VERSION ""

NS_ :

BS_:

BU_:  Battery  Charger  Host

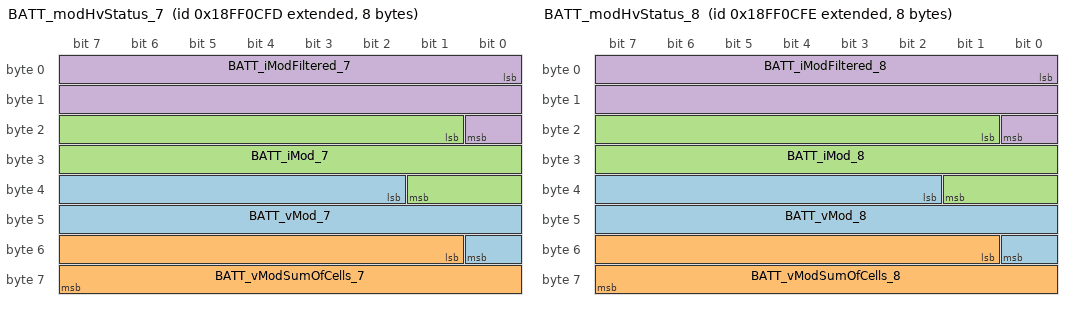
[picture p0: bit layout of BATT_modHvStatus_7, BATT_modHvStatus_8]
BO_ 2566851837 BATT_modHvStatus_7: 8 Battery
 SG_ BATT_vMod_7 : 34|15@1+ (0.01,0) [0|70] "V" Battery,Host
 SG_ BATT_vModSumOfCells_7 : 49|15@1+ (0.01,0) [0|70] "V" Battery,Host
 SG_ BATT_iMod_7 : 17|17@1- (0.01,-400) [-1055.36|255.35] "A" Battery,Host
 SG_ BATT_iModFiltered_7 : 0|17@1- (0.01,-400) [-1055.36|255.35] "A" Battery,Host

BO_ 2566851838 BATT_modHvStatus_8: 8 Battery
 SG_ BATT_vMod_8 : 34|15@1+ (0.01,0) [0|70] "V" Battery,Host
 SG_ BATT_vModSumOfCells_8 : 49|15@1+ (0.01,0) [0|70] "V" Battery,Host
 SG_ BATT_iMod_8 : 17|17@1- (0.01,-400) [-1055.36|255.35] "A" Battery,Host
 SG_ BATT_iModFiltered_8 : 0|17@1- (0.01,-400) [-1055.36|255.35] "A" Battery,Host

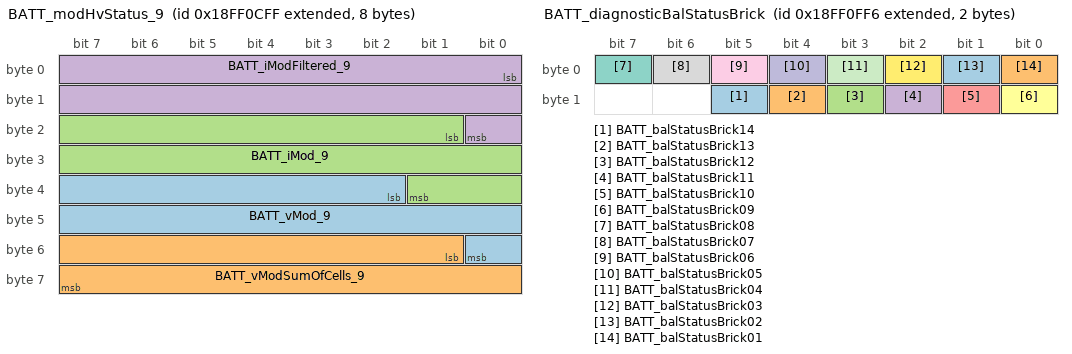
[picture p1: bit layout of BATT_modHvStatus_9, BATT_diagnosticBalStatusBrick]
BO_ 2566851839 BATT_modHvStatus_9: 8 Battery
 SG_ BATT_vMod_9 : 34|15@1+ (0.01,0) [0|70] "V" Battery,Host
 SG_ BATT_vModSumOfCells_9 : 49|15@1+ (0.01,0) [0|70] "V" Battery,Host
 SG_ BATT_iMod_9 : 17|17@1- (0.01,-400) [-1055.36|255.35] "A" Battery,Host
 SG_ BATT_iModFiltered_9 : 0|17@1- (0.01,-400) [-1055.36|255.35] "A" Battery,Host

BO_ 2566852342 BATT_version_0: 8 Battery
 SG_ BATT_bmsVariantCal_0 m2: 56|8@1+ (1,0) [0|255] "V" Host
 SG_ BATT_bmsVariantBl_0 m1: 56|8@1+ (1,0) [0|255] "V" Host
 SG_ BATT_bmsVariantApp_0 m0: 56|8@1+ (1,0) [0|255] "V" Host
 SG_ BATT_swVerSubMinorApp_0 m0: 24|8@1+ (1,0) [0|255] "" Host
 SG_ BATT_swVerMinorApp_0 m0: 16|8@1+ (1,0) [0|255] "" Host
 SG_ BATT_swVerMajorApp_0 m0: 8|8@1+ (1,0) [0|255] "" Host
 SG_ BATT_HwVerApp_0 m0: 32|8@1+ (1,0) [0|255] "" Host
 SG_ BATT_swVerAbsCusApp_0 m0: 40|8@1+ (1,0) [0|255] "" Host
 SG_ BATT_swVerAbsIntApp_0 m0: 48|8@1+ (1,0) [0|255] "" Host
 SG_ BATT_swVerSubMinorBl_0 m1: 24|8@1+ (1,0) [0|255] "" Host
 SG_ BATT_swVerMinorBl_0 m1: 16|8@1+ (1,0) [0|255] "" Host
 SG_ BATT_swVerMajorBl_0 m1: 8|8@1+ (1,0) [0|255] "" Host
 SG_ BATT_HwVerBl_0 m1: 32|8@1+ (1,0) [0|255] "" Host
 SG_ BATT_swVerAbsCusBl_0 m1: 40|8@1+ (1,0) [0|255] "" Host
 SG_ BATT_swVerAbsIntBl_0 m1: 48|8@1+ (1,0) [0|255] "" Host
 SG_ BATT_swVerSubMinorCal_0 m2: 24|8@1+ (1,0) [0|255] "" Host
 SG_ BATT_swVerMinorCal_0 m2: 16|8@1+ (1,0) [0|255] "" Host
 SG_ BATT_swVerMajorCal_0 m2: 8|8@1+ (1,0) [0|255] "" Host
 SG_ BATT_HwVerCal_0 m2: 32|8@1+ (1,0) [0|255] "" Host
 SG_ BATT_swVerAbsCusCal_0 m2: 40|8@1+ (1,0) [0|255] "" Host
 SG_ BATT_swVerAbsIntCal_0 m2: 48|8@1+ (1,0) [0|255] "" Host
 SG_ multiplexorvr_0 M: 0|2@1+ (1,0) [0|2] "" Host

BO_ 2566852343 BATT_version_1: 8 Battery
 SG_ BATT_bmsVariantCal_1 m2: 56|8@1+ (1,0) [0|255] "V" Host
 SG_ BATT_bmsVariantBl_1 m1: 56|8@1+ (1,0) [0|255] "V" Host
 SG_ BATT_bmsVariantApp_1 m0: 56|8@1+ (1,0) [0|255] "V" Host
 SG_ BATT_swVerSubMinorApp_1 m0: 24|8@1+ (1,0) [0|255] "" Host
 SG_ BATT_swVerMinorApp_1 m0: 16|8@1+ (1,0) [0|255] "" Host
 SG_ BATT_swVerMajorApp_1 m0: 8|8@1+ (1,0) [0|255] "" Host
 SG_ BATT_HwVerApp_1 m0: 32|8@1+ (1,0) [0|255] "" Host
 SG_ BATT_swVerAbsCusApp_1 m0: 40|8@1+ (1,0) [0|255] "" Host
 SG_ BATT_swVerAbsIntApp_1 m0: 48|8@1+ (1,0) [0|255] "" Host
 SG_ BATT_swVerSubMinorBl_1 m1: 24|8@1+ (1,0) [0|255] "" Host
 SG_ BATT_swVerMinorBl_1 m1: 16|8@1+ (1,0) [0|255] "" Host
 SG_ BATT_swVerMajorBl_1 m1: 8|8@1+ (1,0) [0|255] "" Host
 SG_ BATT_HwVerBl_1 m1: 32|8@1+ (1,0) [0|255] "" Host
 SG_ BATT_swVerAbsCusBl_1 m1: 40|8@1+ (1,0) [0|255] "" Host
 SG_ BATT_swVerAbsIntBl_1 m1: 48|8@1+ (1,0) [0|255] "" Host
 SG_ BATT_swVerSubMinorCal_1 m2: 24|8@1+ (1,0) [0|255] "" Host
 SG_ BATT_swVerMinorCal_1 m2: 16|8@1+ (1,0) [0|255] "" Host
 SG_ BATT_swVerMajorCal_1 m2: 8|8@1+ (1,0) [0|255] "" Host
 SG_ BATT_HwVerCal_1 m2: 32|8@1+ (1,0) [0|255] "" Host
 SG_ BATT_swVerAbsCusCal_1 m2: 40|8@1+ (1,0) [0|255] "" Host
 SG_ BATT_swVerAbsIntCal_1 m2: 48|8@1+ (1,0) [0|255] "" Host
 SG_ multiplexorvr_1 M: 0|2@1+ (1,0) [0|2] "" Host

BO_ 2566852344 BATT_version_2: 8 Battery
 SG_ BATT_bmsVariantCal_2 m2: 56|8@1+ (1,0) [0|255] "V" Host
 SG_ BATT_bmsVariantBl_2 m1: 56|8@1+ (1,0) [0|255] "V" Host
 SG_ BATT_bmsVariantApp_2 m0: 56|8@1+ (1,0) [0|255] "V" Host
 SG_ BATT_swVerSubMinorApp_2 m0: 24|8@1+ (1,0) [0|255] "" Host
 SG_ BATT_swVerMinorApp_2 m0: 16|8@1+ (1,0) [0|255] "" Host
 SG_ BATT_swVerMajorApp_2 m0: 8|8@1+ (1,0) [0|255] "" Host
 SG_ BATT_HwVerApp_2 m0: 32|8@1+ (1,0) [0|255] "" Host
 SG_ BATT_swVerAbsCusApp_2 m0: 40|8@1+ (1,0) [0|255] "" Host
 SG_ BATT_swVerAbsIntApp_2 m0: 48|8@1+ (1,0) [0|255] "" Host
 SG_ BATT_swVerSubMinorBl_2 m1: 24|8@1+ (1,0) [0|255] "" Host
 SG_ BATT_swVerMinorBl_2 m1: 16|8@1+ (1,0) [0|255] "" Host
 SG_ BATT_swVerMajorBl_2 m1: 8|8@1+ (1,0) [0|255] "" Host
 SG_ BATT_HwVerBl_2 m1: 32|8@1+ (1,0) [0|255] "" Host
 SG_ BATT_swVerAbsCusBl_2 m1: 40|8@1+ (1,0) [0|255] "" Host
 SG_ BATT_swVerAbsIntBl_2 m1: 48|8@1+ (1,0) [0|255] "" Host
 SG_ BATT_swVerSubMinorCal_2 m2: 24|8@1+ (1,0) [0|255] "" Host
 SG_ BATT_swVerMinorCal_2 m2: 16|8@1+ (1,0) [0|255] "" Host
 SG_ BATT_swVerMajorCal_2 m2: 8|8@1+ (1,0) [0|255] "" Host
 SG_ BATT_HwVerCal_2 m2: 32|8@1+ (1,0) [0|255] "" Host
 SG_ BATT_swVerAbsCusCal_2 m2: 40|8@1+ (1,0) [0|255] "" Host
 SG_ BATT_swVerAbsIntCal_2 m2: 48|8@1+ (1,0) [0|255] "" Host
 SG_ multiplexorvr_2 M: 0|2@1+ (1,0) [0|2] "" Host

BO_ 2566852345 BATT_version_3: 8 Battery
 SG_ BATT_bmsVariantCal_3 m2: 56|8@1+ (1,0) [0|255] "V" Host
 SG_ BATT_bmsVariantBl_3 m1: 56|8@1+ (1,0) [0|255] "V" Host
 SG_ BATT_bmsVariantApp_3 m0: 56|8@1+ (1,0) [0|255] "V" Host
 SG_ BATT_swVerSubMinorApp_3 m0: 24|8@1+ (1,0) [0|255] "" Host
 SG_ BATT_swVerMinorApp_3 m0: 16|8@1+ (1,0) [0|255] "" Host
 SG_ BATT_swVerMajorApp_3 m0: 8|8@1+ (1,0) [0|255] "" Host
 SG_ BATT_HwVerApp_3 m0: 32|8@1+ (1,0) [0|255] "" Host
 SG_ BATT_swVerAbsCusApp_3 m0: 40|8@1+ (1,0) [0|255] "" Host
 SG_ BATT_swVerAbsIntApp_3 m0: 48|8@1+ (1,0) [0|255] "" Host
 SG_ BATT_swVerSubMinorBl_3 m1: 24|8@1+ (1,0) [0|255] "" Host
 SG_ BATT_swVerMinorBl_3 m1: 16|8@1+ (1,0) [0|255] "" Host
 SG_ BATT_swVerMajorBl_3 m1: 8|8@1+ (1,0) [0|255] "" Host
 SG_ BATT_HwVerBl_3 m1: 32|8@1+ (1,0) [0|255] "" Host
 SG_ BATT_swVerAbsCusBl_3 m1: 40|8@1+ (1,0) [0|255] "" Host
 SG_ BATT_swVerAbsIntBl_3 m1: 48|8@1+ (1,0) [0|255] "" Host
 SG_ BATT_swVerSubMinorCal_3 m2: 24|8@1+ (1,0) [0|255] "" Host
 SG_ BATT_swVerMinorCal_3 m2: 16|8@1+ (1,0) [0|255] "" Host
 SG_ BATT_swVerMajorCal_3 m2: 8|8@1+ (1,0) [0|255] "" Host
 SG_ BATT_HwVerCal_3 m2: 32|8@1+ (1,0) [0|255] "" Host
 SG_ BATT_swVerAbsCusCal_3 m2: 40|8@1+ (1,0) [0|255] "" Host
 SG_ BATT_swVerAbsIntCal_3 m2: 48|8@1+ (1,0) [0|255] "" Host
 SG_ multiplexorvr_3 M: 0|2@1+ (1,0) [0|2] "" Host

BO_ 2566852346 BATT_version_4: 8 Battery
 SG_ BATT_bmsVariantCal_4 m2: 56|8@1+ (1,0) [0|255] "V" Host
 SG_ BATT_bmsVariantBl_4 m1: 56|8@1+ (1,0) [0|255] "V" Host
 SG_ BATT_bmsVariantApp_4 m0: 56|8@1+ (1,0) [0|255] "V" Host
 SG_ BATT_swVerSubMinorApp_4 m0: 24|8@1+ (1,0) [0|255] "" Host
 SG_ BATT_swVerMinorApp_4 m0: 16|8@1+ (1,0) [0|255] "" Host
 SG_ BATT_swVerMajorApp_4 m0: 8|8@1+ (1,0) [0|255] "" Host
 SG_ BATT_HwVerApp_4 m0: 32|8@1+ (1,0) [0|255] "" Host
 SG_ BATT_swVerAbsCusApp_4 m0: 40|8@1+ (1,0) [0|255] "" Host
 SG_ BATT_swVerAbsIntApp_4 m0: 48|8@1+ (1,0) [0|255] "" Host
 SG_ BATT_swVerSubMinorBl_4 m1: 24|8@1+ (1,0) [0|255] "" Host
 SG_ BATT_swVerMinorBl_4 m1: 16|8@1+ (1,0) [0|255] "" Host
 SG_ BATT_swVerMajorBl_4 m1: 8|8@1+ (1,0) [0|255] "" Host
 SG_ BATT_HwVerBl_4 m1: 32|8@1+ (1,0) [0|255] "" Host
 SG_ BATT_swVerAbsCusBl_4 m1: 40|8@1+ (1,0) [0|255] "" Host
 SG_ BATT_swVerAbsIntBl_4 m1: 48|8@1+ (1,0) [0|255] "" Host
 SG_ BATT_swVerSubMinorCal_4 m2: 24|8@1+ (1,0) [0|255] "" Host
 SG_ BATT_swVerMinorCal_4 m2: 16|8@1+ (1,0) [0|255] "" Host
 SG_ BATT_swVerMajorCal_4 m2: 8|8@1+ (1,0) [0|255] "" Host
 SG_ BATT_HwVerCal_4 m2: 32|8@1+ (1,0) [0|255] "" Host
 SG_ BATT_swVerAbsCusCal_4 m2: 40|8@1+ (1,0) [0|255] "" Host
 SG_ BATT_swVerAbsIntCal_4 m2: 48|8@1+ (1,0) [0|255] "" Host
 SG_ multiplexorvr_4 M: 0|2@1+ (1,0) [0|2] "" Host

BO_ 2566852347 BATT_version_5: 8 Battery
 SG_ BATT_bmsVariantCal_5 m2: 56|8@1+ (1,0) [0|255] "V" Host
 SG_ BATT_bmsVariantBl_5 m1: 56|8@1+ (1,0) [0|255] "V" Host
 SG_ BATT_bmsVariantApp_5 m0: 56|8@1+ (1,0) [0|255] "V" Host
 SG_ BATT_swVerSubMinorApp_5 m0: 24|8@1+ (1,0) [0|255] "" Host
 SG_ BATT_swVerMinorApp_5 m0: 16|8@1+ (1,0) [0|255] "" Host
 SG_ BATT_swVerMajorApp_5 m0: 8|8@1+ (1,0) [0|255] "" Host
 SG_ BATT_HwVerApp_5 m0: 32|8@1+ (1,0) [0|255] "" Host
 SG_ BATT_swVerAbsCusApp_5 m0: 40|8@1+ (1,0) [0|255] "" Host
 SG_ BATT_swVerAbsIntApp_5 m0: 48|8@1+ (1,0) [0|255] "" Host
 SG_ BATT_swVerSubMinorBl_5 m1: 24|8@1+ (1,0) [0|255] "" Host
 SG_ BATT_swVerMinorBl_5 m1: 16|8@1+ (1,0) [0|255] "" Host
 SG_ BATT_swVerMajorBl_5 m1: 8|8@1+ (1,0) [0|255] "" Host
 SG_ BATT_HwVerBl_5 m1: 32|8@1+ (1,0) [0|255] "" Host
 SG_ BATT_swVerAbsCusBl_5 m1: 40|8@1+ (1,0) [0|255] "" Host
 SG_ BATT_swVerAbsIntBl_5 m1: 48|8@1+ (1,0) [0|255] "" Host
 SG_ BATT_swVerSubMinorCal_5 m2: 24|8@1+ (1,0) [0|255] "" Host
 SG_ BATT_swVerMinorCal_5 m2: 16|8@1+ (1,0) [0|255] "" Host
 SG_ BATT_swVerMajorCal_5 m2: 8|8@1+ (1,0) [0|255] "" Host
 SG_ BATT_HwVerCal_5 m2: 32|8@1+ (1,0) [0|255] "" Host
 SG_ BATT_swVerAbsCusCal_5 m2: 40|8@1+ (1,0) [0|255] "" Host
 SG_ BATT_swVerAbsIntCal_5 m2: 48|8@1+ (1,0) [0|255] "" Host
 SG_ multiplexorvr_5 M: 0|2@1+ (1,0) [0|2] "" Host

BO_ 2566852348 BATT_version_6: 8 Battery
 SG_ BATT_bmsVariantCal_6 m2: 56|8@1+ (1,0) [0|255] "V" Host
 SG_ BATT_bmsVariantBl_6 m1: 56|8@1+ (1,0) [0|255] "V" Host
 SG_ BATT_bmsVariantApp_6 m0: 56|8@1+ (1,0) [0|255] "V" Host
 SG_ BATT_swVerSubMinorApp_6 m0: 24|8@1+ (1,0) [0|255] "" Host
 SG_ BATT_swVerMinorApp_6 m0: 16|8@1+ (1,0) [0|255] "" Host
 SG_ BATT_swVerMajorApp_6 m0: 8|8@1+ (1,0) [0|255] "" Host
 SG_ BATT_HwVerApp_6 m0: 32|8@1+ (1,0) [0|255] "" Host
 SG_ BATT_swVerAbsCusApp_6 m0: 40|8@1+ (1,0) [0|255] "" Host
 SG_ BATT_swVerAbsIntApp_6 m0: 48|8@1+ (1,0) [0|255] "" Host
 SG_ BATT_swVerSubMinorBl_6 m1: 24|8@1+ (1,0) [0|255] "" Host
 SG_ BATT_swVerMinorBl_6 m1: 16|8@1+ (1,0) [0|255] "" Host
 SG_ BATT_swVerMajorBl_6 m1: 8|8@1+ (1,0) [0|255] "" Host
 SG_ BATT_HwVerBl_6 m1: 32|8@1+ (1,0) [0|255] "" Host
 SG_ BATT_swVerAbsCusBl_6 m1: 40|8@1+ (1,0) [0|255] "" Host
 SG_ BATT_swVerAbsIntBl_6 m1: 48|8@1+ (1,0) [0|255] "" Host
 SG_ BATT_swVerSubMinorCal_6 m2: 24|8@1+ (1,0) [0|255] "" Host
 SG_ BATT_swVerMinorCal_6 m2: 16|8@1+ (1,0) [0|255] "" Host
 SG_ BATT_swVerMajorCal_6 m2: 8|8@1+ (1,0) [0|255] "" Host
 SG_ BATT_HwVerCal_6 m2: 32|8@1+ (1,0) [0|255] "" Host
 SG_ BATT_swVerAbsCusCal_6 m2: 40|8@1+ (1,0) [0|255] "" Host
 SG_ BATT_swVerAbsIntCal_6 m2: 48|8@1+ (1,0) [0|255] "" Host
 SG_ multiplexorvr_6 M: 0|2@1+ (1,0) [0|2] "" Host

BO_ 2566852349 BATT_version_7: 8 Battery
 SG_ BATT_bmsVariantCal_7 m2: 56|8@1+ (1,0) [0|255] "V" Host
 SG_ BATT_bmsVariantBl_7 m1: 56|8@1+ (1,0) [0|255] "V" Host
 SG_ BATT_bmsVariantApp_7 m0: 56|8@1+ (1,0) [0|255] "V" Host
 SG_ BATT_swVerSubMinorApp_7 m0: 24|8@1+ (1,0) [0|255] "" Host
 SG_ BATT_swVerMinorApp_7 m0: 16|8@1+ (1,0) [0|255] "" Host
 SG_ BATT_swVerMajorApp_7 m0: 8|8@1+ (1,0) [0|255] "" Host
 SG_ BATT_HwVerApp_7 m0: 32|8@1+ (1,0) [0|255] "" Host
 SG_ BATT_swVerAbsCusApp_7 m0: 40|8@1+ (1,0) [0|255] "" Host
 SG_ BATT_swVerAbsIntApp_7 m0: 48|8@1+ (1,0) [0|255] "" Host
 SG_ BATT_swVerSubMinorBl_7 m1: 24|8@1+ (1,0) [0|255] "" Host
 SG_ BATT_swVerMinorBl_7 m1: 16|8@1+ (1,0) [0|255] "" Host
 SG_ BATT_swVerMajorBl_7 m1: 8|8@1+ (1,0) [0|255] "" Host
 SG_ BATT_HwVerBl_7 m1: 32|8@1+ (1,0) [0|255] "" Host
 SG_ BATT_swVerAbsCusBl_7 m1: 40|8@1+ (1,0) [0|255] "" Host
 SG_ BATT_swVerAbsIntBl_7 m1: 48|8@1+ (1,0) [0|255] "" Host
 SG_ BATT_swVerSubMinorCal_7 m2: 24|8@1+ (1,0) [0|255] "" Host
 SG_ BATT_swVerMinorCal_7 m2: 16|8@1+ (1,0) [0|255] "" Host
 SG_ BATT_swVerMajorCal_7 m2: 8|8@1+ (1,0) [0|255] "" Host
 SG_ BATT_HwVerCal_7 m2: 32|8@1+ (1,0) [0|255] "" Host
 SG_ BATT_swVerAbsCusCal_7 m2: 40|8@1+ (1,0) [0|255] "" Host
 SG_ BATT_swVerAbsIntCal_7 m2: 48|8@1+ (1,0) [0|255] "" Host
 SG_ multiplexorvr_7 M: 0|2@1+ (1,0) [0|2] "" Host

BO_ 2566852350 BATT_version_8: 8 Battery
 SG_ BATT_bmsVariantCal_8 m2: 56|8@1+ (1,0) [0|255] "V" Host
 SG_ BATT_bmsVariantBl_8 m1: 56|8@1+ (1,0) [0|255] "V" Host
 SG_ BATT_bmsVariantApp_8 m0: 56|8@1+ (1,0) [0|255] "V" Host
 SG_ BATT_swVerSubMinorApp_8 m0: 24|8@1+ (1,0) [0|255] "" Host
 SG_ BATT_swVerMinorApp_8 m0: 16|8@1+ (1,0) [0|255] "" Host
 SG_ BATT_swVerMajorApp_8 m0: 8|8@1+ (1,0) [0|255] "" Host
 SG_ BATT_HwVerApp_8 m0: 32|8@1+ (1,0) [0|255] "" Host
 SG_ BATT_swVerAbsCusApp_8 m0: 40|8@1+ (1,0) [0|255] "" Host
 SG_ BATT_swVerAbsIntApp_8 m0: 48|8@1+ (1,0) [0|255] "" Host
 SG_ BATT_swVerSubMinorBl_8 m1: 24|8@1+ (1,0) [0|255] "" Host
 SG_ BATT_swVerMinorBl_8 m1: 16|8@1+ (1,0) [0|255] "" Host
 SG_ BATT_swVerMajorBl_8 m1: 8|8@1+ (1,0) [0|255] "" Host
 SG_ BATT_HwVerBl_8 m1: 32|8@1+ (1,0) [0|255] "" Host
 SG_ BATT_swVerAbsCusBl_8 m1: 40|8@1+ (1,0) [0|255] "" Host
 SG_ BATT_swVerAbsIntBl_8 m1: 48|8@1+ (1,0) [0|255] "" Host
 SG_ BATT_swVerSubMinorCal_8 m2: 24|8@1+ (1,0) [0|255] "" Host
 SG_ BATT_swVerMinorCal_8 m2: 16|8@1+ (1,0) [0|255] "" Host
 SG_ BATT_swVerMajorCal_8 m2: 8|8@1+ (1,0) [0|255] "" Host
 SG_ BATT_HwVerCal_8 m2: 32|8@1+ (1,0) [0|255] "" Host
 SG_ BATT_swVerAbsCusCal_8 m2: 40|8@1+ (1,0) [0|255] "" Host
 SG_ BATT_swVerAbsIntCal_8 m2: 48|8@1+ (1,0) [0|255] "" Host
 SG_ multiplexorvr_8 M: 0|2@1+ (1,0) [0|2] "" Host

BO_ 2566852351 BATT_version_9: 8 Battery
 SG_ BATT_bmsVariantCal_9 m2: 56|8@1+ (1,0) [0|255] "V" Host
 SG_ BATT_bmsVariantBl_9 m1: 56|8@1+ (1,0) [0|255] "V" Host
 SG_ BATT_bmsVariantApp_9 m0: 56|8@1+ (1,0) [0|255] "V" Host
 SG_ BATT_swVerSubMinorApp_9 m0: 24|8@1+ (1,0) [0|255] "" Host
 SG_ BATT_swVerMinorApp_9 m0: 16|8@1+ (1,0) [0|255] "" Host
 SG_ BATT_swVerMajorApp_9 m0: 8|8@1+ (1,0) [0|255] "" Host
 SG_ BATT_HwVerApp_9 m0: 32|8@1+ (1,0) [0|255] "" Host
 SG_ BATT_swVerAbsCusApp_9 m0: 40|8@1+ (1,0) [0|255] "" Host
 SG_ BATT_swVerAbsIntApp_9 m0: 48|8@1+ (1,0) [0|255] "" Host
 SG_ BATT_swVerSubMinorBl_9 m1: 24|8@1+ (1,0) [0|255] "" Host
 SG_ BATT_swVerMinorBl_9 m1: 16|8@1+ (1,0) [0|255] "" Host
 SG_ BATT_swVerMajorBl_9 m1: 8|8@1+ (1,0) [0|255] "" Host
 SG_ BATT_HwVerBl_9 m1: 32|8@1+ (1,0) [0|255] "" Host
 SG_ BATT_swVerAbsCusBl_9 m1: 40|8@1+ (1,0) [0|255] "" Host
 SG_ BATT_swVerAbsIntBl_9 m1: 48|8@1+ (1,0) [0|255] "" Host
 SG_ BATT_swVerSubMinorCal_9 m2: 24|8@1+ (1,0) [0|255] "" Host
 SG_ BATT_swVerMinorCal_9 m2: 16|8@1+ (1,0) [0|255] "" Host
 SG_ BATT_swVerMajorCal_9 m2: 8|8@1+ (1,0) [0|255] "" Host
 SG_ BATT_HwVerCal_9 m2: 32|8@1+ (1,0) [0|255] "" Host
 SG_ BATT_swVerAbsCusCal_9 m2: 40|8@1+ (1,0) [0|255] "" Host
 SG_ BATT_swVerAbsIntCal_9 m2: 48|8@1+ (1,0) [0|255] "" Host
 SG_ multiplexorvr_9 M: 0|2@1+ (1,0) [0|2] "" Host

BO_ 2566852598 BATT_diagnosticBalStatusBrick: 2 Battery
 SG_ BATT_balStatusBrick14 : 13|1@1+ (1,0) [0|1] "" Host
 SG_ BATT_balStatusBrick13 : 12|1@1+ (1,0) [0|1] "" Host
 SG_ BATT_balStatusBrick12 : 11|1@1+ (1,0) [0|1] "" Host
 SG_ BATT_balStatusBrick11 : 10|1@1+ (1,0) [0|1] "" Host
 SG_ BATT_balStatusBrick10 : 9|1@1+ (1,0) [0|1] "" Host
 SG_ BATT_balStatusBrick09 : 8|1@1+ (1,0) [0|1] "" Host
 SG_ BATT_balStatusBrick08 : 7|1@1+ (1,0) [0|1] "" Host
 SG_ BATT_balStatusBrick07 : 6|1@1+ (1,0) [0|1] "" Host
 SG_ BATT_balStatusBrick06 : 5|1@1+ (1,0) [0|1] "" Host
 SG_ BATT_balStatusBrick05 : 4|1@1+ (1,0) [0|1] "" Host
 SG_ BATT_balStatusBrick04 : 3|1@1+ (1,0) [0|1] "" Host
 SG_ BATT_balStatusBrick03 : 2|1@1+ (1,0) [0|1] "" Host
 SG_ BATT_balStatusBrick02 : 1|1@1+ (1,0) [0|1] "" Host
 SG_ BATT_balStatusBrick01 : 0|1@1+ (1,0) [0|1] "" Host

BO_ 2566852854 BATT_eventMatrix_A_0: 8 Battery
 SG_ BATT_packModIdFault_0 : 8|1@1+ (1,0) [0|1] "" Host
 SG_ BATT_packModExitedFromBus_0 : 16|1@1+ (1,0) [0|1] "" Host
 SG_ BATT_packFetChgWelded_0 : 35|1@1+ (1,0) [0|1] "" Host
 SG_ BATT_packFetDsgWelded_0 : 36|1@1+ (1,0) [0|1] "" Host
 SG_ BATT_fetDsgShortedAux_0 : 63|1@1+ (1,0) [0|1] "" Host
 SG_ BATT_fetChgShortedAux_0 : 25|1@1+ (1,0) [0|1] "" Host
 SG_ BATT_prechargeFetFail_0 : 39|1@1+ (1,0) [0|1] "" Host
 SG_ BATT_abnormalResetReason_0 : 31|1@1+ (1,0) [0|1] "" Host
 SG_ BATT_prechargeTooSlow_0 : 49|1@1+ (1,0) [0|1] "" Host
 SG_ BATT_prechargeTooFast_0 : 50|1@1+ (1,0) [0|1] "" Host
 SG_ BATT_prechargeTimeout_0 : 51|1@1+ (1,0) [0|1] "" Host
 SG_ BATT_fetChgShorted_0 : 23|1@1+ (1,0) [0|1] "" Host
 SG_ BATT_fetChgFailToClose_0 : 22|1@1+ (1,0) [0|1] "" Host
 SG_ BATT_packModSelectFault_0 : 21|1@1+ (1,0) [0|1] "" Host
 SG_ BATT_packModConnectFault_0 : 20|1@1+ (1,0) [0|1] "" Host
 SG_ BATT_packModMIA_0 : 19|1@1+ (1,0) [0|1] "" Host
 SG_ BATT_packModImbalance_0 : 18|1@1+ (1,0) [0|1] "" Host
 SG_ BATT_afeFault_0 : 17|1@1+ (1,0) [0|1] "" Host
 SG_ BATT_chargerMIA_0 : 60|1@1+ (1,0) [0|1] "" Host
 SG_ BATT_chargerError_0 : 59|1@1+ (1,0) [0|1] "" Host
 SG_ BATT_vBrickUnderWar_0 : 58|1@1+ (1,0) [0|1] "" Host
 SG_ BATT_vBrickUnderSev_0 : 57|1@1+ (1,0) [0|1] "" Host
 SG_ BATT_vBrickUnderMod_0 : 56|1@1+ (1,0) [0|1] "" Host
 SG_ BATT_vBrickOverWar_0 : 55|1@1+ (1,0) [0|1] "" Host
 SG_ BATT_vBrickOverSev_0 : 54|1@1+ (1,0) [0|1] "" Host
 SG_ BATT_vBrickOverMod_0 : 53|1@1+ (1,0) [0|1] "" Host
 SG_ BATT_vBrickImbalance_0 : 52|1@1+ (1,0) [0|1] "" Host
 SG_ BATT_loggerAlmostFull_0 : 61|1@1+ (1,0) [0|1] "" Host
 SG_ BATT_tempModuleUnderWar_0 : 48|1@1+ (1,0) [0|1] "" Host
 SG_ BATT_tempModuleUnderSev_0 : 47|1@1+ (1,0) [0|1] "" Host
 SG_ BATT_tempModuleUnderMod_0 : 46|1@1+ (1,0) [0|1] "" Host
 SG_ BATT_tempModuleOverWar_0 : 45|1@1+ (1,0) [0|1] "" Host
 SG_ BATT_tempModuleOverSev_0 : 44|1@1+ (1,0) [0|1] "" Host
 SG_ BATT_tempModuleOverMod_0 : 43|1@1+ (1,0) [0|1] "" Host
 SG_ BATT_tempBrickImbalance_0 : 42|1@1+ (1,0) [0|1] "" Host
 SG_ BATT_taskLockupError_0 : 41|1@1+ (1,0) [0|1] "" Host
 SG_ BATT_tempBoardOverWar_0 : 40|1@1+ (1,0) [0|1] "" Host
 SG_ BATT_tempBoardOverSev_0 : 38|1@1+ (1,0) [0|1] "" Host
 SG_ BATT_tempBoardOverMod_0 : 37|1@1+ (1,0) [0|1] "" Host
 SG_ BATT_sensePackVoltError_0 : 34|1@1+ (1,0) [0|1] "" Host
 SG_ BATT_senseLoadVoltError_0 : 33|1@1+ (1,0) [0|1] "" Host
 SG_ BATT_loggerFull_0 : 62|1@1+ (1,0) [0|1] "" Host
 SG_ BATT_senseCurrentError_0 : 32|1@1+ (1,0) [0|1] "" Host
 SG_ BATT_senseBrickTempError_0 : 30|1@1+ (1,0) [0|1] "" Host
 SG_ BATT_resPackHigh_0 : 29|1@1+ (1,0) [0|1] "" Host
 SG_ BATT_ramOverUtilError_0 : 28|1@1+ (1,0) [0|1] "" Host
 SG_ BATT_powerPackInsufficient_0 : 27|1@1+ (1,0) [0|1] "" Host
 SG_ BATT_packCellSoftShort_0 : 26|1@1+ (1,0) [0|1] "" Host
 SG_ BATT_iOverHardware_0 : 24|1@1+ (1,0) [0|1] "" Host
 SG_ BATT_fetOverTemp_0 : 15|1@1+ (1,0) [0|1] "" Host
 SG_ BATT_iOverDischarge_0 : 14|1@1+ (1,0) [0|1] "" Host
 SG_ BATT_iOverCharge_0 : 13|1@1+ (1,0) [0|1] "" Host
 SG_ BATT_inverterDriveMIA_0 : 12|1@1+ (1,0) [0|1] "" Host
 SG_ BATT_iUnderCharge_0 : 11|1@1+ (1,0) [0|1] "" Host
 SG_ BATT_hostMIA_0 : 10|1@1+ (1,0) [0|1] "" Host
 SG_ BATT_fetDsgShorted_0 : 7|1@1+ (1,0) [0|1] "" Host
 SG_ BATT_fetDsgFailToClose_0 : 6|1@1+ (1,0) [0|1] "" Host
 SG_ BATT_capLow_0 : 5|1@1+ (1,0) [0|1] "" Host
 SG_ BATT_brickOverDischarge_0 : 4|1@1+ (1,0) [0|1] "" Host
 SG_ BATT_brickOverCharge_0 : 3|1@1+ (1,0) [0|1] "" Host
 SG_ BATT_bmsProcessorError_0 : 2|1@1+ (1,0) [0|1] "" Host
 SG_ BATT_bmsMemoryError_0 : 1|1@1+ (1,0) [0|1] "" Host
 SG_ BATT_afeError_0 : 0|1@1+ (1,0) [0|1] "" Host

BO_ 2566852855 BATT_eventMatrix_A_1: 8 Battery
 SG_ BATT_packModIdFault_1 : 8|1@1+ (1,0) [0|1] "" Host
 SG_ BATT_packModExitedFromBus_1 : 16|1@1+ (1,0) [0|1] "" Host
 SG_ BATT_packFetChgWelded_1 : 35|1@1+ (1,0) [0|1] "" Host
 SG_ BATT_packFetDsgWelded_1 : 36|1@1+ (1,0) [0|1] "" Host
 SG_ BATT_fetDsgShortedAux_1 : 63|1@1+ (1,0) [0|1] "" Host
 SG_ BATT_fetChgShortedAux_1 : 25|1@1+ (1,0) [0|1] "" Host
 SG_ BATT_prechargeFetFail_1 : 39|1@1+ (1,0) [0|1] "" Host
 SG_ BATT_abnormalResetReason_1 : 31|1@1+ (1,0) [0|1] "" Host
 SG_ BATT_prechargeTooSlow_1 : 49|1@1+ (1,0) [0|1] "" Host
 SG_ BATT_prechargeTooFast_1 : 50|1@1+ (1,0) [0|1] "" Host
 SG_ BATT_prechargeTimeout_1 : 51|1@1+ (1,0) [0|1] "" Host
 SG_ BATT_fetChgShorted_1 : 23|1@1+ (1,0) [0|1] "" Host
 SG_ BATT_fetChgFailToClose_1 : 22|1@1+ (1,0) [0|1] "" Host
 SG_ BATT_packModSelectFault_1 : 21|1@1+ (1,0) [0|1] "" Host
 SG_ BATT_packModConnectFault_1 : 20|1@1+ (1,0) [0|1] "" Host
 SG_ BATT_packModMIA_1 : 19|1@1+ (1,0) [0|1] "" Host
 SG_ BATT_packModImbalance_1 : 18|1@1+ (1,0) [0|1] "" Host
 SG_ BATT_afeFault_1 : 17|1@1+ (1,0) [0|1] "" Host
 SG_ BATT_chargerMIA_1 : 60|1@1+ (1,0) [0|1] "" Host
 SG_ BATT_chargerError_1 : 59|1@1+ (1,0) [0|1] "" Host
 SG_ BATT_vBrickUnderWar_1 : 58|1@1+ (1,0) [0|1] "" Host
 SG_ BATT_vBrickUnderSev_1 : 57|1@1+ (1,0) [0|1] "" Host
 SG_ BATT_vBrickUnderMod_1 : 56|1@1+ (1,0) [0|1] "" Host
 SG_ BATT_vBrickOverWar_1 : 55|1@1+ (1,0) [0|1] "" Host
 SG_ BATT_vBrickOverSev_1 : 54|1@1+ (1,0) [0|1] "" Host
 SG_ BATT_vBrickOverMod_1 : 53|1@1+ (1,0) [0|1] "" Host
 SG_ BATT_vBrickImbalance_1 : 52|1@1+ (1,0) [0|1] "" Host
 SG_ BATT_loggerAlmostFull_1 : 61|1@1+ (1,0) [0|1] "" Host
 SG_ BATT_tempModuleUnderWar_1 : 48|1@1+ (1,0) [0|1] "" Host
 SG_ BATT_tempModuleUnderSev_1 : 47|1@1+ (1,0) [0|1] "" Host
 SG_ BATT_tempModuleUnderMod_1 : 46|1@1+ (1,0) [0|1] "" Host
 SG_ BATT_tempModuleOverWar_1 : 45|1@1+ (1,0) [0|1] "" Host
 SG_ BATT_tempModuleOverSev_1 : 44|1@1+ (1,0) [0|1] "" Host
 SG_ BATT_tempModuleOverMod_1 : 43|1@1+ (1,0) [0|1] "" Host
 SG_ BATT_tempBrickImbalance_1 : 42|1@1+ (1,0) [0|1] "" Host
 SG_ BATT_taskLockupError_1 : 41|1@1+ (1,0) [0|1] "" Host
 SG_ BATT_tempBoardOverWar_1 : 40|1@1+ (1,0) [0|1] "" Host
 SG_ BATT_tempBoardOverSev_1 : 38|1@1+ (1,0) [0|1] "" Host
 SG_ BATT_tempBoardOverMod_1 : 37|1@1+ (1,0) [0|1] "" Host
 SG_ BATT_sensePackVoltError_1 : 34|1@1+ (1,0) [0|1] "" Host
 SG_ BATT_senseLoadVoltError_1 : 33|1@1+ (1,0) [0|1] "" Host
 SG_ BATT_loggerFull_1 : 62|1@1+ (1,0) [0|1] "" Host
 SG_ BATT_senseCurrentError_1 : 32|1@1+ (1,0) [0|1] "" Host
 SG_ BATT_senseBrickTempError_1 : 30|1@1+ (1,0) [0|1] "" Host
 SG_ BATT_resPackHigh_1 : 29|1@1+ (1,0) [0|1] "" Host
 SG_ BATT_ramOverUtilError_1 : 28|1@1+ (1,0) [0|1] "" Host
 SG_ BATT_powerPackInsufficient_1 : 27|1@1+ (1,0) [0|1] "" Host
 SG_ BATT_packCellSoftShort_1 : 26|1@1+ (1,0) [0|1] "" Host
 SG_ BATT_iOverHardware_1 : 24|1@1+ (1,0) [0|1] "" Host
 SG_ BATT_fetOverTemp_1 : 15|1@1+ (1,0) [0|1] "" Host
 SG_ BATT_iOverDischarge_1 : 14|1@1+ (1,0) [0|1] "" Host
 SG_ BATT_iOverCharge_1 : 13|1@1+ (1,0) [0|1] "" Host
 SG_ BATT_inverterDriveMIA_1 : 12|1@1+ (1,0) [0|1] "" Host
 SG_ BATT_iUnderCharge_1 : 11|1@1+ (1,0) [0|1] "" Host
 SG_ BATT_hostMIA_1 : 10|1@1+ (1,0) [0|1] "" Host
 SG_ BATT_fetDsgShorted_1 : 7|1@1+ (1,0) [0|1] "" Host
 SG_ BATT_fetDsgFailToClose_1 : 6|1@1+ (1,0) [0|1] "" Host
 SG_ BATT_capLow_1 : 5|1@1+ (1,0) [0|1] "" Host
 SG_ BATT_brickOverDischarge_1 : 4|1@1+ (1,0) [0|1] "" Host
 SG_ BATT_brickOverCharge_1 : 3|1@1+ (1,0) [0|1] "" Host
 SG_ BATT_bmsProcessorError_1 : 2|1@1+ (1,0) [0|1] "" Host
 SG_ BATT_bmsMemoryError_1 : 1|1@1+ (1,0) [0|1] "" Host
 SG_ BATT_afeError_1 : 0|1@1+ (1,0) [0|1] "" Host

BO_ 2566852856 BATT_eventMatrix_A_2: 8 Battery
 SG_ BATT_packModIdFault_2 : 8|1@1+ (1,0) [0|1] "" Host
 SG_ BATT_packModExitedFromBus_2 : 16|1@1+ (1,0) [0|1] "" Host
 SG_ BATT_packFetChgWelded_2 : 35|1@1+ (1,0) [0|1] "" Host
 SG_ BATT_packFetDsgWelded_2 : 36|1@1+ (1,0) [0|1] "" Host
 SG_ BATT_fetDsgShortedAux_2 : 63|1@1+ (1,0) [0|1] "" Host
 SG_ BATT_fetChgShortedAux_2 : 25|1@1+ (1,0) [0|1] "" Host
 SG_ BATT_prechargeFetFail_2 : 39|1@1+ (1,0) [0|1] "" Host
 SG_ BATT_abnormalResetReason_2 : 31|1@1+ (1,0) [0|1] "" Host
 SG_ BATT_prechargeTooSlow_2 : 49|1@1+ (1,0) [0|1] "" Host
 SG_ BATT_prechargeTooFast_2 : 50|1@1+ (1,0) [0|1] "" Host
 SG_ BATT_prechargeTimeout_2 : 51|1@1+ (1,0) [0|1] "" Host
 SG_ BATT_fetChgShorted_2 : 23|1@1+ (1,0) [0|1] "" Host
 SG_ BATT_fetChgFailToClose_2 : 22|1@1+ (1,0) [0|1] "" Host
 SG_ BATT_packModSelectFault_2 : 21|1@1+ (1,0) [0|1] "" Host
 SG_ BATT_packModConnectFault_2 : 20|1@1+ (1,0) [0|1] "" Host
 SG_ BATT_packModMIA_2 : 19|1@1+ (1,0) [0|1] "" Host
 SG_ BATT_packModImbalance_2 : 18|1@1+ (1,0) [0|1] "" Host
 SG_ BATT_afeFault_2 : 17|1@1+ (1,0) [0|1] "" Host
 SG_ BATT_chargerMIA_2 : 60|1@1+ (1,0) [0|1] "" Host
 SG_ BATT_chargerError_2 : 59|1@1+ (1,0) [0|1] "" Host
 SG_ BATT_vBrickUnderWar_2 : 58|1@1+ (1,0) [0|1] "" Host
 SG_ BATT_vBrickUnderSev_2 : 57|1@1+ (1,0) [0|1] "" Host
 SG_ BATT_vBrickUnderMod_2 : 56|1@1+ (1,0) [0|1] "" Host
 SG_ BATT_vBrickOverWar_2 : 55|1@1+ (1,0) [0|1] "" Host
 SG_ BATT_vBrickOverSev_2 : 54|1@1+ (1,0) [0|1] "" Host
 SG_ BATT_vBrickOverMod_2 : 53|1@1+ (1,0) [0|1] "" Host
 SG_ BATT_vBrickImbalance_2 : 52|1@1+ (1,0) [0|1] "" Host
 SG_ BATT_loggerAlmostFull_2 : 61|1@1+ (1,0) [0|1] "" Host
 SG_ BATT_tempModuleUnderWar_2 : 48|1@1+ (1,0) [0|1] "" Host
 SG_ BATT_tempModuleUnderSev_2 : 47|1@1+ (1,0) [0|1] "" Host
 SG_ BATT_tempModuleUnderMod_2 : 46|1@1+ (1,0) [0|1] "" Host
 SG_ BATT_tempModuleOverWar_2 : 45|1@1+ (1,0) [0|1] "" Host
 SG_ BATT_tempModuleOverSev_2 : 44|1@1+ (1,0) [0|1] "" Host
 SG_ BATT_tempModuleOverMod_2 : 43|1@1+ (1,0) [0|1] "" Host
 SG_ BATT_tempBrickImbalance_2 : 42|1@1+ (1,0) [0|1] "" Host
 SG_ BATT_taskLockupError_2 : 41|1@1+ (1,0) [0|1] "" Host
 SG_ BATT_tempBoardOverWar_2 : 40|1@1+ (1,0) [0|1] "" Host
 SG_ BATT_tempBoardOverSev_2 : 38|1@1+ (1,0) [0|1] "" Host
 SG_ BATT_tempBoardOverMod_2 : 37|1@1+ (1,0) [0|1] "" Host
 SG_ BATT_sensePackVoltError_2 : 34|1@1+ (1,0) [0|1] "" Host
 SG_ BATT_senseLoadVoltError_2 : 33|1@1+ (1,0) [0|1] "" Host
 SG_ BATT_loggerFull_2 : 62|1@1+ (1,0) [0|1] "" Host
 SG_ BATT_senseCurrentError_2 : 32|1@1+ (1,0) [0|1] "" Host
 SG_ BATT_senseBrickTempError_2 : 30|1@1+ (1,0) [0|1] "" Host
 SG_ BATT_resPackHigh_2 : 29|1@1+ (1,0) [0|1] "" Host
 SG_ BATT_ramOverUtilError_2 : 28|1@1+ (1,0) [0|1] "" Host
 SG_ BATT_powerPackInsufficient_2 : 27|1@1+ (1,0) [0|1] "" Host
 SG_ BATT_packCellSoftShort_2 : 26|1@1+ (1,0) [0|1] "" Host
 SG_ BATT_iOverHardware_2 : 24|1@1+ (1,0) [0|1] "" Host
 SG_ BATT_fetOverTemp_2 : 15|1@1+ (1,0) [0|1] "" Host
 SG_ BATT_iOverDischarge_2 : 14|1@1+ (1,0) [0|1] "" Host
 SG_ BATT_iOverCharge_2 : 13|1@1+ (1,0) [0|1] "" Host
 SG_ BATT_inverterDriveMIA_2 : 12|1@1+ (1,0) [0|1] "" Host
 SG_ BATT_iUnderCharge_2 : 11|1@1+ (1,0) [0|1] "" Host
 SG_ BATT_hostMIA_2 : 10|1@1+ (1,0) [0|1] "" Host
 SG_ BATT_fetDsgShorted_2 : 7|1@1+ (1,0) [0|1] "" Host
 SG_ BATT_fetDsgFailToClose_2 : 6|1@1+ (1,0) [0|1] "" Host
 SG_ BATT_capLow_2 : 5|1@1+ (1,0) [0|1] "" Host
 SG_ BATT_brickOverDischarge_2 : 4|1@1+ (1,0) [0|1] "" Host
 SG_ BATT_brickOverCharge_2 : 3|1@1+ (1,0) [0|1] "" Host
 SG_ BATT_bmsProcessorError_2 : 2|1@1+ (1,0) [0|1] "" Host
 SG_ BATT_bmsMemoryError_2 : 1|1@1+ (1,0) [0|1] "" Host
 SG_ BATT_afeError_2 : 0|1@1+ (1,0) [0|1] "" Host

BO_ 2566852857 BATT_eventMatrix_A_3: 8 Battery
 SG_ BATT_packModIdFault_3 : 8|1@1+ (1,0) [0|1] "" Host
 SG_ BATT_packModExitedFromBus_3 : 16|1@1+ (1,0) [0|1] "" Host
 SG_ BATT_packFetChgWelded_3 : 35|1@1+ (1,0) [0|1] "" Host
 SG_ BATT_packFetDsgWelded_3 : 36|1@1+ (1,0) [0|1] "" Host
 SG_ BATT_fetDsgShortedAux_3 : 63|1@1+ (1,0) [0|1] "" Host
 SG_ BATT_fetChgShortedAux_3 : 25|1@1+ (1,0) [0|1] "" Host
 SG_ BATT_prechargeFetFail_3 : 39|1@1+ (1,0) [0|1] "" Host
 SG_ BATT_abnormalResetReason_3 : 31|1@1+ (1,0) [0|1] "" Host
 SG_ BATT_prechargeTooSlow_3 : 49|1@1+ (1,0) [0|1] "" Host
 SG_ BATT_prechargeTooFast_3 : 50|1@1+ (1,0) [0|1] "" Host
 SG_ BATT_prechargeTimeout_3 : 51|1@1+ (1,0) [0|1] "" Host
 SG_ BATT_fetChgShorted_3 : 23|1@1+ (1,0) [0|1] "" Host
 SG_ BATT_fetChgFailToClose_3 : 22|1@1+ (1,0) [0|1] "" Host
 SG_ BATT_packModSelectFault_3 : 21|1@1+ (1,0) [0|1] "" Host
 SG_ BATT_packModConnectFault_3 : 20|1@1+ (1,0) [0|1] "" Host
 SG_ BATT_packModMIA_3 : 19|1@1+ (1,0) [0|1] "" Host
 SG_ BATT_packModImbalance_3 : 18|1@1+ (1,0) [0|1] "" Host
 SG_ BATT_afeFault_3 : 17|1@1+ (1,0) [0|1] "" Host
 SG_ BATT_chargerMIA_3 : 60|1@1+ (1,0) [0|1] "" Host
 SG_ BATT_chargerError_3 : 59|1@1+ (1,0) [0|1] "" Host
 SG_ BATT_vBrickUnderWar_3 : 58|1@1+ (1,0) [0|1] "" Host
 SG_ BATT_vBrickUnderSev_3 : 57|1@1+ (1,0) [0|1] "" Host
 SG_ BATT_vBrickUnderMod_3 : 56|1@1+ (1,0) [0|1] "" Host
 SG_ BATT_vBrickOverWar_3 : 55|1@1+ (1,0) [0|1] "" Host
 SG_ BATT_vBrickOverSev_3 : 54|1@1+ (1,0) [0|1] "" Host
 SG_ BATT_vBrickOverMod_3 : 53|1@1+ (1,0) [0|1] "" Host
 SG_ BATT_vBrickImbalance_3 : 52|1@1+ (1,0) [0|1] "" Host
 SG_ BATT_loggerAlmostFull_3 : 61|1@1+ (1,0) [0|1] "" Host
 SG_ BATT_tempModuleUnderWar_3 : 48|1@1+ (1,0) [0|1] "" Host
 SG_ BATT_tempModuleUnderSev_3 : 47|1@1+ (1,0) [0|1] "" Host
 SG_ BATT_tempModuleUnderMod_3 : 46|1@1+ (1,0) [0|1] "" Host
 SG_ BATT_tempModuleOverWar_3 : 45|1@1+ (1,0) [0|1] "" Host
 SG_ BATT_tempModuleOverSev_3 : 44|1@1+ (1,0) [0|1] "" Host
 SG_ BATT_tempModuleOverMod_3 : 43|1@1+ (1,0) [0|1] "" Host
 SG_ BATT_tempBrickImbalance_3 : 42|1@1+ (1,0) [0|1] "" Host
 SG_ BATT_taskLockupError_3 : 41|1@1+ (1,0) [0|1] "" Host
 SG_ BATT_tempBoardOverWar_3 : 40|1@1+ (1,0) [0|1] "" Host
 SG_ BATT_tempBoardOverSev_3 : 38|1@1+ (1,0) [0|1] "" Host
 SG_ BATT_tempBoardOverMod_3 : 37|1@1+ (1,0) [0|1] "" Host
 SG_ BATT_sensePackVoltError_3 : 34|1@1+ (1,0) [0|1] "" Host
 SG_ BATT_senseLoadVoltError_3 : 33|1@1+ (1,0) [0|1] "" Host
 SG_ BATT_loggerFull_3 : 62|1@1+ (1,0) [0|1] "" Host
 SG_ BATT_senseCurrentError_3 : 32|1@1+ (1,0) [0|1] "" Host
 SG_ BATT_senseBrickTempError_3 : 30|1@1+ (1,0) [0|1] "" Host
 SG_ BATT_resPackHigh_3 : 29|1@1+ (1,0) [0|1] "" Host
 SG_ BATT_ramOverUtilError_3 : 28|1@1+ (1,0) [0|1] "" Host
 SG_ BATT_powerPackInsufficient_3 : 27|1@1+ (1,0) [0|1] "" Host
 SG_ BATT_packCellSoftShort_3 : 26|1@1+ (1,0) [0|1] "" Host
 SG_ BATT_iOverHardware_3 : 24|1@1+ (1,0) [0|1] "" Host
 SG_ BATT_fetOverTemp_3 : 15|1@1+ (1,0) [0|1] "" Host
 SG_ BATT_iOverDischarge_3 : 14|1@1+ (1,0) [0|1] "" Host
 SG_ BATT_iOverCharge_3 : 13|1@1+ (1,0) [0|1] "" Host
 SG_ BATT_inverterDriveMIA_3 : 12|1@1+ (1,0) [0|1] "" Host
 SG_ BATT_iUnderCharge_3 : 11|1@1+ (1,0) [0|1] "" Host
 SG_ BATT_hostMIA_3 : 10|1@1+ (1,0) [0|1] "" Host
 SG_ BATT_fetDsgShorted_3 : 7|1@1+ (1,0) [0|1] "" Host
 SG_ BATT_fetDsgFailToClose_3 : 6|1@1+ (1,0) [0|1] "" Host
 SG_ BATT_capLow_3 : 5|1@1+ (1,0) [0|1] "" Host
 SG_ BATT_brickOverDischarge_3 : 4|1@1+ (1,0) [0|1] "" Host
 SG_ BATT_brickOverCharge_3 : 3|1@1+ (1,0) [0|1] "" Host
 SG_ BATT_bmsProcessorError_3 : 2|1@1+ (1,0) [0|1] "" Host
 SG_ BATT_bmsMemoryError_3 : 1|1@1+ (1,0) [0|1] "" Host
 SG_ BATT_afeError_3 : 0|1@1+ (1,0) [0|1] "" Host

BO_ 2566852858 BATT_eventMatrix_A_4: 8 Battery
 SG_ BATT_packModIdFault_4 : 8|1@1+ (1,0) [0|1] "" Host
 SG_ BATT_packModExitedFromBus_4 : 16|1@1+ (1,0) [0|1] "" Host
 SG_ BATT_packFetChgWelded_4 : 35|1@1+ (1,0) [0|1] "" Host
 SG_ BATT_packFetDsgWelded_4 : 36|1@1+ (1,0) [0|1] "" Host
 SG_ BATT_fetDsgShortedAux_4 : 63|1@1+ (1,0) [0|1] "" Host
 SG_ BATT_fetChgShortedAux_4 : 25|1@1+ (1,0) [0|1] "" Host
 SG_ BATT_prechargeFetFail_4 : 39|1@1+ (1,0) [0|1] "" Host
 SG_ BATT_abnormalResetReason_4 : 31|1@1+ (1,0) [0|1] "" Host
 SG_ BATT_prechargeTooSlow_4 : 49|1@1+ (1,0) [0|1] "" Host
 SG_ BATT_prechargeTooFast_4 : 50|1@1+ (1,0) [0|1] "" Host
 SG_ BATT_prechargeTimeout_4 : 51|1@1+ (1,0) [0|1] "" Host
 SG_ BATT_fetChgShorted_4 : 23|1@1+ (1,0) [0|1] "" Host
 SG_ BATT_fetChgFailToClose_4 : 22|1@1+ (1,0) [0|1] "" Host
 SG_ BATT_packModSelectFault_4 : 21|1@1+ (1,0) [0|1] "" Host
 SG_ BATT_packModConnectFault_4 : 20|1@1+ (1,0) [0|1] "" Host
 SG_ BATT_packModMIA_4 : 19|1@1+ (1,0) [0|1] "" Host
 SG_ BATT_packModImbalance_4 : 18|1@1+ (1,0) [0|1] "" Host
 SG_ BATT_afeFault_4 : 17|1@1+ (1,0) [0|1] "" Host
 SG_ BATT_chargerMIA_4 : 60|1@1+ (1,0) [0|1] "" Host
 SG_ BATT_chargerError_4 : 59|1@1+ (1,0) [0|1] "" Host
 SG_ BATT_vBrickUnderWar_4 : 58|1@1+ (1,0) [0|1] "" Host
 SG_ BATT_vBrickUnderSev_4 : 57|1@1+ (1,0) [0|1] "" Host
 SG_ BATT_vBrickUnderMod_4 : 56|1@1+ (1,0) [0|1] "" Host
 SG_ BATT_vBrickOverWar_4 : 55|1@1+ (1,0) [0|1] "" Host
 SG_ BATT_vBrickOverSev_4 : 54|1@1+ (1,0) [0|1] "" Host
 SG_ BATT_vBrickOverMod_4 : 53|1@1+ (1,0) [0|1] "" Host
 SG_ BATT_vBrickImbalance_4 : 52|1@1+ (1,0) [0|1] "" Host
 SG_ BATT_loggerAlmostFull_4 : 61|1@1+ (1,0) [0|1] "" Host
 SG_ BATT_tempModuleUnderWar_4 : 48|1@1+ (1,0) [0|1] "" Host
 SG_ BATT_tempModuleUnderSev_4 : 47|1@1+ (1,0) [0|1] "" Host
 SG_ BATT_tempModuleUnderMod_4 : 46|1@1+ (1,0) [0|1] "" Host
 SG_ BATT_tempModuleOverWar_4 : 45|1@1+ (1,0) [0|1] "" Host
 SG_ BATT_tempModuleOverSev_4 : 44|1@1+ (1,0) [0|1] "" Host
 SG_ BATT_tempModuleOverMod_4 : 43|1@1+ (1,0) [0|1] "" Host
 SG_ BATT_tempBrickImbalance_4 : 42|1@1+ (1,0) [0|1] "" Host
 SG_ BATT_taskLockupError_4 : 41|1@1+ (1,0) [0|1] "" Host
 SG_ BATT_tempBoardOverWar_4 : 40|1@1+ (1,0) [0|1] "" Host
 SG_ BATT_tempBoardOverSev_4 : 38|1@1+ (1,0) [0|1] "" Host
 SG_ BATT_tempBoardOverMod_4 : 37|1@1+ (1,0) [0|1] "" Host
 SG_ BATT_sensePackVoltError_4 : 34|1@1+ (1,0) [0|1] "" Host
 SG_ BATT_senseLoadVoltError_4 : 33|1@1+ (1,0) [0|1] "" Host
 SG_ BATT_loggerFull_4 : 62|1@1+ (1,0) [0|1] "" Host
 SG_ BATT_senseCurrentError_4 : 32|1@1+ (1,0) [0|1] "" Host
 SG_ BATT_senseBrickTempError_4 : 30|1@1+ (1,0) [0|1] "" Host
 SG_ BATT_resPackHigh_4 : 29|1@1+ (1,0) [0|1] "" Host
 SG_ BATT_ramOverUtilError_4 : 28|1@1+ (1,0) [0|1] "" Host
 SG_ BATT_powerPackInsufficient_4 : 27|1@1+ (1,0) [0|1] "" Host
 SG_ BATT_packCellSoftShort_4 : 26|1@1+ (1,0) [0|1] "" Host
 SG_ BATT_iOverHardware_4 : 24|1@1+ (1,0) [0|1] "" Host
 SG_ BATT_fetOverTemp_4 : 15|1@1+ (1,0) [0|1] "" Host
 SG_ BATT_iOverDischarge_4 : 14|1@1+ (1,0) [0|1] "" Host
 SG_ BATT_iOverCharge_4 : 13|1@1+ (1,0) [0|1] "" Host
 SG_ BATT_inverterDriveMIA_4 : 12|1@1+ (1,0) [0|1] "" Host
 SG_ BATT_iUnderCharge_4 : 11|1@1+ (1,0) [0|1] "" Host
 SG_ BATT_hostMIA_4 : 10|1@1+ (1,0) [0|1] "" Host
 SG_ BATT_fetDsgShorted_4 : 7|1@1+ (1,0) [0|1] "" Host
 SG_ BATT_fetDsgFailToClose_4 : 6|1@1+ (1,0) [0|1] "" Host
 SG_ BATT_capLow_4 : 5|1@1+ (1,0) [0|1] "" Host
 SG_ BATT_brickOverDischarge_4 : 4|1@1+ (1,0) [0|1] "" Host
 SG_ BATT_brickOverCharge_4 : 3|1@1+ (1,0) [0|1] "" Host
 SG_ BATT_bmsProcessorError_4 : 2|1@1+ (1,0) [0|1] "" Host
 SG_ BATT_bmsMemoryError_4 : 1|1@1+ (1,0) [0|1] "" Host
 SG_ BATT_afeError_4 : 0|1@1+ (1,0) [0|1] "" Host

BO_ 2566852859 BATT_eventMatrix_A_5: 8 Battery
 SG_ BATT_packModIdFault_5 : 8|1@1+ (1,0) [0|1] "" Host
 SG_ BATT_packModExitedFromBus_5 : 16|1@1+ (1,0) [0|1] "" Host
 SG_ BATT_packFetChgWelded_5 : 35|1@1+ (1,0) [0|1] "" Host
 SG_ BATT_packFetDsgWelded_5 : 36|1@1+ (1,0) [0|1] "" Host
 SG_ BATT_fetDsgShortedAux_5 : 63|1@1+ (1,0) [0|1] "" Host
 SG_ BATT_fetChgShortedAux_5 : 25|1@1+ (1,0) [0|1] "" Host
 SG_ BATT_prechargeFetFail_5 : 39|1@1+ (1,0) [0|1] "" Host
 SG_ BATT_abnormalResetReason_5 : 31|1@1+ (1,0) [0|1] "" Host
 SG_ BATT_prechargeTooSlow_5 : 49|1@1+ (1,0) [0|1] "" Host
 SG_ BATT_prechargeTooFast_5 : 50|1@1+ (1,0) [0|1] "" Host
 SG_ BATT_prechargeTimeout_5 : 51|1@1+ (1,0) [0|1] "" Host
 SG_ BATT_fetChgShorted_5 : 23|1@1+ (1,0) [0|1] "" Host
 SG_ BATT_fetChgFailToClose_5 : 22|1@1+ (1,0) [0|1] "" Host
 SG_ BATT_packModSelectFault_5 : 21|1@1+ (1,0) [0|1] "" Host
 SG_ BATT_packModConnectFault_5 : 20|1@1+ (1,0) [0|1] "" Host
 SG_ BATT_packModMIA_5 : 19|1@1+ (1,0) [0|1] "" Host
 SG_ BATT_packModImbalance_5 : 18|1@1+ (1,0) [0|1] "" Host
 SG_ BATT_afeFault_5 : 17|1@1+ (1,0) [0|1] "" Host
 SG_ BATT_chargerMIA_5 : 60|1@1+ (1,0) [0|1] "" Host
 SG_ BATT_chargerError_5 : 59|1@1+ (1,0) [0|1] "" Host
 SG_ BATT_vBrickUnderWar_5 : 58|1@1+ (1,0) [0|1] "" Host
 SG_ BATT_vBrickUnderSev_5 : 57|1@1+ (1,0) [0|1] "" Host
 SG_ BATT_vBrickUnderMod_5 : 56|1@1+ (1,0) [0|1] "" Host
 SG_ BATT_vBrickOverWar_5 : 55|1@1+ (1,0) [0|1] "" Host
 SG_ BATT_vBrickOverSev_5 : 54|1@1+ (1,0) [0|1] "" Host
 SG_ BATT_vBrickOverMod_5 : 53|1@1+ (1,0) [0|1] "" Host
 SG_ BATT_vBrickImbalance_5 : 52|1@1+ (1,0) [0|1] "" Host
 SG_ BATT_loggerAlmostFull_5 : 61|1@1+ (1,0) [0|1] "" Host
 SG_ BATT_tempModuleUnderWar_5 : 48|1@1+ (1,0) [0|1] "" Host
 SG_ BATT_tempModuleUnderSev_5 : 47|1@1+ (1,0) [0|1] "" Host
 SG_ BATT_tempModuleUnderMod_5 : 46|1@1+ (1,0) [0|1] "" Host
 SG_ BATT_tempModuleOverWar_5 : 45|1@1+ (1,0) [0|1] "" Host
 SG_ BATT_tempModuleOverSev_5 : 44|1@1+ (1,0) [0|1] "" Host
 SG_ BATT_tempModuleOverMod_5 : 43|1@1+ (1,0) [0|1] "" Host
 SG_ BATT_tempBrickImbalance_5 : 42|1@1+ (1,0) [0|1] "" Host
 SG_ BATT_taskLockupError_5 : 41|1@1+ (1,0) [0|1] "" Host
 SG_ BATT_tempBoardOverWar_5 : 40|1@1+ (1,0) [0|1] "" Host
 SG_ BATT_tempBoardOverSev_5 : 38|1@1+ (1,0) [0|1] "" Host
 SG_ BATT_tempBoardOverMod_5 : 37|1@1+ (1,0) [0|1] "" Host
 SG_ BATT_sensePackVoltError_5 : 34|1@1+ (1,0) [0|1] "" Host
 SG_ BATT_senseLoadVoltError_5 : 33|1@1+ (1,0) [0|1] "" Host
 SG_ BATT_loggerFull_5 : 62|1@1+ (1,0) [0|1] "" Host
 SG_ BATT_senseCurrentError_5 : 32|1@1+ (1,0) [0|1] "" Host
 SG_ BATT_senseBrickTempError_5 : 30|1@1+ (1,0) [0|1] "" Host
 SG_ BATT_resPackHigh_5 : 29|1@1+ (1,0) [0|1] "" Host
 SG_ BATT_ramOverUtilError_5 : 28|1@1+ (1,0) [0|1] "" Host
 SG_ BATT_powerPackInsufficient_5 : 27|1@1+ (1,0) [0|1] "" Host
 SG_ BATT_packCellSoftShort_5 : 26|1@1+ (1,0) [0|1] "" Host
 SG_ BATT_iOverHardware_5 : 24|1@1+ (1,0) [0|1] "" Host
 SG_ BATT_fetOverTemp_5 : 15|1@1+ (1,0) [0|1] "" Host
 SG_ BATT_iOverDischarge_5 : 14|1@1+ (1,0) [0|1] "" Host
 SG_ BATT_iOverCharge_5 : 13|1@1+ (1,0) [0|1] "" Host
 SG_ BATT_inverterDriveMIA_5 : 12|1@1+ (1,0) [0|1] "" Host
 SG_ BATT_iUnderCharge_5 : 11|1@1+ (1,0) [0|1] "" Host
 SG_ BATT_hostMIA_5 : 10|1@1+ (1,0) [0|1] "" Host
 SG_ BATT_fetDsgShorted_5 : 7|1@1+ (1,0) [0|1] "" Host
 SG_ BATT_fetDsgFailToClose_5 : 6|1@1+ (1,0) [0|1] "" Host
 SG_ BATT_capLow_5 : 5|1@1+ (1,0) [0|1] "" Host
 SG_ BATT_brickOverDischarge_5 : 4|1@1+ (1,0) [0|1] "" Host
 SG_ BATT_brickOverCharge_5 : 3|1@1+ (1,0) [0|1] "" Host
 SG_ BATT_bmsProcessorError_5 : 2|1@1+ (1,0) [0|1] "" Host
 SG_ BATT_bmsMemoryError_5 : 1|1@1+ (1,0) [0|1] "" Host
 SG_ BATT_afeError_5 : 0|1@1+ (1,0) [0|1] "" Host

BO_ 2566852860 BATT_eventMatrix_A_6: 8 Battery
 SG_ BATT_packModIdFault_6 : 8|1@1+ (1,0) [0|1] "" Host
 SG_ BATT_packModExitedFromBus_6 : 16|1@1+ (1,0) [0|1] "" Host
 SG_ BATT_packFetChgWelded_6 : 35|1@1+ (1,0) [0|1] "" Host
 SG_ BATT_packFetDsgWelded_6 : 36|1@1+ (1,0) [0|1] "" Host
 SG_ BATT_fetDsgShortedAux_6 : 63|1@1+ (1,0) [0|1] "" Host
 SG_ BATT_fetChgShortedAux_6 : 25|1@1+ (1,0) [0|1] "" Host
 SG_ BATT_prechargeFetFail_6 : 39|1@1+ (1,0) [0|1] "" Host
 SG_ BATT_abnormalResetReason_6 : 31|1@1+ (1,0) [0|1] "" Host
 SG_ BATT_prechargeTooSlow_6 : 49|1@1+ (1,0) [0|1] "" Host
 SG_ BATT_prechargeTooFast_6 : 50|1@1+ (1,0) [0|1] "" Host
 SG_ BATT_prechargeTimeout_6 : 51|1@1+ (1,0) [0|1] "" Host
 SG_ BATT_fetChgShorted_6 : 23|1@1+ (1,0) [0|1] "" Host
 SG_ BATT_fetChgFailToClose_6 : 22|1@1+ (1,0) [0|1] "" Host
 SG_ BATT_packModSelectFault_6 : 21|1@1+ (1,0) [0|1] "" Host
 SG_ BATT_packModConnectFault_6 : 20|1@1+ (1,0) [0|1] "" Host
 SG_ BATT_packModMIA_6 : 19|1@1+ (1,0) [0|1] "" Host
 SG_ BATT_packModImbalance_6 : 18|1@1+ (1,0) [0|1] "" Host
 SG_ BATT_afeFault_6 : 17|1@1+ (1,0) [0|1] "" Host
 SG_ BATT_chargerMIA_6 : 60|1@1+ (1,0) [0|1] "" Host
 SG_ BATT_chargerError_6 : 59|1@1+ (1,0) [0|1] "" Host
 SG_ BATT_vBrickUnderWar_6 : 58|1@1+ (1,0) [0|1] "" Host
 SG_ BATT_vBrickUnderSev_6 : 57|1@1+ (1,0) [0|1] "" Host
 SG_ BATT_vBrickUnderMod_6 : 56|1@1+ (1,0) [0|1] "" Host
 SG_ BATT_vBrickOverWar_6 : 55|1@1+ (1,0) [0|1] "" Host
 SG_ BATT_vBrickOverSev_6 : 54|1@1+ (1,0) [0|1] "" Host
 SG_ BATT_vBrickOverMod_6 : 53|1@1+ (1,0) [0|1] "" Host
 SG_ BATT_vBrickImbalance_6 : 52|1@1+ (1,0) [0|1] "" Host
 SG_ BATT_loggerAlmostFull_6 : 61|1@1+ (1,0) [0|1] "" Host
 SG_ BATT_tempModuleUnderWar_6 : 48|1@1+ (1,0) [0|1] "" Host
 SG_ BATT_tempModuleUnderSev_6 : 47|1@1+ (1,0) [0|1] "" Host
 SG_ BATT_tempModuleUnderMod_6 : 46|1@1+ (1,0) [0|1] "" Host
 SG_ BATT_tempModuleOverWar_6 : 45|1@1+ (1,0) [0|1] "" Host
 SG_ BATT_tempModuleOverSev_6 : 44|1@1+ (1,0) [0|1] "" Host
 SG_ BATT_tempModuleOverMod_6 : 43|1@1+ (1,0) [0|1] "" Host
 SG_ BATT_tempBrickImbalance_6 : 42|1@1+ (1,0) [0|1] "" Host
 SG_ BATT_taskLockupError_6 : 41|1@1+ (1,0) [0|1] "" Host
 SG_ BATT_tempBoardOverWar_6 : 40|1@1+ (1,0) [0|1] "" Host
 SG_ BATT_tempBoardOverSev_6 : 38|1@1+ (1,0) [0|1] "" Host
 SG_ BATT_tempBoardOverMod_6 : 37|1@1+ (1,0) [0|1] "" Host
 SG_ BATT_sensePackVoltError_6 : 34|1@1+ (1,0) [0|1] "" Host
 SG_ BATT_senseLoadVoltError_6 : 33|1@1+ (1,0) [0|1] "" Host
 SG_ BATT_loggerFull_6 : 62|1@1+ (1,0) [0|1] "" Host
 SG_ BATT_senseCurrentError_6 : 32|1@1+ (1,0) [0|1] "" Host
 SG_ BATT_senseBrickTempError_6 : 30|1@1+ (1,0) [0|1] "" Host
 SG_ BATT_resPackHigh_6 : 29|1@1+ (1,0) [0|1] "" Host
 SG_ BATT_ramOverUtilError_6 : 28|1@1+ (1,0) [0|1] "" Host
 SG_ BATT_powerPackInsufficient_6 : 27|1@1+ (1,0) [0|1] "" Host
 SG_ BATT_packCellSoftShort_6 : 26|1@1+ (1,0) [0|1] "" Host
 SG_ BATT_iOverHardware_6 : 24|1@1+ (1,0) [0|1] "" Host
 SG_ BATT_fetOverTemp_6 : 15|1@1+ (1,0) [0|1] "" Host
 SG_ BATT_iOverDischarge_6 : 14|1@1+ (1,0) [0|1] "" Host
 SG_ BATT_iOverCharge_6 : 13|1@1+ (1,0) [0|1] "" Host
 SG_ BATT_inverterDriveMIA_6 : 12|1@1+ (1,0) [0|1] "" Host
 SG_ BATT_iUnderCharge_6 : 11|1@1+ (1,0) [0|1] "" Host
 SG_ BATT_hostMIA_6 : 10|1@1+ (1,0) [0|1] "" Host
 SG_ BATT_fetDsgShorted_6 : 7|1@1+ (1,0) [0|1] "" Host
 SG_ BATT_fetDsgFailToClose_6 : 6|1@1+ (1,0) [0|1] "" Host
 SG_ BATT_capLow_6 : 5|1@1+ (1,0) [0|1] "" Host
 SG_ BATT_brickOverDischarge_6 : 4|1@1+ (1,0) [0|1] "" Host
 SG_ BATT_brickOverCharge_6 : 3|1@1+ (1,0) [0|1] "" Host
 SG_ BATT_bmsProcessorError_6 : 2|1@1+ (1,0) [0|1] "" Host
 SG_ BATT_bmsMemoryError_6 : 1|1@1+ (1,0) [0|1] "" Host
 SG_ BATT_afeError_6 : 0|1@1+ (1,0) [0|1] "" Host

BO_ 2566852861 BATT_eventMatrix_A_7: 8 Battery
 SG_ BATT_packModIdFault_7 : 8|1@1+ (1,0) [0|1] "" Host
 SG_ BATT_packModExitedFromBus_7 : 16|1@1+ (1,0) [0|1] "" Host
 SG_ BATT_packFetChgWelded_7 : 35|1@1+ (1,0) [0|1] "" Host
 SG_ BATT_packFetDsgWelded_7 : 36|1@1+ (1,0) [0|1] "" Host
 SG_ BATT_fetDsgShortedAux_7 : 63|1@1+ (1,0) [0|1] "" Host
 SG_ BATT_fetChgShortedAux_7 : 25|1@1+ (1,0) [0|1] "" Host
 SG_ BATT_prechargeFetFail_7 : 39|1@1+ (1,0) [0|1] "" Host
 SG_ BATT_abnormalResetReason_7 : 31|1@1+ (1,0) [0|1] "" Host
 SG_ BATT_prechargeTooSlow_7 : 49|1@1+ (1,0) [0|1] "" Host
 SG_ BATT_prechargeTooFast_7 : 50|1@1+ (1,0) [0|1] "" Host
 SG_ BATT_prechargeTimeout_7 : 51|1@1+ (1,0) [0|1] "" Host
 SG_ BATT_fetChgShorted_7 : 23|1@1+ (1,0) [0|1] "" Host
 SG_ BATT_fetChgFailToClose_7 : 22|1@1+ (1,0) [0|1] "" Host
 SG_ BATT_packModSelectFault_7 : 21|1@1+ (1,0) [0|1] "" Host
 SG_ BATT_packModConnectFault_7 : 20|1@1+ (1,0) [0|1] "" Host
 SG_ BATT_packModMIA_7 : 19|1@1+ (1,0) [0|1] "" Host
 SG_ BATT_packModImbalance_7 : 18|1@1+ (1,0) [0|1] "" Host
 SG_ BATT_afeFault_7 : 17|1@1+ (1,0) [0|1] "" Host
 SG_ BATT_chargerMIA_7 : 60|1@1+ (1,0) [0|1] "" Host
 SG_ BATT_chargerError_7 : 59|1@1+ (1,0) [0|1] "" Host
 SG_ BATT_vBrickUnderWar_7 : 58|1@1+ (1,0) [0|1] "" Host
 SG_ BATT_vBrickUnderSev_7 : 57|1@1+ (1,0) [0|1] "" Host
 SG_ BATT_vBrickUnderMod_7 : 56|1@1+ (1,0) [0|1] "" Host
 SG_ BATT_vBrickOverWar_7 : 55|1@1+ (1,0) [0|1] "" Host
 SG_ BATT_vBrickOverSev_7 : 54|1@1+ (1,0) [0|1] "" Host
 SG_ BATT_vBrickOverMod_7 : 53|1@1+ (1,0) [0|1] "" Host
 SG_ BATT_vBrickImbalance_7 : 52|1@1+ (1,0) [0|1] "" Host
 SG_ BATT_loggerAlmostFull_7 : 61|1@1+ (1,0) [0|1] "" Host
 SG_ BATT_tempModuleUnderWar_7 : 48|1@1+ (1,0) [0|1] "" Host
 SG_ BATT_tempModuleUnderSev_7 : 47|1@1+ (1,0) [0|1] "" Host
 SG_ BATT_tempModuleUnderMod_7 : 46|1@1+ (1,0) [0|1] "" Host
 SG_ BATT_tempModuleOverWar_7 : 45|1@1+ (1,0) [0|1] "" Host
 SG_ BATT_tempModuleOverSev_7 : 44|1@1+ (1,0) [0|1] "" Host
 SG_ BATT_tempModuleOverMod_7 : 43|1@1+ (1,0) [0|1] "" Host
 SG_ BATT_tempBrickImbalance_7 : 42|1@1+ (1,0) [0|1] "" Host
 SG_ BATT_taskLockupError_7 : 41|1@1+ (1,0) [0|1] "" Host
 SG_ BATT_tempBoardOverWar_7 : 40|1@1+ (1,0) [0|1] "" Host
 SG_ BATT_tempBoardOverSev_7 : 38|1@1+ (1,0) [0|1] "" Host
 SG_ BATT_tempBoardOverMod_7 : 37|1@1+ (1,0) [0|1] "" Host
 SG_ BATT_sensePackVoltError_7 : 34|1@1+ (1,0) [0|1] "" Host
 SG_ BATT_senseLoadVoltError_7 : 33|1@1+ (1,0) [0|1] "" Host
 SG_ BATT_loggerFull_7 : 62|1@1+ (1,0) [0|1] "" Host
 SG_ BATT_senseCurrentError_7 : 32|1@1+ (1,0) [0|1] "" Host
 SG_ BATT_senseBrickTempError_7 : 30|1@1+ (1,0) [0|1] "" Host
 SG_ BATT_resPackHigh_7 : 29|1@1+ (1,0) [0|1] "" Host
 SG_ BATT_ramOverUtilError_7 : 28|1@1+ (1,0) [0|1] "" Host
 SG_ BATT_powerPackInsufficient_7 : 27|1@1+ (1,0) [0|1] "" Host
 SG_ BATT_packCellSoftShort_7 : 26|1@1+ (1,0) [0|1] "" Host
 SG_ BATT_iOverHardware_7 : 24|1@1+ (1,0) [0|1] "" Host
 SG_ BATT_fetOverTemp_7 : 15|1@1+ (1,0) [0|1] "" Host
 SG_ BATT_iOverDischarge_7 : 14|1@1+ (1,0) [0|1] "" Host
 SG_ BATT_iOverCharge_7 : 13|1@1+ (1,0) [0|1] "" Host
 SG_ BATT_inverterDriveMIA_7 : 12|1@1+ (1,0) [0|1] "" Host
 SG_ BATT_iUnderCharge_7 : 11|1@1+ (1,0) [0|1] "" Host
 SG_ BATT_hostMIA_7 : 10|1@1+ (1,0) [0|1] "" Host
 SG_ BATT_fetDsgShorted_7 : 7|1@1+ (1,0) [0|1] "" Host
 SG_ BATT_fetDsgFailToClose_7 : 6|1@1+ (1,0) [0|1] "" Host
 SG_ BATT_capLow_7 : 5|1@1+ (1,0) [0|1] "" Host
 SG_ BATT_brickOverDischarge_7 : 4|1@1+ (1,0) [0|1] "" Host
 SG_ BATT_brickOverCharge_7 : 3|1@1+ (1,0) [0|1] "" Host
 SG_ BATT_bmsProcessorError_7 : 2|1@1+ (1,0) [0|1] "" Host
 SG_ BATT_bmsMemoryError_7 : 1|1@1+ (1,0) [0|1] "" Host
 SG_ BATT_afeError_7 : 0|1@1+ (1,0) [0|1] "" Host

BO_ 2566852862 BATT_eventMatrix_A_8: 8 Battery
 SG_ BATT_packModIdFault_8 : 8|1@1+ (1,0) [0|1] "" Host
 SG_ BATT_packModExitedFromBus_8 : 16|1@1+ (1,0) [0|1] "" Host
 SG_ BATT_packFetChgWelded_8 : 35|1@1+ (1,0) [0|1] "" Host
 SG_ BATT_packFetDsgWelded_8 : 36|1@1+ (1,0) [0|1] "" Host
 SG_ BATT_fetDsgShortedAux_8 : 63|1@1+ (1,0) [0|1] "" Host
 SG_ BATT_fetChgShortedAux_8 : 25|1@1+ (1,0) [0|1] "" Host
 SG_ BATT_prechargeFetFail_8 : 39|1@1+ (1,0) [0|1] "" Host
 SG_ BATT_abnormalResetReason_8 : 31|1@1+ (1,0) [0|1] "" Host
 SG_ BATT_prechargeTooSlow_8 : 49|1@1+ (1,0) [0|1] "" Host
 SG_ BATT_prechargeTooFast_8 : 50|1@1+ (1,0) [0|1] "" Host
 SG_ BATT_prechargeTimeout_8 : 51|1@1+ (1,0) [0|1] "" Host
 SG_ BATT_fetChgShorted_8 : 23|1@1+ (1,0) [0|1] "" Host
 SG_ BATT_fetChgFailToClose_8 : 22|1@1+ (1,0) [0|1] "" Host
 SG_ BATT_packModSelectFault_8 : 21|1@1+ (1,0) [0|1] "" Host
 SG_ BATT_packModConnectFault_8 : 20|1@1+ (1,0) [0|1] "" Host
 SG_ BATT_packModMIA_8 : 19|1@1+ (1,0) [0|1] "" Host
 SG_ BATT_packModImbalance_8 : 18|1@1+ (1,0) [0|1] "" Host
 SG_ BATT_afeFault_8 : 17|1@1+ (1,0) [0|1] "" Host
 SG_ BATT_chargerMIA_8 : 60|1@1+ (1,0) [0|1] "" Host
 SG_ BATT_chargerError_8 : 59|1@1+ (1,0) [0|1] "" Host
 SG_ BATT_vBrickUnderWar_8 : 58|1@1+ (1,0) [0|1] "" Host
 SG_ BATT_vBrickUnderSev_8 : 57|1@1+ (1,0) [0|1] "" Host
 SG_ BATT_vBrickUnderMod_8 : 56|1@1+ (1,0) [0|1] "" Host
 SG_ BATT_vBrickOverWar_8 : 55|1@1+ (1,0) [0|1] "" Host
 SG_ BATT_vBrickOverSev_8 : 54|1@1+ (1,0) [0|1] "" Host
 SG_ BATT_vBrickOverMod_8 : 53|1@1+ (1,0) [0|1] "" Host
 SG_ BATT_vBrickImbalance_8 : 52|1@1+ (1,0) [0|1] "" Host
 SG_ BATT_loggerAlmostFull_8 : 61|1@1+ (1,0) [0|1] "" Host
 SG_ BATT_tempModuleUnderWar_8 : 48|1@1+ (1,0) [0|1] "" Host
 SG_ BATT_tempModuleUnderSev_8 : 47|1@1+ (1,0) [0|1] "" Host
 SG_ BATT_tempModuleUnderMod_8 : 46|1@1+ (1,0) [0|1] "" Host
 SG_ BATT_tempModuleOverWar_8 : 45|1@1+ (1,0) [0|1] "" Host
 SG_ BATT_tempModuleOverSev_8 : 44|1@1+ (1,0) [0|1] "" Host
 SG_ BATT_tempModuleOverMod_8 : 43|1@1+ (1,0) [0|1] "" Host
 SG_ BATT_tempBrickImbalance_8 : 42|1@1+ (1,0) [0|1] "" Host
 SG_ BATT_taskLockupError_8 : 41|1@1+ (1,0) [0|1] "" Host
 SG_ BATT_tempBoardOverWar_8 : 40|1@1+ (1,0) [0|1] "" Host
 SG_ BATT_tempBoardOverSev_8 : 38|1@1+ (1,0) [0|1] "" Host
 SG_ BATT_tempBoardOverMod_8 : 37|1@1+ (1,0) [0|1] "" Host
 SG_ BATT_sensePackVoltError_8 : 34|1@1+ (1,0) [0|1] "" Host
 SG_ BATT_senseLoadVoltError_8 : 33|1@1+ (1,0) [0|1] "" Host
 SG_ BATT_loggerFull_8 : 62|1@1+ (1,0) [0|1] "" Host
 SG_ BATT_senseCurrentError_8 : 32|1@1+ (1,0) [0|1] "" Host
 SG_ BATT_senseBrickTempError_8 : 30|1@1+ (1,0) [0|1] "" Host
 SG_ BATT_resPackHigh_8 : 29|1@1+ (1,0) [0|1] "" Host
 SG_ BATT_ramOverUtilError_8 : 28|1@1+ (1,0) [0|1] "" Host
 SG_ BATT_powerPackInsufficient_8 : 27|1@1+ (1,0) [0|1] "" Host
 SG_ BATT_packCellSoftShort_8 : 26|1@1+ (1,0) [0|1] "" Host
 SG_ BATT_iOverHardware_8 : 24|1@1+ (1,0) [0|1] "" Host
 SG_ BATT_fetOverTemp_8 : 15|1@1+ (1,0) [0|1] "" Host
 SG_ BATT_iOverDischarge_8 : 14|1@1+ (1,0) [0|1] "" Host
 SG_ BATT_iOverCharge_8 : 13|1@1+ (1,0) [0|1] "" Host
 SG_ BATT_inverterDriveMIA_8 : 12|1@1+ (1,0) [0|1] "" Host
 SG_ BATT_iUnderCharge_8 : 11|1@1+ (1,0) [0|1] "" Host
 SG_ BATT_hostMIA_8 : 10|1@1+ (1,0) [0|1] "" Host
 SG_ BATT_fetDsgShorted_8 : 7|1@1+ (1,0) [0|1] "" Host
 SG_ BATT_fetDsgFailToClose_8 : 6|1@1+ (1,0) [0|1] "" Host
 SG_ BATT_capLow_8 : 5|1@1+ (1,0) [0|1] "" Host
 SG_ BATT_brickOverDischarge_8 : 4|1@1+ (1,0) [0|1] "" Host
 SG_ BATT_brickOverCharge_8 : 3|1@1+ (1,0) [0|1] "" Host
 SG_ BATT_bmsProcessorError_8 : 2|1@1+ (1,0) [0|1] "" Host
 SG_ BATT_bmsMemoryError_8 : 1|1@1+ (1,0) [0|1] "" Host
 SG_ BATT_afeError_8 : 0|1@1+ (1,0) [0|1] "" Host

CM_ SG_ 2566851837 BATT_vMod_7 "Battery terminal voltage";
CM_ SG_ 2566851837 BATT_vModSumOfCells_7 "Battery pack voltage in volts, sum of brick voltages";
CM_ SG_ 2566851837 BATT_iMod_7 "Charge/discharge rate in ampere - positive for charge, negative for discharge.";
CM_ SG_ 2566851837 BATT_iModFiltered_7 "Filtered charge/discharge rate in ampere - positive for charge, negative for discharge.";
CM_ SG_ 2566851838 BATT_vMod_8 "Battery terminal voltage";
CM_ SG_ 2566851838 BATT_vModSumOfCells_8 "Battery pack voltage in volts, sum of brick voltages";
CM_ SG_ 2566851838 BATT_iMod_8 "Charge/discharge rate in ampere - positive for charge, negative for discharge.";
CM_ SG_ 2566851838 BATT_iModFiltered_8 "Filtered charge/discharge rate in ampere - positive for charge, negative for discharge.";
CM_ SG_ 2566851839 BATT_vMod_9 "Battery terminal voltage";
CM_ SG_ 2566851839 BATT_vModSumOfCells_9 "Battery pack voltage in volts, sum of brick voltages";
CM_ SG_ 2566851839 BATT_iMod_9 "Charge/discharge rate in ampere - positive for charge, negative for discharge.";
CM_ SG_ 2566851839 BATT_iModFiltered_9 "Filtered charge/discharge rate in ampere - positive for charge, negative for discharge.";
CM_ SG_ 2566852342 BATT_bmsVariantApp_0 "SW Version variant type (Variant.Major.Minor.SubMinor.BuildNum)";
CM_ SG_ 2566852342 BATT_swVerSubMinorApp_0 "SW Version Subminor / Patch (Variant.Major.Minor.SubMinor.BuildNum)";
CM_ SG_ 2566852342 BATT_swVerMinorApp_0 "SW Version Minor (Variant.Major.Minor.SubMinor.BuildNum)";
CM_ SG_ 2566852342 BATT_swVerMajorApp_0 "SW Version Major (Variant.Major.Minor.SubMinor.BuildNum)";
CM_ SG_ 2566852342 BATT_HwVerApp_0 "SW Version variant build number (Variant.Major.Minor.SubMinor.BuildNum)";
CM_ SG_ 2566852343 BATT_bmsVariantApp_1 "SW Version variant type (Variant.Major.Minor.SubMinor.BuildNum)";
CM_ SG_ 2566852343 BATT_swVerSubMinorApp_1 "SW Version Subminor / Patch (Variant.Major.Minor.SubMinor.BuildNum)";
CM_ SG_ 2566852343 BATT_swVerMinorApp_1 "SW Version Minor (Variant.Major.Minor.SubMinor.BuildNum)";
CM_ SG_ 2566852343 BATT_swVerMajorApp_1 "SW Version Major (Variant.Major.Minor.SubMinor.BuildNum)";
CM_ SG_ 2566852343 BATT_HwVerApp_1 "SW Version variant build number (Variant.Major.Minor.SubMinor.BuildNum)";
CM_ SG_ 2566852344 BATT_bmsVariantApp_2 "SW Version variant type (Variant.Major.Minor.SubMinor.BuildNum)";
CM_ SG_ 2566852344 BATT_swVerSubMinorApp_2 "SW Version Subminor / Patch (Variant.Major.Minor.SubMinor.BuildNum)";
CM_ SG_ 2566852344 BATT_swVerMinorApp_2 "SW Version Minor (Variant.Major.Minor.SubMinor.BuildNum)";
CM_ SG_ 2566852344 BATT_swVerMajorApp_2 "SW Version Major (Variant.Major.Minor.SubMinor.BuildNum)";
CM_ SG_ 2566852344 BATT_HwVerApp_2 "SW Version variant build number (Variant.Major.Minor.SubMinor.BuildNum)";
CM_ SG_ 2566852345 BATT_bmsVariantApp_3 "SW Version variant type (Variant.Major.Minor.SubMinor.BuildNum)";
CM_ SG_ 2566852345 BATT_swVerSubMinorApp_3 "SW Version Subminor / Patch (Variant.Major.Minor.SubMinor.BuildNum)";
CM_ SG_ 2566852345 BATT_swVerMinorApp_3 "SW Version Minor (Variant.Major.Minor.SubMinor.BuildNum)";
CM_ SG_ 2566852345 BATT_swVerMajorApp_3 "SW Version Major (Variant.Major.Minor.SubMinor.BuildNum)";
CM_ SG_ 2566852345 BATT_HwVerApp_3 "SW Version variant build number (Variant.Major.Minor.SubMinor.BuildNum)";
CM_ SG_ 2566852346 BATT_bmsVariantApp_4 "SW Version variant type (Variant.Major.Minor.SubMinor.BuildNum)";
CM_ SG_ 2566852346 BATT_swVerSubMinorApp_4 "SW Version Subminor / Patch (Variant.Major.Minor.SubMinor.BuildNum)";
CM_ SG_ 2566852346 BATT_swVerMinorApp_4 "SW Version Minor (Variant.Major.Minor.SubMinor.BuildNum)";
CM_ SG_ 2566852346 BATT_swVerMajorApp_4 "SW Version Major (Variant.Major.Minor.SubMinor.BuildNum)";
CM_ SG_ 2566852346 BATT_HwVerApp_4 "SW Version variant build number (Variant.Major.Minor.SubMinor.BuildNum)";
CM_ SG_ 2566852347 BATT_bmsVariantApp_5 "SW Version variant type (Variant.Major.Minor.SubMinor.BuildNum)";
CM_ SG_ 2566852347 BATT_swVerSubMinorApp_5 "SW Version Subminor / Patch (Variant.Major.Minor.SubMinor.BuildNum)";
CM_ SG_ 2566852347 BATT_swVerMinorApp_5 "SW Version Minor (Variant.Major.Minor.SubMinor.BuildNum)";
CM_ SG_ 2566852347 BATT_swVerMajorApp_5 "SW Version Major (Variant.Major.Minor.SubMinor.BuildNum)";
CM_ SG_ 2566852347 BATT_HwVerApp_5 "SW Version variant build number (Variant.Major.Minor.SubMinor.BuildNum)";
CM_ SG_ 2566852348 BATT_bmsVariantApp_6 "SW Version variant type (Variant.Major.Minor.SubMinor.BuildNum)";
CM_ SG_ 2566852348 BATT_swVerSubMinorApp_6 "SW Version Subminor / Patch (Variant.Major.Minor.SubMinor.BuildNum)";
CM_ SG_ 2566852348 BATT_swVerMinorApp_6 "SW Version Minor (Variant.Major.Minor.SubMinor.BuildNum)";
CM_ SG_ 2566852348 BATT_swVerMajorApp_6 "SW Version Major (Variant.Major.Minor.SubMinor.BuildNum)";
CM_ SG_ 2566852348 BATT_HwVerApp_6 "SW Version variant build number (Variant.Major.Minor.SubMinor.BuildNum)";
CM_ SG_ 2566852349 BATT_bmsVariantApp_7 "SW Version variant type (Variant.Major.Minor.SubMinor.BuildNum)";
CM_ SG_ 2566852349 BATT_swVerSubMinorApp_7 "SW Version Subminor / Patch (Variant.Major.Minor.SubMinor.BuildNum)";
CM_ SG_ 2566852349 BATT_swVerMinorApp_7 "SW Version Minor (Variant.Major.Minor.SubMinor.BuildNum)";
CM_ SG_ 2566852349 BATT_swVerMajorApp_7 "SW Version Major (Variant.Major.Minor.SubMinor.BuildNum)";
CM_ SG_ 2566852349 BATT_HwVerApp_7 "SW Version variant build number (Variant.Major.Minor.SubMinor.BuildNum)";
CM_ SG_ 2566852350 BATT_bmsVariantApp_8 "SW Version variant type (Variant.Major.Minor.SubMinor.BuildNum)";
CM_ SG_ 2566852350 BATT_swVerSubMinorApp_8 "SW Version Subminor / Patch (Variant.Major.Minor.SubMinor.BuildNum)";
CM_ SG_ 2566852350 BATT_swVerMinorApp_8 "SW Version Minor (Variant.Major.Minor.SubMinor.BuildNum)";
CM_ SG_ 2566852350 BATT_swVerMajorApp_8 "SW Version Major (Variant.Major.Minor.SubMinor.BuildNum)";
CM_ SG_ 2566852350 BATT_HwVerApp_8 "SW Version variant build number (Variant.Major.Minor.SubMinor.BuildNum)";
CM_ SG_ 2566852351 BATT_bmsVariantApp_9 "SW Version variant type (Variant.Major.Minor.SubMinor.BuildNum)";
CM_ SG_ 2566852351 BATT_swVerSubMinorApp_9 "SW Version Subminor / Patch (Variant.Major.Minor.SubMinor.BuildNum)";
CM_ SG_ 2566852351 BATT_swVerMinorApp_9 "SW Version Minor (Variant.Major.Minor.SubMinor.BuildNum)";
CM_ SG_ 2566852351 BATT_swVerMajorApp_9 "SW Version Major (Variant.Major.Minor.SubMinor.BuildNum)";
CM_ SG_ 2566852351 BATT_HwVerApp_9 "SW Version variant build number (Variant.Major.Minor.SubMinor.BuildNum)";
CM_ BO_ 2566852598 "Balancing status";
CM_ BO_ 2566852854 "Message with flags from event matrix";
CM_ SG_ 2566852854 BATT_packModIdFault_0 "0 - Battery pack module ID okay (default)
1 - Battery pack module ID fault";
CM_ SG_ 2566852854 BATT_packModExitedFromBus_0 "0 - Battery pack modules OK (default)
1 - Battery pack module(s) exited from the bus during charge or drive";
CM_ SG_ 2566852854 BATT_packFetChgWelded_0 "0 - Battery pack module CHG FETs not welded (default)
1 - Battery pack module CHG FETs welded ";
CM_ SG_ 2566852854 BATT_packFetDsgWelded_0 "0 - Battery pack module DSG FETs not welded (default)
1 - Battery pack module DSG FETs welded ";
CM_ SG_ 2566852854 BATT_fetDsgShortedAux_0 "0 - FETs are operational (default)
1 - FET is shorted detected by auxiliary diagnostic";
CM_ SG_ 2566852854 BATT_fetChgShortedAux_0 "0 - FETs are operational (default)
1 - FET is shorted detected by auxiliary diagnostic";
CM_ SG_ 2566852854 BATT_prechargeFetFail_0 "0 - Precharge FET okay (default)
1 - Precharge FET failed";
CM_ SG_ 2566852854 BATT_abnormalResetReason_0 "0 - Reset reason okay (default)
1 - Abnormal reset reason";
CM_ SG_ 2566852854 BATT_prechargeTooSlow_0 "0 - Precharge okay (default)
1 - Precharge too slow";
CM_ SG_ 2566852854 BATT_prechargeTooFast_0 "0 - Precharge okay (default)
1 - Precharge too fast";
CM_ SG_ 2566852854 BATT_prechargeTimeout_0 "0 - Precharge okay (default)
1 - Precharge timeout";
CM_ SG_ 2566852854 BATT_fetChgShorted_0 "0 - FETs are operational (default)
1 - FET is shorted";
CM_ SG_ 2566852854 BATT_fetChgFailToClose_0 "0 - FETs are operational (default)
1 -  FET fail to close";
CM_ SG_ 2566852854 BATT_packModSelectFault_0 "0 - Battery pack module selection okay (default)
1 - Battery pack module selection fault";
CM_ SG_ 2566852854 BATT_packModConnectFault_0 "0 - Battery pack module connection okay (default)
1 - Battery pack module connection fault";
CM_ SG_ 2566852854 BATT_packModMIA_0 "0 - Battery pack modules not MIA (default)
1 - Battery pack module MIA";
CM_ SG_ 2566852854 BATT_packModImbalance_0 "0 - Battery pack modules balanced (default)
1 - Battery pack module imblance present";
CM_ SG_ 2566852854 BATT_afeFault_0 "0 - BMS AFE okay (default)
1 - BMS AFE fault";
CM_ SG_ 2566852854 BATT_chargerMIA_0 "0 - Charger communications okay (default)
1 - Charger MIA";
CM_ SG_ 2566852854 BATT_chargerError_0 "0 - Charger working as intended (default)
1 - Charger error";
CM_ SG_ 2566852854 BATT_vBrickUnderWar_0 "0 - Brick voltage okay (default)
1 - Brick undervoltage warning";
CM_ SG_ 2566852854 BATT_vBrickUnderSev_0 "0 - Brick voltage okay (default)
1 - Brick undervoltage severe";
CM_ SG_ 2566852854 BATT_vBrickUnderMod_0 "0 - Brick voltage okay (default)
1 - Brick undervoltage moderate";
CM_ SG_ 2566852854 BATT_vBrickOverWar_0 "0 - Brick voltage okay (default)
1 - Brick overvoltage warning";
CM_ SG_ 2566852854 BATT_vBrickOverSev_0 "0 - Brick voltage okay (default)
1 - Brick overvoltage severe";
CM_ SG_ 2566852854 BATT_vBrickOverMod_0 "0 - Brick voltage okay (default)
1 - Brick overvoltage moderate";
CM_ SG_ 2566852854 BATT_vBrickImbalance_0 "0 - Battery brick voltage okay (default)
1 - Battery brick voltage imbalance";
CM_ SG_ 2566852854 BATT_loggerAlmostFull_0 "0 - Logger not almost full (default)
1 - Logger almost full (section >= 80%) ";
CM_ SG_ 2566852854 BATT_tempModuleUnderWar_0 "0 - Battery temperature okay (default)
1 - Battery under temperature warning";
CM_ SG_ 2566852854 BATT_tempModuleUnderSev_0 "0 - Battery temperature okay (default)
1 - Battery under temperature severe";
CM_ SG_ 2566852854 BATT_tempModuleUnderMod_0 "0 - Battery temperature okay (default)
1 - Battery under temperature moderate";
CM_ SG_ 2566852854 BATT_tempModuleOverWar_0 "0 - Battery temperature okay (default)
1 - Battery over temperature warning";
CM_ SG_ 2566852854 BATT_tempModuleOverSev_0 "0 - Battery temperature okay (default)
1 - Battery over temperature severe";
CM_ SG_ 2566852854 BATT_tempModuleOverMod_0 "0 - Battery temperature okay (default)
1 - Battery over temperature moderate";
CM_ SG_ 2566852854 BATT_tempBrickImbalance_0 "0 - Brick temperatures are balanced (default)
1 - Brick temperatures are imbalanced";
CM_ SG_ 2566852854 BATT_taskLockupError_0 "0 - Tasks okay (default)
1 - Task lockup error";
CM_ SG_ 2566852854 BATT_tempBoardOverWar_0 "0 - Ambient temperature okay (default)
1 - Ambient over temperature warning";
CM_ SG_ 2566852854 BATT_tempBoardOverSev_0 "0 - Temperature okay (default)
1 - Ambient over temperature severe";
CM_ SG_ 2566852854 BATT_tempBoardOverMod_0 "0 - Ambient temperature okay (default)
1 - Ambient over temparature moderate";
CM_ SG_ 2566852854 BATT_sensePackVoltError_0 "0 - Sensor okay (default)
1 - Sensor for pack voltage error";
CM_ SG_ 2566852854 BATT_senseLoadVoltError_0 "0 - Sensor okay (default)
1 - Sensor for load voltage error";
CM_ SG_ 2566852854 BATT_loggerFull_0 "0 - Logger not full (default)
1 - Logger full ";
CM_ SG_ 2566852854 BATT_senseCurrentError_0 "0 - Sensor okay (default)
1 - Sensor for current error";
CM_ SG_ 2566852854 BATT_senseBrickTempError_0 "0 - Sensor okay (default)
1 - Brick temperature sensor error";
CM_ SG_ 2566852854 BATT_resPackHigh_0 "0 - Battery pack resistance okay (default)
1 - Battery pack resistance high (High SOH-R)";
CM_ SG_ 2566852854 BATT_ramOverUtilError_0 "0 - RAM okay (default)
1 - RAM over utilization";
CM_ SG_ 2566852854 BATT_powerPackInsufficient_0 "0 - Battery pack power okay (default)
1 - Battery pack power insufficient";
CM_ SG_ 2566852854 BATT_packCellSoftShort_0 "0 - Battery back cells are okay (default)
1 - Battery pack cell soft short";
CM_ SG_ 2566852854 BATT_iOverHardware_0 "0 - Hardware current okay (default)
1 - Overcurrent in hardware";
CM_ SG_ 2566852854 BATT_fetOverTemp_0 "0 - FET temperature okay (default)
1 - Overtemp at FETs";
CM_ SG_ 2566852854 BATT_iOverDischarge_0 "0 - Discharge okay (default)
1 - Overcurrent during discharge";
CM_ SG_ 2566852854 BATT_iOverCharge_0 "0 - Charging okay (default)
1 - Overcurrent during charging";
CM_ SG_ 2566852854 BATT_inverterDriveMIA_0 "0 - Inverter drive present (default)
1 - Inverter drive MIA";
CM_ SG_ 2566852854 BATT_iUnderCharge_0 "0 - Normal charging (default)
1 -  Charging undercurrent (discharging)";
CM_ SG_ 2566852854 BATT_hostMIA_0 "0 - host communication open (default)
1 - host MIA";
CM_ SG_ 2566852854 BATT_fetDsgShorted_0 "0 - FETs are operational (default)
1 - FET is shorted";
CM_ SG_ 2566852854 BATT_fetDsgFailToClose_0 "0 - FETs are operational (default)
1 -  FET fail to close";
CM_ SG_ 2566852854 BATT_capLow_0 "0 - Battery capacity normal (SOH-C) (default)
1 - Low battery capacity (Low SOH-C)";
CM_ SG_ 2566852854 BATT_brickOverDischarge_0 "0 - Battery brick charge is normal (default)
1 - Battery brick is overdischarged";
CM_ SG_ 2566852854 BATT_brickOverCharge_0 "0 - Battery brick charge is normal (default)
1 - Battery brick is overcharged";
CM_ SG_ 2566852854 BATT_bmsProcessorError_0 "0 - No BMS processor failure (default)
1 - BMS processor failure";
CM_ SG_ 2566852854 BATT_bmsMemoryError_0 "0 - No BMS memory error
1 - BMS memory error";
CM_ SG_ 2566852854 BATT_afeError_0 "0 - No BMS AFE error (default)
1 - BMS AFE error";
CM_ BO_ 2566852855 "Message with flags from event matrix";
CM_ SG_ 2566852855 BATT_packModIdFault_1 "0 - Battery pack module ID okay (default)
1 - Battery pack module ID fault";
CM_ SG_ 2566852855 BATT_packModExitedFromBus_1 "0 - Battery pack modules OK (default)
1 - Battery pack module(s) exited from the bus during charge or drive";
CM_ SG_ 2566852855 BATT_packFetChgWelded_1 "0 - Battery pack module CHG FETs not welded (default)
1 - Battery pack module CHG FETs welded ";
CM_ SG_ 2566852855 BATT_packFetDsgWelded_1 "0 - Battery pack module DSG FETs not welded (default)
1 - Battery pack module DSG FETs welded ";
CM_ SG_ 2566852855 BATT_fetDsgShortedAux_1 "0 - FETs are operational (default)
1 - FET is shorted detected by auxiliary diagnostic";
CM_ SG_ 2566852855 BATT_fetChgShortedAux_1 "0 - FETs are operational (default)
1 - FET is shorted detected by auxiliary diagnostic";
CM_ SG_ 2566852855 BATT_prechargeFetFail_1 "0 - Precharge FET okay (default)
1 - Precharge FET failed";
CM_ SG_ 2566852855 BATT_abnormalResetReason_1 "0 - Reset reason okay (default)
1 - Abnormal reset reason";
CM_ SG_ 2566852855 BATT_prechargeTooSlow_1 "0 - Precharge okay (default)
1 - Precharge too slow";
CM_ SG_ 2566852855 BATT_prechargeTooFast_1 "0 - Precharge okay (default)
1 - Precharge too fast";
CM_ SG_ 2566852855 BATT_prechargeTimeout_1 "0 - Precharge okay (default)
1 - Precharge timeout";
CM_ SG_ 2566852855 BATT_fetChgShorted_1 "0 - FETs are operational (default)
1 - FET is shorted";
CM_ SG_ 2566852855 BATT_fetChgFailToClose_1 "0 - FETs are operational (default)
1 -  FET fail to close";
CM_ SG_ 2566852855 BATT_packModSelectFault_1 "0 - Battery pack module selection okay (default)
1 - Battery pack module selection fault";
CM_ SG_ 2566852855 BATT_packModConnectFault_1 "0 - Battery pack module connection okay (default)
1 - Battery pack module connection fault";
CM_ SG_ 2566852855 BATT_packModMIA_1 "0 - Battery pack modules not MIA (default)
1 - Battery pack module MIA";
CM_ SG_ 2566852855 BATT_packModImbalance_1 "0 - Battery pack modules balanced (default)
1 - Battery pack module imblance present";
CM_ SG_ 2566852855 BATT_afeFault_1 "0 - BMS AFE okay (default)
1 - BMS AFE fault";
CM_ SG_ 2566852855 BATT_chargerMIA_1 "0 - Charger communications okay (default)
1 - Charger MIA";
CM_ SG_ 2566852855 BATT_chargerError_1 "0 - Charger working as intended (default)
1 - Charger error";
CM_ SG_ 2566852855 BATT_vBrickUnderWar_1 "0 - Brick voltage okay (default)
1 - Brick undervoltage warning";
CM_ SG_ 2566852855 BATT_vBrickUnderSev_1 "0 - Brick voltage okay (default)
1 - Brick undervoltage severe";
CM_ SG_ 2566852855 BATT_vBrickUnderMod_1 "0 - Brick voltage okay (default)
1 - Brick undervoltage moderate";
CM_ SG_ 2566852855 BATT_vBrickOverWar_1 "0 - Brick voltage okay (default)
1 - Brick overvoltage warning";
CM_ SG_ 2566852855 BATT_vBrickOverSev_1 "0 - Brick voltage okay (default)
1 - Brick overvoltage severe";
CM_ SG_ 2566852855 BATT_vBrickOverMod_1 "0 - Brick voltage okay (default)
1 - Brick overvoltage moderate";
CM_ SG_ 2566852855 BATT_vBrickImbalance_1 "0 - Battery brick voltage okay (default)
1 - Battery brick voltage imbalance";
CM_ SG_ 2566852855 BATT_loggerAlmostFull_1 "0 - Logger not almost full (default)
1 - Logger almost full (section >= 80%) ";
CM_ SG_ 2566852855 BATT_tempModuleUnderWar_1 "0 - Battery temperature okay (default)
1 - Battery under temperature warning";
CM_ SG_ 2566852855 BATT_tempModuleUnderSev_1 "0 - Battery temperature okay (default)
1 - Battery under temperature severe";
CM_ SG_ 2566852855 BATT_tempModuleUnderMod_1 "0 - Battery temperature okay (default)
1 - Battery under temperature moderate";
CM_ SG_ 2566852855 BATT_tempModuleOverWar_1 "0 - Battery temperature okay (default)
1 - Battery over temperature warning";
CM_ SG_ 2566852855 BATT_tempModuleOverSev_1 "0 - Battery temperature okay (default)
1 - Battery over temperature severe";
CM_ SG_ 2566852855 BATT_tempModuleOverMod_1 "0 - Battery temperature okay (default)
1 - Battery over temperature moderate";
CM_ SG_ 2566852855 BATT_tempBrickImbalance_1 "0 - Brick temperatures are balanced (default)
1 - Brick temperatures are imbalanced";
CM_ SG_ 2566852855 BATT_taskLockupError_1 "0 - Tasks okay (default)
1 - Task lockup error";
CM_ SG_ 2566852855 BATT_tempBoardOverWar_1 "0 - Ambient temperature okay (default)
1 - Ambient over temperature warning";
CM_ SG_ 2566852855 BATT_tempBoardOverSev_1 "0 - Temperature okay (default)
1 - Ambient over temperature severe";
CM_ SG_ 2566852855 BATT_tempBoardOverMod_1 "0 - Ambient temperature okay (default)
1 - Ambient over temparature moderate";
CM_ SG_ 2566852855 BATT_sensePackVoltError_1 "0 - Sensor okay (default)
1 - Sensor for pack voltage error";
CM_ SG_ 2566852855 BATT_senseLoadVoltError_1 "0 - Sensor okay (default)
1 - Sensor for load voltage error";
CM_ SG_ 2566852855 BATT_loggerFull_1 "0 - Logger not full (default)
1 - Logger full ";
CM_ SG_ 2566852855 BATT_senseCurrentError_1 "0 - Sensor okay (default)
1 - Sensor for current error";
CM_ SG_ 2566852855 BATT_senseBrickTempError_1 "0 - Sensor okay (default)
1 - Brick temperature sensor error";
CM_ SG_ 2566852855 BATT_resPackHigh_1 "0 - Battery pack resistance okay (default)
1 - Battery pack resistance high (High SOH-R)";
CM_ SG_ 2566852855 BATT_ramOverUtilError_1 "0 - RAM okay (default)
1 - RAM over utilization";
CM_ SG_ 2566852855 BATT_powerPackInsufficient_1 "0 - Battery pack power okay (default)
1 - Battery pack power insufficient";
CM_ SG_ 2566852855 BATT_packCellSoftShort_1 "0 - Battery back cells are okay (default)
1 - Battery pack cell soft short";
CM_ SG_ 2566852855 BATT_iOverHardware_1 "0 - Hardware current okay (default)
1 - Overcurrent in hardware";
CM_ SG_ 2566852855 BATT_fetOverTemp_1 "0 - FET temperature okay (default)
1 - Overtemp at FETs";
CM_ SG_ 2566852855 BATT_iOverDischarge_1 "0 - Discharge okay (default)
1 - Overcurrent during discharge";
CM_ SG_ 2566852855 BATT_iOverCharge_1 "0 - Charging okay (default)
1 - Overcurrent during charging";
CM_ SG_ 2566852855 BATT_inverterDriveMIA_1 "0 - Inverter drive present (default)
1 - Inverter drive MIA";
CM_ SG_ 2566852855 BATT_iUnderCharge_1 "0 - Normal charging (default)
1 -  Charging undercurrent (discharging)";
CM_ SG_ 2566852855 BATT_hostMIA_1 "0 - host communication open (default)
1 - host MIA";
CM_ SG_ 2566852855 BATT_fetDsgShorted_1 "0 - FETs are operational (default)
1 - FET is shorted";
CM_ SG_ 2566852855 BATT_fetDsgFailToClose_1 "0 - FETs are operational (default)
1 -  FET fail to close";
CM_ SG_ 2566852855 BATT_capLow_1 "0 - Battery capacity normal (SOH-C) (default)
1 - Low battery capacity (Low SOH-C)";
CM_ SG_ 2566852855 BATT_brickOverDischarge_1 "0 - Battery brick charge is normal (default)
1 - Battery brick is overdischarged";
CM_ SG_ 2566852855 BATT_brickOverCharge_1 "0 - Battery brick charge is normal (default)
1 - Battery brick is overcharged";
CM_ SG_ 2566852855 BATT_bmsProcessorError_1 "0 - No BMS processor failure (default)
1 - BMS processor failure";
CM_ SG_ 2566852855 BATT_bmsMemoryError_1 "0 - No BMS memory error
1 - BMS memory error";
CM_ SG_ 2566852855 BATT_afeError_1 "0 - No BMS AFE error (default)
1 - BMS AFE error";
CM_ BO_ 2566852856 "Message with flags from event matrix";
CM_ SG_ 2566852856 BATT_packModIdFault_2 "0 - Battery pack module ID okay (default)
1 - Battery pack module ID fault";
CM_ SG_ 2566852856 BATT_packModExitedFromBus_2 "0 - Battery pack modules OK (default)
1 - Battery pack module(s) exited from the bus during charge or drive";
CM_ SG_ 2566852856 BATT_packFetChgWelded_2 "0 - Battery pack module CHG FETs not welded (default)
1 - Battery pack module CHG FETs welded ";
CM_ SG_ 2566852856 BATT_packFetDsgWelded_2 "0 - Battery pack module DSG FETs not welded (default)
1 - Battery pack module DSG FETs welded ";
CM_ SG_ 2566852856 BATT_fetDsgShortedAux_2 "0 - FETs are operational (default)
1 - FET is shorted detected by auxiliary diagnostic";
CM_ SG_ 2566852856 BATT_fetChgShortedAux_2 "0 - FETs are operational (default)
1 - FET is shorted detected by auxiliary diagnostic";
CM_ SG_ 2566852856 BATT_prechargeFetFail_2 "0 - Precharge FET okay (default)
1 - Precharge FET failed";
CM_ SG_ 2566852856 BATT_abnormalResetReason_2 "0 - Reset reason okay (default)
1 - Abnormal reset reason";
CM_ SG_ 2566852856 BATT_prechargeTooSlow_2 "0 - Precharge okay (default)
1 - Precharge too slow";
CM_ SG_ 2566852856 BATT_prechargeTooFast_2 "0 - Precharge okay (default)
1 - Precharge too fast";
CM_ SG_ 2566852856 BATT_prechargeTimeout_2 "0 - Precharge okay (default)
1 - Precharge timeout";
CM_ SG_ 2566852856 BATT_fetChgShorted_2 "0 - FETs are operational (default)
1 - FET is shorted";
CM_ SG_ 2566852856 BATT_fetChgFailToClose_2 "0 - FETs are operational (default)
1 -  FET fail to close";
CM_ SG_ 2566852856 BATT_packModSelectFault_2 "0 - Battery pack module selection okay (default)
1 - Battery pack module selection fault";
CM_ SG_ 2566852856 BATT_packModConnectFault_2 "0 - Battery pack module connection okay (default)
1 - Battery pack module connection fault";
CM_ SG_ 2566852856 BATT_packModMIA_2 "0 - Battery pack modules not MIA (default)
1 - Battery pack module MIA";
CM_ SG_ 2566852856 BATT_packModImbalance_2 "0 - Battery pack modules balanced (default)
1 - Battery pack module imblance present";
CM_ SG_ 2566852856 BATT_afeFault_2 "0 - BMS AFE okay (default)
1 - BMS AFE fault";
CM_ SG_ 2566852856 BATT_chargerMIA_2 "0 - Charger communications okay (default)
1 - Charger MIA";
CM_ SG_ 2566852856 BATT_chargerError_2 "0 - Charger working as intended (default)
1 - Charger error";
CM_ SG_ 2566852856 BATT_vBrickUnderWar_2 "0 - Brick voltage okay (default)
1 - Brick undervoltage warning";
CM_ SG_ 2566852856 BATT_vBrickUnderSev_2 "0 - Brick voltage okay (default)
1 - Brick undervoltage severe";
CM_ SG_ 2566852856 BATT_vBrickUnderMod_2 "0 - Brick voltage okay (default)
1 - Brick undervoltage moderate";
CM_ SG_ 2566852856 BATT_vBrickOverWar_2 "0 - Brick voltage okay (default)
1 - Brick overvoltage warning";
CM_ SG_ 2566852856 BATT_vBrickOverSev_2 "0 - Brick voltage okay (default)
1 - Brick overvoltage severe";
CM_ SG_ 2566852856 BATT_vBrickOverMod_2 "0 - Brick voltage okay (default)
1 - Brick overvoltage moderate";
CM_ SG_ 2566852856 BATT_vBrickImbalance_2 "0 - Battery brick voltage okay (default)
1 - Battery brick voltage imbalance";
CM_ SG_ 2566852856 BATT_loggerAlmostFull_2 "0 - Logger not almost full (default)
1 - Logger almost full (section >= 80%) ";
CM_ SG_ 2566852856 BATT_tempModuleUnderWar_2 "0 - Battery temperature okay (default)
1 - Battery under temperature warning";
CM_ SG_ 2566852856 BATT_tempModuleUnderSev_2 "0 - Battery temperature okay (default)
1 - Battery under temperature severe";
CM_ SG_ 2566852856 BATT_tempModuleUnderMod_2 "0 - Battery temperature okay (default)
1 - Battery under temperature moderate";
CM_ SG_ 2566852856 BATT_tempModuleOverWar_2 "0 - Battery temperature okay (default)
1 - Battery over temperature warning";
CM_ SG_ 2566852856 BATT_tempModuleOverSev_2 "0 - Battery temperature okay (default)
1 - Battery over temperature severe";
CM_ SG_ 2566852856 BATT_tempModuleOverMod_2 "0 - Battery temperature okay (default)
1 - Battery over temperature moderate";
CM_ SG_ 2566852856 BATT_tempBrickImbalance_2 "0 - Brick temperatures are balanced (default)
1 - Brick temperatures are imbalanced";
CM_ SG_ 2566852856 BATT_taskLockupError_2 "0 - Tasks okay (default)
1 - Task lockup error";
CM_ SG_ 2566852856 BATT_tempBoardOverWar_2 "0 - Ambient temperature okay (default)
1 - Ambient over temperature warning";
CM_ SG_ 2566852856 BATT_tempBoardOverSev_2 "0 - Temperature okay (default)
1 - Ambient over temperature severe";
CM_ SG_ 2566852856 BATT_tempBoardOverMod_2 "0 - Ambient temperature okay (default)
1 - Ambient over temparature moderate";
CM_ SG_ 2566852856 BATT_sensePackVoltError_2 "0 - Sensor okay (default)
1 - Sensor for pack voltage error";
CM_ SG_ 2566852856 BATT_senseLoadVoltError_2 "0 - Sensor okay (default)
1 - Sensor for load voltage error";
CM_ SG_ 2566852856 BATT_loggerFull_2 "0 - Logger not full (default)
1 - Logger full ";
CM_ SG_ 2566852856 BATT_senseCurrentError_2 "0 - Sensor okay (default)
1 - Sensor for current error";
CM_ SG_ 2566852856 BATT_senseBrickTempError_2 "0 - Sensor okay (default)
1 - Brick temperature sensor error";
CM_ SG_ 2566852856 BATT_resPackHigh_2 "0 - Battery pack resistance okay (default)
1 - Battery pack resistance high (High SOH-R)";
CM_ SG_ 2566852856 BATT_ramOverUtilError_2 "0 - RAM okay (default)
1 - RAM over utilization";
CM_ SG_ 2566852856 BATT_powerPackInsufficient_2 "0 - Battery pack power okay (default)
1 - Battery pack power insufficient";
CM_ SG_ 2566852856 BATT_packCellSoftShort_2 "0 - Battery back cells are okay (default)
1 - Battery pack cell soft short";
CM_ SG_ 2566852856 BATT_iOverHardware_2 "0 - Hardware current okay (default)
1 - Overcurrent in hardware";
CM_ SG_ 2566852856 BATT_fetOverTemp_2 "0 - FET temperature okay (default)
1 - Overtemp at FETs";
CM_ SG_ 2566852856 BATT_iOverDischarge_2 "0 - Discharge okay (default)
1 - Overcurrent during discharge";
CM_ SG_ 2566852856 BATT_iOverCharge_2 "0 - Charging okay (default)
1 - Overcurrent during charging";
CM_ SG_ 2566852856 BATT_inverterDriveMIA_2 "0 - Inverter drive present (default)
1 - Inverter drive MIA";
CM_ SG_ 2566852856 BATT_iUnderCharge_2 "0 - Normal charging (default)
1 -  Charging undercurrent (discharging)";
CM_ SG_ 2566852856 BATT_hostMIA_2 "0 - host communication open (default)
1 - host MIA";
CM_ SG_ 2566852856 BATT_fetDsgShorted_2 "0 - FETs are operational (default)
1 - FET is shorted";
CM_ SG_ 2566852856 BATT_fetDsgFailToClose_2 "0 - FETs are operational (default)
1 -  FET fail to close";
CM_ SG_ 2566852856 BATT_capLow_2 "0 - Battery capacity normal (SOH-C) (default)
1 - Low battery capacity (Low SOH-C)";
CM_ SG_ 2566852856 BATT_brickOverDischarge_2 "0 - Battery brick charge is normal (default)
1 - Battery brick is overdischarged";
CM_ SG_ 2566852856 BATT_brickOverCharge_2 "0 - Battery brick charge is normal (default)
1 - Battery brick is overcharged";
CM_ SG_ 2566852856 BATT_bmsProcessorError_2 "0 - No BMS processor failure (default)
1 - BMS processor failure";
CM_ SG_ 2566852856 BATT_bmsMemoryError_2 "0 - No BMS memory error
1 - BMS memory error";
CM_ SG_ 2566852856 BATT_afeError_2 "0 - No BMS AFE error (default)
1 - BMS AFE error";
CM_ BO_ 2566852857 "Message with flags from event matrix";
CM_ SG_ 2566852857 BATT_packModIdFault_3 "0 - Battery pack module ID okay (default)
1 - Battery pack module ID fault";
CM_ SG_ 2566852857 BATT_packModExitedFromBus_3 "0 - Battery pack modules OK (default)
1 - Battery pack module(s) exited from the bus during charge or drive";
CM_ SG_ 2566852857 BATT_packFetChgWelded_3 "0 - Battery pack module CHG FETs not welded (default)
1 - Battery pack module CHG FETs welded ";
CM_ SG_ 2566852857 BATT_packFetDsgWelded_3 "0 - Battery pack module DSG FETs not welded (default)
1 - Battery pack module DSG FETs welded ";
CM_ SG_ 2566852857 BATT_fetDsgShortedAux_3 "0 - FETs are operational (default)
1 - FET is shorted detected by auxiliary diagnostic";
CM_ SG_ 2566852857 BATT_fetChgShortedAux_3 "0 - FETs are operational (default)
1 - FET is shorted detected by auxiliary diagnostic";
CM_ SG_ 2566852857 BATT_prechargeFetFail_3 "0 - Precharge FET okay (default)
1 - Precharge FET failed";
CM_ SG_ 2566852857 BATT_abnormalResetReason_3 "0 - Reset reason okay (default)
1 - Abnormal reset reason";
CM_ SG_ 2566852857 BATT_prechargeTooSlow_3 "0 - Precharge okay (default)
1 - Precharge too slow";
CM_ SG_ 2566852857 BATT_prechargeTooFast_3 "0 - Precharge okay (default)
1 - Precharge too fast";
CM_ SG_ 2566852857 BATT_prechargeTimeout_3 "0 - Precharge okay (default)
1 - Precharge timeout";
CM_ SG_ 2566852857 BATT_fetChgShorted_3 "0 - FETs are operational (default)
1 - FET is shorted";
CM_ SG_ 2566852857 BATT_fetChgFailToClose_3 "0 - FETs are operational (default)
1 -  FET fail to close";
CM_ SG_ 2566852857 BATT_packModSelectFault_3 "0 - Battery pack module selection okay (default)
1 - Battery pack module selection fault";
CM_ SG_ 2566852857 BATT_packModConnectFault_3 "0 - Battery pack module connection okay (default)
1 - Battery pack module connection fault";
CM_ SG_ 2566852857 BATT_packModMIA_3 "0 - Battery pack modules not MIA (default)
1 - Battery pack module MIA";
CM_ SG_ 2566852857 BATT_packModImbalance_3 "0 - Battery pack modules balanced (default)
1 - Battery pack module imblance present";
CM_ SG_ 2566852857 BATT_afeFault_3 "0 - BMS AFE okay (default)
1 - BMS AFE fault";
CM_ SG_ 2566852857 BATT_chargerMIA_3 "0 - Charger communications okay (default)
1 - Charger MIA";
CM_ SG_ 2566852857 BATT_chargerError_3 "0 - Charger working as intended (default)
1 - Charger error";
CM_ SG_ 2566852857 BATT_vBrickUnderWar_3 "0 - Brick voltage okay (default)
1 - Brick undervoltage warning";
CM_ SG_ 2566852857 BATT_vBrickUnderSev_3 "0 - Brick voltage okay (default)
1 - Brick undervoltage severe";
CM_ SG_ 2566852857 BATT_vBrickUnderMod_3 "0 - Brick voltage okay (default)
1 - Brick undervoltage moderate";
CM_ SG_ 2566852857 BATT_vBrickOverWar_3 "0 - Brick voltage okay (default)
1 - Brick overvoltage warning";
CM_ SG_ 2566852857 BATT_vBrickOverSev_3 "0 - Brick voltage okay (default)
1 - Brick overvoltage severe";
CM_ SG_ 2566852857 BATT_vBrickOverMod_3 "0 - Brick voltage okay (default)
1 - Brick overvoltage moderate";
CM_ SG_ 2566852857 BATT_vBrickImbalance_3 "0 - Battery brick voltage okay (default)
1 - Battery brick voltage imbalance";
CM_ SG_ 2566852857 BATT_loggerAlmostFull_3 "0 - Logger not almost full (default)
1 - Logger almost full (section >= 80%) ";
CM_ SG_ 2566852857 BATT_tempModuleUnderWar_3 "0 - Battery temperature okay (default)
1 - Battery under temperature warning";
CM_ SG_ 2566852857 BATT_tempModuleUnderSev_3 "0 - Battery temperature okay (default)
1 - Battery under temperature severe";
CM_ SG_ 2566852857 BATT_tempModuleUnderMod_3 "0 - Battery temperature okay (default)
1 - Battery under temperature moderate";
CM_ SG_ 2566852857 BATT_tempModuleOverWar_3 "0 - Battery temperature okay (default)
1 - Battery over temperature warning";
CM_ SG_ 2566852857 BATT_tempModuleOverSev_3 "0 - Battery temperature okay (default)
1 - Battery over temperature severe";
CM_ SG_ 2566852857 BATT_tempModuleOverMod_3 "0 - Battery temperature okay (default)
1 - Battery over temperature moderate";
CM_ SG_ 2566852857 BATT_tempBrickImbalance_3 "0 - Brick temperatures are balanced (default)
1 - Brick temperatures are imbalanced";
CM_ SG_ 2566852857 BATT_taskLockupError_3 "0 - Tasks okay (default)
1 - Task lockup error";
CM_ SG_ 2566852857 BATT_tempBoardOverWar_3 "0 - Ambient temperature okay (default)
1 - Ambient over temperature warning";
CM_ SG_ 2566852857 BATT_tempBoardOverSev_3 "0 - Temperature okay (default)
1 - Ambient over temperature severe";
CM_ SG_ 2566852857 BATT_tempBoardOverMod_3 "0 - Ambient temperature okay (default)
1 - Ambient over temparature moderate";
CM_ SG_ 2566852857 BATT_sensePackVoltError_3 "0 - Sensor okay (default)
1 - Sensor for pack voltage error";
CM_ SG_ 2566852857 BATT_senseLoadVoltError_3 "0 - Sensor okay (default)
1 - Sensor for load voltage error";
CM_ SG_ 2566852857 BATT_loggerFull_3 "0 - Logger not full (default)
1 - Logger full ";
CM_ SG_ 2566852857 BATT_senseCurrentError_3 "0 - Sensor okay (default)
1 - Sensor for current error";
CM_ SG_ 2566852857 BATT_senseBrickTempError_3 "0 - Sensor okay (default)
1 - Brick temperature sensor error";
CM_ SG_ 2566852857 BATT_resPackHigh_3 "0 - Battery pack resistance okay (default)
1 - Battery pack resistance high (High SOH-R)";
CM_ SG_ 2566852857 BATT_ramOverUtilError_3 "0 - RAM okay (default)
1 - RAM over utilization";
CM_ SG_ 2566852857 BATT_powerPackInsufficient_3 "0 - Battery pack power okay (default)
1 - Battery pack power insufficient";
CM_ SG_ 2566852857 BATT_packCellSoftShort_3 "0 - Battery back cells are okay (default)
1 - Battery pack cell soft short";
CM_ SG_ 2566852857 BATT_iOverHardware_3 "0 - Hardware current okay (default)
1 - Overcurrent in hardware";
CM_ SG_ 2566852857 BATT_fetOverTemp_3 "0 - FET temperature okay (default)
1 - Overtemp at FETs";
CM_ SG_ 2566852857 BATT_iOverDischarge_3 "0 - Discharge okay (default)
1 - Overcurrent during discharge";
CM_ SG_ 2566852857 BATT_iOverCharge_3 "0 - Charging okay (default)
1 - Overcurrent during charging";
CM_ SG_ 2566852857 BATT_inverterDriveMIA_3 "0 - Inverter drive present (default)
1 - Inverter drive MIA";
CM_ SG_ 2566852857 BATT_iUnderCharge_3 "0 - Normal charging (default)
1 -  Charging undercurrent (discharging)";
CM_ SG_ 2566852857 BATT_hostMIA_3 "0 - host communication open (default)
1 - host MIA";
CM_ SG_ 2566852857 BATT_fetDsgShorted_3 "0 - FETs are operational (default)
1 - FET is shorted";
CM_ SG_ 2566852857 BATT_fetDsgFailToClose_3 "0 - FETs are operational (default)
1 -  FET fail to close";
CM_ SG_ 2566852857 BATT_capLow_3 "0 - Battery capacity normal (SOH-C) (default)
1 - Low battery capacity (Low SOH-C)";
CM_ SG_ 2566852857 BATT_brickOverDischarge_3 "0 - Battery brick charge is normal (default)
1 - Battery brick is overdischarged";
CM_ SG_ 2566852857 BATT_brickOverCharge_3 "0 - Battery brick charge is normal (default)
1 - Battery brick is overcharged";
CM_ SG_ 2566852857 BATT_bmsProcessorError_3 "0 - No BMS processor failure (default)
1 - BMS processor failure";
CM_ SG_ 2566852857 BATT_bmsMemoryError_3 "0 - No BMS memory error
1 - BMS memory error";
CM_ SG_ 2566852857 BATT_afeError_3 "0 - No BMS AFE error (default)
1 - BMS AFE error";
CM_ BO_ 2566852858 "Message with flags from event matrix";
CM_ SG_ 2566852858 BATT_packModIdFault_4 "0 - Battery pack module ID okay (default)
1 - Battery pack module ID fault";
CM_ SG_ 2566852858 BATT_packModExitedFromBus_4 "0 - Battery pack modules OK (default)
1 - Battery pack module(s) exited from the bus during charge or drive";
CM_ SG_ 2566852858 BATT_packFetChgWelded_4 "0 - Battery pack module CHG FETs not welded (default)
1 - Battery pack module CHG FETs welded ";
CM_ SG_ 2566852858 BATT_packFetDsgWelded_4 "0 - Battery pack module DSG FETs not welded (default)
1 - Battery pack module DSG FETs welded ";
CM_ SG_ 2566852858 BATT_fetDsgShortedAux_4 "0 - FETs are operational (default)
1 - FET is shorted detected by auxiliary diagnostic";
CM_ SG_ 2566852858 BATT_fetChgShortedAux_4 "0 - FETs are operational (default)
1 - FET is shorted detected by auxiliary diagnostic";
CM_ SG_ 2566852858 BATT_prechargeFetFail_4 "0 - Precharge FET okay (default)
1 - Precharge FET failed";
CM_ SG_ 2566852858 BATT_abnormalResetReason_4 "0 - Reset reason okay (default)
1 - Abnormal reset reason";
CM_ SG_ 2566852858 BATT_prechargeTooSlow_4 "0 - Precharge okay (default)
1 - Precharge too slow";
CM_ SG_ 2566852858 BATT_prechargeTooFast_4 "0 - Precharge okay (default)
1 - Precharge too fast";
CM_ SG_ 2566852858 BATT_prechargeTimeout_4 "0 - Precharge okay (default)
1 - Precharge timeout";
CM_ SG_ 2566852858 BATT_fetChgShorted_4 "0 - FETs are operational (default)
1 - FET is shorted";
CM_ SG_ 2566852858 BATT_fetChgFailToClose_4 "0 - FETs are operational (default)
1 -  FET fail to close";
CM_ SG_ 2566852858 BATT_packModSelectFault_4 "0 - Battery pack module selection okay (default)
1 - Battery pack module selection fault";
CM_ SG_ 2566852858 BATT_packModConnectFault_4 "0 - Battery pack module connection okay (default)
1 - Battery pack module connection fault";
CM_ SG_ 2566852858 BATT_packModMIA_4 "0 - Battery pack modules not MIA (default)
1 - Battery pack module MIA";
CM_ SG_ 2566852858 BATT_packModImbalance_4 "0 - Battery pack modules balanced (default)
1 - Battery pack module imblance present";
CM_ SG_ 2566852858 BATT_afeFault_4 "0 - BMS AFE okay (default)
1 - BMS AFE fault";
CM_ SG_ 2566852858 BATT_chargerMIA_4 "0 - Charger communications okay (default)
1 - Charger MIA";
CM_ SG_ 2566852858 BATT_chargerError_4 "0 - Charger working as intended (default)
1 - Charger error";
CM_ SG_ 2566852858 BATT_vBrickUnderWar_4 "0 - Brick voltage okay (default)
1 - Brick undervoltage warning";
CM_ SG_ 2566852858 BATT_vBrickUnderSev_4 "0 - Brick voltage okay (default)
1 - Brick undervoltage severe";
CM_ SG_ 2566852858 BATT_vBrickUnderMod_4 "0 - Brick voltage okay (default)
1 - Brick undervoltage moderate";
CM_ SG_ 2566852858 BATT_vBrickOverWar_4 "0 - Brick voltage okay (default)
1 - Brick overvoltage warning";
CM_ SG_ 2566852858 BATT_vBrickOverSev_4 "0 - Brick voltage okay (default)
1 - Brick overvoltage severe";
CM_ SG_ 2566852858 BATT_vBrickOverMod_4 "0 - Brick voltage okay (default)
1 - Brick overvoltage moderate";
CM_ SG_ 2566852858 BATT_vBrickImbalance_4 "0 - Battery brick voltage okay (default)
1 - Battery brick voltage imbalance";
CM_ SG_ 2566852858 BATT_loggerAlmostFull_4 "0 - Logger not almost full (default)
1 - Logger almost full (section >= 80%) ";
CM_ SG_ 2566852858 BATT_tempModuleUnderWar_4 "0 - Battery temperature okay (default)
1 - Battery under temperature warning";
CM_ SG_ 2566852858 BATT_tempModuleUnderSev_4 "0 - Battery temperature okay (default)
1 - Battery under temperature severe";
CM_ SG_ 2566852858 BATT_tempModuleUnderMod_4 "0 - Battery temperature okay (default)
1 - Battery under temperature moderate";
CM_ SG_ 2566852858 BATT_tempModuleOverWar_4 "0 - Battery temperature okay (default)
1 - Battery over temperature warning";
CM_ SG_ 2566852858 BATT_tempModuleOverSev_4 "0 - Battery temperature okay (default)
1 - Battery over temperature severe";
CM_ SG_ 2566852858 BATT_tempModuleOverMod_4 "0 - Battery temperature okay (default)
1 - Battery over temperature moderate";
CM_ SG_ 2566852858 BATT_tempBrickImbalance_4 "0 - Brick temperatures are balanced (default)
1 - Brick temperatures are imbalanced";
CM_ SG_ 2566852858 BATT_taskLockupError_4 "0 - Tasks okay (default)
1 - Task lockup error";
CM_ SG_ 2566852858 BATT_tempBoardOverWar_4 "0 - Ambient temperature okay (default)
1 - Ambient over temperature warning";
CM_ SG_ 2566852858 BATT_tempBoardOverSev_4 "0 - Temperature okay (default)
1 - Ambient over temperature severe";
CM_ SG_ 2566852858 BATT_tempBoardOverMod_4 "0 - Ambient temperature okay (default)
1 - Ambient over temparature moderate";
CM_ SG_ 2566852858 BATT_sensePackVoltError_4 "0 - Sensor okay (default)
1 - Sensor for pack voltage error";
CM_ SG_ 2566852858 BATT_senseLoadVoltError_4 "0 - Sensor okay (default)
1 - Sensor for load voltage error";
CM_ SG_ 2566852858 BATT_loggerFull_4 "0 - Logger not full (default)
1 - Logger full ";
CM_ SG_ 2566852858 BATT_senseCurrentError_4 "0 - Sensor okay (default)
1 - Sensor for current error";
CM_ SG_ 2566852858 BATT_senseBrickTempError_4 "0 - Sensor okay (default)
1 - Brick temperature sensor error";
CM_ SG_ 2566852858 BATT_resPackHigh_4 "0 - Battery pack resistance okay (default)
1 - Battery pack resistance high (High SOH-R)";
CM_ SG_ 2566852858 BATT_ramOverUtilError_4 "0 - RAM okay (default)
1 - RAM over utilization";
CM_ SG_ 2566852858 BATT_powerPackInsufficient_4 "0 - Battery pack power okay (default)
1 - Battery pack power insufficient";
CM_ SG_ 2566852858 BATT_packCellSoftShort_4 "0 - Battery back cells are okay (default)
1 - Battery pack cell soft short";
CM_ SG_ 2566852858 BATT_iOverHardware_4 "0 - Hardware current okay (default)
1 - Overcurrent in hardware";
CM_ SG_ 2566852858 BATT_fetOverTemp_4 "0 - FET temperature okay (default)
1 - Overtemp at FETs";
CM_ SG_ 2566852858 BATT_iOverDischarge_4 "0 - Discharge okay (default)
1 - Overcurrent during discharge";
CM_ SG_ 2566852858 BATT_iOverCharge_4 "0 - Charging okay (default)
1 - Overcurrent during charging";
CM_ SG_ 2566852858 BATT_inverterDriveMIA_4 "0 - Inverter drive present (default)
1 - Inverter drive MIA";
CM_ SG_ 2566852858 BATT_iUnderCharge_4 "0 - Normal charging (default)
1 -  Charging undercurrent (discharging)";
CM_ SG_ 2566852858 BATT_hostMIA_4 "0 - host communication open (default)
1 - host MIA";
CM_ SG_ 2566852858 BATT_fetDsgShorted_4 "0 - FETs are operational (default)
1 - FET is shorted";
CM_ SG_ 2566852858 BATT_fetDsgFailToClose_4 "0 - FETs are operational (default)
1 -  FET fail to close";
CM_ SG_ 2566852858 BATT_capLow_4 "0 - Battery capacity normal (SOH-C) (default)
1 - Low battery capacity (Low SOH-C)";
CM_ SG_ 2566852858 BATT_brickOverDischarge_4 "0 - Battery brick charge is normal (default)
1 - Battery brick is overdischarged";
CM_ SG_ 2566852858 BATT_brickOverCharge_4 "0 - Battery brick charge is normal (default)
1 - Battery brick is overcharged";
CM_ SG_ 2566852858 BATT_bmsProcessorError_4 "0 - No BMS processor failure (default)
1 - BMS processor failure";
CM_ SG_ 2566852858 BATT_bmsMemoryError_4 "0 - No BMS memory error
1 - BMS memory error";
CM_ SG_ 2566852858 BATT_afeError_4 "0 - No BMS AFE error (default)
1 - BMS AFE error";
CM_ BO_ 2566852859 "Message with flags from event matrix";
CM_ SG_ 2566852859 BATT_packModIdFault_5 "0 - Battery pack module ID okay (default)
1 - Battery pack module ID fault";
CM_ SG_ 2566852859 BATT_packModExitedFromBus_5 "0 - Battery pack modules OK (default)
1 - Battery pack module(s) exited from the bus during charge or drive";
CM_ SG_ 2566852859 BATT_packFetChgWelded_5 "0 - Battery pack module CHG FETs not welded (default)
1 - Battery pack module CHG FETs welded ";
CM_ SG_ 2566852859 BATT_packFetDsgWelded_5 "0 - Battery pack module DSG FETs not welded (default)
1 - Battery pack module DSG FETs welded ";
CM_ SG_ 2566852859 BATT_fetDsgShortedAux_5 "0 - FETs are operational (default)
1 - FET is shorted detected by auxiliary diagnostic";
CM_ SG_ 2566852859 BATT_fetChgShortedAux_5 "0 - FETs are operational (default)
1 - FET is shorted detected by auxiliary diagnostic";
CM_ SG_ 2566852859 BATT_prechargeFetFail_5 "0 - Precharge FET okay (default)
1 - Precharge FET failed";
CM_ SG_ 2566852859 BATT_abnormalResetReason_5 "0 - Reset reason okay (default)
1 - Abnormal reset reason";
CM_ SG_ 2566852859 BATT_prechargeTooSlow_5 "0 - Precharge okay (default)
1 - Precharge too slow";
CM_ SG_ 2566852859 BATT_prechargeTooFast_5 "0 - Precharge okay (default)
1 - Precharge too fast";
CM_ SG_ 2566852859 BATT_prechargeTimeout_5 "0 - Precharge okay (default)
1 - Precharge timeout";
CM_ SG_ 2566852859 BATT_fetChgShorted_5 "0 - FETs are operational (default)
1 - FET is shorted";
CM_ SG_ 2566852859 BATT_fetChgFailToClose_5 "0 - FETs are operational (default)
1 -  FET fail to close";
CM_ SG_ 2566852859 BATT_packModSelectFault_5 "0 - Battery pack module selection okay (default)
1 - Battery pack module selection fault";
CM_ SG_ 2566852859 BATT_packModConnectFault_5 "0 - Battery pack module connection okay (default)
1 - Battery pack module connection fault";
CM_ SG_ 2566852859 BATT_packModMIA_5 "0 - Battery pack modules not MIA (default)
1 - Battery pack module MIA";
CM_ SG_ 2566852859 BATT_packModImbalance_5 "0 - Battery pack modules balanced (default)
1 - Battery pack module imblance present";
CM_ SG_ 2566852859 BATT_afeFault_5 "0 - BMS AFE okay (default)
1 - BMS AFE fault";
CM_ SG_ 2566852859 BATT_chargerMIA_5 "0 - Charger communications okay (default)
1 - Charger MIA";
CM_ SG_ 2566852859 BATT_chargerError_5 "0 - Charger working as intended (default)
1 - Charger error";
CM_ SG_ 2566852859 BATT_vBrickUnderWar_5 "0 - Brick voltage okay (default)
1 - Brick undervoltage warning";
CM_ SG_ 2566852859 BATT_vBrickUnderSev_5 "0 - Brick voltage okay (default)
1 - Brick undervoltage severe";
CM_ SG_ 2566852859 BATT_vBrickUnderMod_5 "0 - Brick voltage okay (default)
1 - Brick undervoltage moderate";
CM_ SG_ 2566852859 BATT_vBrickOverWar_5 "0 - Brick voltage okay (default)
1 - Brick overvoltage warning";
CM_ SG_ 2566852859 BATT_vBrickOverSev_5 "0 - Brick voltage okay (default)
1 - Brick overvoltage severe";
CM_ SG_ 2566852859 BATT_vBrickOverMod_5 "0 - Brick voltage okay (default)
1 - Brick overvoltage moderate";
CM_ SG_ 2566852859 BATT_vBrickImbalance_5 "0 - Battery brick voltage okay (default)
1 - Battery brick voltage imbalance";
CM_ SG_ 2566852859 BATT_loggerAlmostFull_5 "0 - Logger not almost full (default)
1 - Logger almost full (section >= 80%) ";
CM_ SG_ 2566852859 BATT_tempModuleUnderWar_5 "0 - Battery temperature okay (default)
1 - Battery under temperature warning";
CM_ SG_ 2566852859 BATT_tempModuleUnderSev_5 "0 - Battery temperature okay (default)
1 - Battery under temperature severe";
CM_ SG_ 2566852859 BATT_tempModuleUnderMod_5 "0 - Battery temperature okay (default)
1 - Battery under temperature moderate";
CM_ SG_ 2566852859 BATT_tempModuleOverWar_5 "0 - Battery temperature okay (default)
1 - Battery over temperature warning";
CM_ SG_ 2566852859 BATT_tempModuleOverSev_5 "0 - Battery temperature okay (default)
1 - Battery over temperature severe";
CM_ SG_ 2566852859 BATT_tempModuleOverMod_5 "0 - Battery temperature okay (default)
1 - Battery over temperature moderate";
CM_ SG_ 2566852859 BATT_tempBrickImbalance_5 "0 - Brick temperatures are balanced (default)
1 - Brick temperatures are imbalanced";
CM_ SG_ 2566852859 BATT_taskLockupError_5 "0 - Tasks okay (default)
1 - Task lockup error";
CM_ SG_ 2566852859 BATT_tempBoardOverWar_5 "0 - Ambient temperature okay (default)
1 - Ambient over temperature warning";
CM_ SG_ 2566852859 BATT_tempBoardOverSev_5 "0 - Temperature okay (default)
1 - Ambient over temperature severe";
CM_ SG_ 2566852859 BATT_tempBoardOverMod_5 "0 - Ambient temperature okay (default)
1 - Ambient over temparature moderate";
CM_ SG_ 2566852859 BATT_sensePackVoltError_5 "0 - Sensor okay (default)
1 - Sensor for pack voltage error";
CM_ SG_ 2566852859 BATT_senseLoadVoltError_5 "0 - Sensor okay (default)
1 - Sensor for load voltage error";
CM_ SG_ 2566852859 BATT_loggerFull_5 "0 - Logger not full (default)
1 - Logger full ";
CM_ SG_ 2566852859 BATT_senseCurrentError_5 "0 - Sensor okay (default)
1 - Sensor for current error";
CM_ SG_ 2566852859 BATT_senseBrickTempError_5 "0 - Sensor okay (default)
1 - Brick temperature sensor error";
CM_ SG_ 2566852859 BATT_resPackHigh_5 "0 - Battery pack resistance okay (default)
1 - Battery pack resistance high (High SOH-R)";
CM_ SG_ 2566852859 BATT_ramOverUtilError_5 "0 - RAM okay (default)
1 - RAM over utilization";
CM_ SG_ 2566852859 BATT_powerPackInsufficient_5 "0 - Battery pack power okay (default)
1 - Battery pack power insufficient";
CM_ SG_ 2566852859 BATT_packCellSoftShort_5 "0 - Battery back cells are okay (default)
1 - Battery pack cell soft short";
CM_ SG_ 2566852859 BATT_iOverHardware_5 "0 - Hardware current okay (default)
1 - Overcurrent in hardware";
CM_ SG_ 2566852859 BATT_fetOverTemp_5 "0 - FET temperature okay (default)
1 - Overtemp at FETs";
CM_ SG_ 2566852859 BATT_iOverDischarge_5 "0 - Discharge okay (default)
1 - Overcurrent during discharge";
CM_ SG_ 2566852859 BATT_iOverCharge_5 "0 - Charging okay (default)
1 - Overcurrent during charging";
CM_ SG_ 2566852859 BATT_inverterDriveMIA_5 "0 - Inverter drive present (default)
1 - Inverter drive MIA";
CM_ SG_ 2566852859 BATT_iUnderCharge_5 "0 - Normal charging (default)
1 -  Charging undercurrent (discharging)";
CM_ SG_ 2566852859 BATT_hostMIA_5 "0 - host communication open (default)
1 - host MIA";
CM_ SG_ 2566852859 BATT_fetDsgShorted_5 "0 - FETs are operational (default)
1 - FET is shorted";
CM_ SG_ 2566852859 BATT_fetDsgFailToClose_5 "0 - FETs are operational (default)
1 -  FET fail to close";
CM_ SG_ 2566852859 BATT_capLow_5 "0 - Battery capacity normal (SOH-C) (default)
1 - Low battery capacity (Low SOH-C)";
CM_ SG_ 2566852859 BATT_brickOverDischarge_5 "0 - Battery brick charge is normal (default)
1 - Battery brick is overdischarged";
CM_ SG_ 2566852859 BATT_brickOverCharge_5 "0 - Battery brick charge is normal (default)
1 - Battery brick is overcharged";
CM_ SG_ 2566852859 BATT_bmsProcessorError_5 "0 - No BMS processor failure (default)
1 - BMS processor failure";
CM_ SG_ 2566852859 BATT_bmsMemoryError_5 "0 - No BMS memory error
1 - BMS memory error";
CM_ SG_ 2566852859 BATT_afeError_5 "0 - No BMS AFE error (default)
1 - BMS AFE error";
CM_ BO_ 2566852860 "Message with flags from event matrix";
CM_ SG_ 2566852860 BATT_packModIdFault_6 "0 - Battery pack module ID okay (default)
1 - Battery pack module ID fault";
CM_ SG_ 2566852860 BATT_packModExitedFromBus_6 "0 - Battery pack modules OK (default)
1 - Battery pack module(s) exited from the bus during charge or drive";
CM_ SG_ 2566852860 BATT_packFetChgWelded_6 "0 - Battery pack module CHG FETs not welded (default)
1 - Battery pack module CHG FETs welded ";
CM_ SG_ 2566852860 BATT_packFetDsgWelded_6 "0 - Battery pack module DSG FETs not welded (default)
1 - Battery pack module DSG FETs welded ";
CM_ SG_ 2566852860 BATT_fetDsgShortedAux_6 "0 - FETs are operational (default)
1 - FET is shorted detected by auxiliary diagnostic";
CM_ SG_ 2566852860 BATT_fetChgShortedAux_6 "0 - FETs are operational (default)
1 - FET is shorted detected by auxiliary diagnostic";
CM_ SG_ 2566852860 BATT_prechargeFetFail_6 "0 - Precharge FET okay (default)
1 - Precharge FET failed";
CM_ SG_ 2566852860 BATT_abnormalResetReason_6 "0 - Reset reason okay (default)
1 - Abnormal reset reason";
CM_ SG_ 2566852860 BATT_prechargeTooSlow_6 "0 - Precharge okay (default)
1 - Precharge too slow";
CM_ SG_ 2566852860 BATT_prechargeTooFast_6 "0 - Precharge okay (default)
1 - Precharge too fast";
CM_ SG_ 2566852860 BATT_prechargeTimeout_6 "0 - Precharge okay (default)
1 - Precharge timeout";
CM_ SG_ 2566852860 BATT_fetChgShorted_6 "0 - FETs are operational (default)
1 - FET is shorted";
CM_ SG_ 2566852860 BATT_fetChgFailToClose_6 "0 - FETs are operational (default)
1 -  FET fail to close";
CM_ SG_ 2566852860 BATT_packModSelectFault_6 "0 - Battery pack module selection okay (default)
1 - Battery pack module selection fault";
CM_ SG_ 2566852860 BATT_packModConnectFault_6 "0 - Battery pack module connection okay (default)
1 - Battery pack module connection fault";
CM_ SG_ 2566852860 BATT_packModMIA_6 "0 - Battery pack modules not MIA (default)
1 - Battery pack module MIA";
CM_ SG_ 2566852860 BATT_packModImbalance_6 "0 - Battery pack modules balanced (default)
1 - Battery pack module imblance present";
CM_ SG_ 2566852860 BATT_afeFault_6 "0 - BMS AFE okay (default)
1 - BMS AFE fault";
CM_ SG_ 2566852860 BATT_chargerMIA_6 "0 - Charger communications okay (default)
1 - Charger MIA";
CM_ SG_ 2566852860 BATT_chargerError_6 "0 - Charger working as intended (default)
1 - Charger error";
CM_ SG_ 2566852860 BATT_vBrickUnderWar_6 "0 - Brick voltage okay (default)
1 - Brick undervoltage warning";
CM_ SG_ 2566852860 BATT_vBrickUnderSev_6 "0 - Brick voltage okay (default)
1 - Brick undervoltage severe";
CM_ SG_ 2566852860 BATT_vBrickUnderMod_6 "0 - Brick voltage okay (default)
1 - Brick undervoltage moderate";
CM_ SG_ 2566852860 BATT_vBrickOverWar_6 "0 - Brick voltage okay (default)
1 - Brick overvoltage warning";
CM_ SG_ 2566852860 BATT_vBrickOverSev_6 "0 - Brick voltage okay (default)
1 - Brick overvoltage severe";
CM_ SG_ 2566852860 BATT_vBrickOverMod_6 "0 - Brick voltage okay (default)
1 - Brick overvoltage moderate";
CM_ SG_ 2566852860 BATT_vBrickImbalance_6 "0 - Battery brick voltage okay (default)
1 - Battery brick voltage imbalance";
CM_ SG_ 2566852860 BATT_loggerAlmostFull_6 "0 - Logger not almost full (default)
1 - Logger almost full (section >= 80%) ";
CM_ SG_ 2566852860 BATT_tempModuleUnderWar_6 "0 - Battery temperature okay (default)
1 - Battery under temperature warning";
CM_ SG_ 2566852860 BATT_tempModuleUnderSev_6 "0 - Battery temperature okay (default)
1 - Battery under temperature severe";
CM_ SG_ 2566852860 BATT_tempModuleUnderMod_6 "0 - Battery temperature okay (default)
1 - Battery under temperature moderate";
CM_ SG_ 2566852860 BATT_tempModuleOverWar_6 "0 - Battery temperature okay (default)
1 - Battery over temperature warning";
CM_ SG_ 2566852860 BATT_tempModuleOverSev_6 "0 - Battery temperature okay (default)
1 - Battery over temperature severe";
CM_ SG_ 2566852860 BATT_tempModuleOverMod_6 "0 - Battery temperature okay (default)
1 - Battery over temperature moderate";
CM_ SG_ 2566852860 BATT_tempBrickImbalance_6 "0 - Brick temperatures are balanced (default)
1 - Brick temperatures are imbalanced";
CM_ SG_ 2566852860 BATT_taskLockupError_6 "0 - Tasks okay (default)
1 - Task lockup error";
CM_ SG_ 2566852860 BATT_tempBoardOverWar_6 "0 - Ambient temperature okay (default)
1 - Ambient over temperature warning";
CM_ SG_ 2566852860 BATT_tempBoardOverSev_6 "0 - Temperature okay (default)
1 - Ambient over temperature severe";
CM_ SG_ 2566852860 BATT_tempBoardOverMod_6 "0 - Ambient temperature okay (default)
1 - Ambient over temparature moderate";
CM_ SG_ 2566852860 BATT_sensePackVoltError_6 "0 - Sensor okay (default)
1 - Sensor for pack voltage error";
CM_ SG_ 2566852860 BATT_senseLoadVoltError_6 "0 - Sensor okay (default)
1 - Sensor for load voltage error";
CM_ SG_ 2566852860 BATT_loggerFull_6 "0 - Logger not full (default)
1 - Logger full ";
CM_ SG_ 2566852860 BATT_senseCurrentError_6 "0 - Sensor okay (default)
1 - Sensor for current error";
CM_ SG_ 2566852860 BATT_senseBrickTempError_6 "0 - Sensor okay (default)
1 - Brick temperature sensor error";
CM_ SG_ 2566852860 BATT_resPackHigh_6 "0 - Battery pack resistance okay (default)
1 - Battery pack resistance high (High SOH-R)";
CM_ SG_ 2566852860 BATT_ramOverUtilError_6 "0 - RAM okay (default)
1 - RAM over utilization";
CM_ SG_ 2566852860 BATT_powerPackInsufficient_6 "0 - Battery pack power okay (default)
1 - Battery pack power insufficient";
CM_ SG_ 2566852860 BATT_packCellSoftShort_6 "0 - Battery back cells are okay (default)
1 - Battery pack cell soft short";
CM_ SG_ 2566852860 BATT_iOverHardware_6 "0 - Hardware current okay (default)
1 - Overcurrent in hardware";
CM_ SG_ 2566852860 BATT_fetOverTemp_6 "0 - FET temperature okay (default)
1 - Overtemp at FETs";
CM_ SG_ 2566852860 BATT_iOverDischarge_6 "0 - Discharge okay (default)
1 - Overcurrent during discharge";
CM_ SG_ 2566852860 BATT_iOverCharge_6 "0 - Charging okay (default)
1 - Overcurrent during charging";
CM_ SG_ 2566852860 BATT_inverterDriveMIA_6 "0 - Inverter drive present (default)
1 - Inverter drive MIA";
CM_ SG_ 2566852860 BATT_iUnderCharge_6 "0 - Normal charging (default)
1 -  Charging undercurrent (discharging)";
CM_ SG_ 2566852860 BATT_hostMIA_6 "0 - host communication open (default)
1 - host MIA";
CM_ SG_ 2566852860 BATT_fetDsgShorted_6 "0 - FETs are operational (default)
1 - FET is shorted";
CM_ SG_ 2566852860 BATT_fetDsgFailToClose_6 "0 - FETs are operational (default)
1 -  FET fail to close";
CM_ SG_ 2566852860 BATT_capLow_6 "0 - Battery capacity normal (SOH-C) (default)
1 - Low battery capacity (Low SOH-C)";
CM_ SG_ 2566852860 BATT_brickOverDischarge_6 "0 - Battery brick charge is normal (default)
1 - Battery brick is overdischarged";
CM_ SG_ 2566852860 BATT_brickOverCharge_6 "0 - Battery brick charge is normal (default)
1 - Battery brick is overcharged";
CM_ SG_ 2566852860 BATT_bmsProcessorError_6 "0 - No BMS processor failure (default)
1 - BMS processor failure";
CM_ SG_ 2566852860 BATT_bmsMemoryError_6 "0 - No BMS memory error
1 - BMS memory error";
CM_ SG_ 2566852860 BATT_afeError_6 "0 - No BMS AFE error (default)
1 - BMS AFE error";
CM_ BO_ 2566852861 "Message with flags from event matrix";
CM_ SG_ 2566852861 BATT_packModIdFault_7 "0 - Battery pack module ID okay (default)
1 - Battery pack module ID fault";
CM_ SG_ 2566852861 BATT_packModExitedFromBus_7 "0 - Battery pack modules OK (default)
1 - Battery pack module(s) exited from the bus during charge or drive";
CM_ SG_ 2566852861 BATT_packFetChgWelded_7 "0 - Battery pack module CHG FETs not welded (default)
1 - Battery pack module CHG FETs welded ";
CM_ SG_ 2566852861 BATT_packFetDsgWelded_7 "0 - Battery pack module DSG FETs not welded (default)
1 - Battery pack module DSG FETs welded ";
CM_ SG_ 2566852861 BATT_fetDsgShortedAux_7 "0 - FETs are operational (default)
1 - FET is shorted detected by auxiliary diagnostic";
CM_ SG_ 2566852861 BATT_fetChgShortedAux_7 "0 - FETs are operational (default)
1 - FET is shorted detected by auxiliary diagnostic";
CM_ SG_ 2566852861 BATT_prechargeFetFail_7 "0 - Precharge FET okay (default)
1 - Precharge FET failed";
CM_ SG_ 2566852861 BATT_abnormalResetReason_7 "0 - Reset reason okay (default)
1 - Abnormal reset reason";
CM_ SG_ 2566852861 BATT_prechargeTooSlow_7 "0 - Precharge okay (default)
1 - Precharge too slow";
CM_ SG_ 2566852861 BATT_prechargeTooFast_7 "0 - Precharge okay (default)
1 - Precharge too fast";
CM_ SG_ 2566852861 BATT_prechargeTimeout_7 "0 - Precharge okay (default)
1 - Precharge timeout";
CM_ SG_ 2566852861 BATT_fetChgShorted_7 "0 - FETs are operational (default)
1 - FET is shorted";
CM_ SG_ 2566852861 BATT_fetChgFailToClose_7 "0 - FETs are operational (default)
1 -  FET fail to close";
CM_ SG_ 2566852861 BATT_packModSelectFault_7 "0 - Battery pack module selection okay (default)
1 - Battery pack module selection fault";
CM_ SG_ 2566852861 BATT_packModConnectFault_7 "0 - Battery pack module connection okay (default)
1 - Battery pack module connection fault";
CM_ SG_ 2566852861 BATT_packModMIA_7 "0 - Battery pack modules not MIA (default)
1 - Battery pack module MIA";
CM_ SG_ 2566852861 BATT_packModImbalance_7 "0 - Battery pack modules balanced (default)
1 - Battery pack module imblance present";
CM_ SG_ 2566852861 BATT_afeFault_7 "0 - BMS AFE okay (default)
1 - BMS AFE fault";
CM_ SG_ 2566852861 BATT_chargerMIA_7 "0 - Charger communications okay (default)
1 - Charger MIA";
CM_ SG_ 2566852861 BATT_chargerError_7 "0 - Charger working as intended (default)
1 - Charger error";
CM_ SG_ 2566852861 BATT_vBrickUnderWar_7 "0 - Brick voltage okay (default)
1 - Brick undervoltage warning";
CM_ SG_ 2566852861 BATT_vBrickUnderSev_7 "0 - Brick voltage okay (default)
1 - Brick undervoltage severe";
CM_ SG_ 2566852861 BATT_vBrickUnderMod_7 "0 - Brick voltage okay (default)
1 - Brick undervoltage moderate";
CM_ SG_ 2566852861 BATT_vBrickOverWar_7 "0 - Brick voltage okay (default)
1 - Brick overvoltage warning";
CM_ SG_ 2566852861 BATT_vBrickOverSev_7 "0 - Brick voltage okay (default)
1 - Brick overvoltage severe";
CM_ SG_ 2566852861 BATT_vBrickOverMod_7 "0 - Brick voltage okay (default)
1 - Brick overvoltage moderate";
CM_ SG_ 2566852861 BATT_vBrickImbalance_7 "0 - Battery brick voltage okay (default)
1 - Battery brick voltage imbalance";
CM_ SG_ 2566852861 BATT_loggerAlmostFull_7 "0 - Logger not almost full (default)
1 - Logger almost full (section >= 80%) ";
CM_ SG_ 2566852861 BATT_tempModuleUnderWar_7 "0 - Battery temperature okay (default)
1 - Battery under temperature warning";
CM_ SG_ 2566852861 BATT_tempModuleUnderSev_7 "0 - Battery temperature okay (default)
1 - Battery under temperature severe";
CM_ SG_ 2566852861 BATT_tempModuleUnderMod_7 "0 - Battery temperature okay (default)
1 - Battery under temperature moderate";
CM_ SG_ 2566852861 BATT_tempModuleOverWar_7 "0 - Battery temperature okay (default)
1 - Battery over temperature warning";
CM_ SG_ 2566852861 BATT_tempModuleOverSev_7 "0 - Battery temperature okay (default)
1 - Battery over temperature severe";
CM_ SG_ 2566852861 BATT_tempModuleOverMod_7 "0 - Battery temperature okay (default)
1 - Battery over temperature moderate";
CM_ SG_ 2566852861 BATT_tempBrickImbalance_7 "0 - Brick temperatures are balanced (default)
1 - Brick temperatures are imbalanced";
CM_ SG_ 2566852861 BATT_taskLockupError_7 "0 - Tasks okay (default)
1 - Task lockup error";
CM_ SG_ 2566852861 BATT_tempBoardOverWar_7 "0 - Ambient temperature okay (default)
1 - Ambient over temperature warning";
CM_ SG_ 2566852861 BATT_tempBoardOverSev_7 "0 - Temperature okay (default)
1 - Ambient over temperature severe";
CM_ SG_ 2566852861 BATT_tempBoardOverMod_7 "0 - Ambient temperature okay (default)
1 - Ambient over temparature moderate";
CM_ SG_ 2566852861 BATT_sensePackVoltError_7 "0 - Sensor okay (default)
1 - Sensor for pack voltage error";
CM_ SG_ 2566852861 BATT_senseLoadVoltError_7 "0 - Sensor okay (default)
1 - Sensor for load voltage error";
CM_ SG_ 2566852861 BATT_loggerFull_7 "0 - Logger not full (default)
1 - Logger full ";
CM_ SG_ 2566852861 BATT_senseCurrentError_7 "0 - Sensor okay (default)
1 - Sensor for current error";
CM_ SG_ 2566852861 BATT_senseBrickTempError_7 "0 - Sensor okay (default)
1 - Brick temperature sensor error";
CM_ SG_ 2566852861 BATT_resPackHigh_7 "0 - Battery pack resistance okay (default)
1 - Battery pack resistance high (High SOH-R)";
CM_ SG_ 2566852861 BATT_ramOverUtilError_7 "0 - RAM okay (default)
1 - RAM over utilization";
CM_ SG_ 2566852861 BATT_powerPackInsufficient_7 "0 - Battery pack power okay (default)
1 - Battery pack power insufficient";
CM_ SG_ 2566852861 BATT_packCellSoftShort_7 "0 - Battery back cells are okay (default)
1 - Battery pack cell soft short";
CM_ SG_ 2566852861 BATT_iOverHardware_7 "0 - Hardware current okay (default)
1 - Overcurrent in hardware";
CM_ SG_ 2566852861 BATT_fetOverTemp_7 "0 - FET temperature okay (default)
1 - Overtemp at FETs";
CM_ SG_ 2566852861 BATT_iOverDischarge_7 "0 - Discharge okay (default)
1 - Overcurrent during discharge";
CM_ SG_ 2566852861 BATT_iOverCharge_7 "0 - Charging okay (default)
1 - Overcurrent during charging";
CM_ SG_ 2566852861 BATT_inverterDriveMIA_7 "0 - Inverter drive present (default)
1 - Inverter drive MIA";
CM_ SG_ 2566852861 BATT_iUnderCharge_7 "0 - Normal charging (default)
1 -  Charging undercurrent (discharging)";
CM_ SG_ 2566852861 BATT_hostMIA_7 "0 - host communication open (default)
1 - host MIA";
CM_ SG_ 2566852861 BATT_fetDsgShorted_7 "0 - FETs are operational (default)
1 - FET is shorted";
CM_ SG_ 2566852861 BATT_fetDsgFailToClose_7 "0 - FETs are operational (default)
1 -  FET fail to close";
CM_ SG_ 2566852861 BATT_capLow_7 "0 - Battery capacity normal (SOH-C) (default)
1 - Low battery capacity (Low SOH-C)";
CM_ SG_ 2566852861 BATT_brickOverDischarge_7 "0 - Battery brick charge is normal (default)
1 - Battery brick is overdischarged";
CM_ SG_ 2566852861 BATT_brickOverCharge_7 "0 - Battery brick charge is normal (default)
1 - Battery brick is overcharged";
CM_ SG_ 2566852861 BATT_bmsProcessorError_7 "0 - No BMS processor failure (default)
1 - BMS processor failure";
CM_ SG_ 2566852861 BATT_bmsMemoryError_7 "0 - No BMS memory error
1 - BMS memory error";
CM_ SG_ 2566852861 BATT_afeError_7 "0 - No BMS AFE error (default)
1 - BMS AFE error";
CM_ BO_ 2566852862 "Message with flags from event matrix";
CM_ SG_ 2566852862 BATT_packModIdFault_8 "0 - Battery pack module ID okay (default)
1 - Battery pack module ID fault";
CM_ SG_ 2566852862 BATT_packModExitedFromBus_8 "0 - Battery pack modules OK (default)
1 - Battery pack module(s) exited from the bus during charge or drive";
CM_ SG_ 2566852862 BATT_packFetChgWelded_8 "0 - Battery pack module CHG FETs not welded (default)
1 - Battery pack module CHG FETs welded ";
CM_ SG_ 2566852862 BATT_packFetDsgWelded_8 "0 - Battery pack module DSG FETs not welded (default)
1 - Battery pack module DSG FETs welded ";
CM_ SG_ 2566852862 BATT_fetDsgShortedAux_8 "0 - FETs are operational (default)
1 - FET is shorted detected by auxiliary diagnostic";
CM_ SG_ 2566852862 BATT_fetChgShortedAux_8 "0 - FETs are operational (default)
1 - FET is shorted detected by auxiliary diagnostic";
CM_ SG_ 2566852862 BATT_prechargeFetFail_8 "0 - Precharge FET okay (default)
1 - Precharge FET failed";
CM_ SG_ 2566852862 BATT_abnormalResetReason_8 "0 - Reset reason okay (default)
1 - Abnormal reset reason";
CM_ SG_ 2566852862 BATT_prechargeTooSlow_8 "0 - Precharge okay (default)
1 - Precharge too slow";
CM_ SG_ 2566852862 BATT_prechargeTooFast_8 "0 - Precharge okay (default)
1 - Precharge too fast";
CM_ SG_ 2566852862 BATT_prechargeTimeout_8 "0 - Precharge okay (default)
1 - Precharge timeout";
CM_ SG_ 2566852862 BATT_fetChgShorted_8 "0 - FETs are operational (default)
1 - FET is shorted";
CM_ SG_ 2566852862 BATT_fetChgFailToClose_8 "0 - FETs are operational (default)
1 -  FET fail to close";
CM_ SG_ 2566852862 BATT_packModSelectFault_8 "0 - Battery pack module selection okay (default)
1 - Battery pack module selection fault";
CM_ SG_ 2566852862 BATT_packModConnectFault_8 "0 - Battery pack module connection okay (default)
1 - Battery pack module connection fault";
CM_ SG_ 2566852862 BATT_packModMIA_8 "0 - Battery pack modules not MIA (default)
1 - Battery pack module MIA";
CM_ SG_ 2566852862 BATT_packModImbalance_8 "0 - Battery pack modules balanced (default)
1 - Battery pack module imblance present";
CM_ SG_ 2566852862 BATT_afeFault_8 "0 - BMS AFE okay (default)
1 - BMS AFE fault";
CM_ SG_ 2566852862 BATT_chargerMIA_8 "0 - Charger communications okay (default)
1 - Charger MIA";
CM_ SG_ 2566852862 BATT_chargerError_8 "0 - Charger working as intended (default)
1 - Charger error";
CM_ SG_ 2566852862 BATT_vBrickUnderWar_8 "0 - Brick voltage okay (default)
1 - Brick undervoltage warning";
CM_ SG_ 2566852862 BATT_vBrickUnderSev_8 "0 - Brick voltage okay (default)
1 - Brick undervoltage severe";
CM_ SG_ 2566852862 BATT_vBrickUnderMod_8 "0 - Brick voltage okay (default)
1 - Brick undervoltage moderate";
CM_ SG_ 2566852862 BATT_vBrickOverWar_8 "0 - Brick voltage okay (default)
1 - Brick overvoltage warning";
CM_ SG_ 2566852862 BATT_vBrickOverSev_8 "0 - Brick voltage okay (default)
1 - Brick overvoltage severe";
CM_ SG_ 2566852862 BATT_vBrickOverMod_8 "0 - Brick voltage okay (default)
1 - Brick overvoltage moderate";
CM_ SG_ 2566852862 BATT_vBrickImbalance_8 "0 - Battery brick voltage okay (default)
1 - Battery brick voltage imbalance";
CM_ SG_ 2566852862 BATT_loggerAlmostFull_8 "0 - Logger not almost full (default)
1 - Logger almost full (section >= 80%) ";
CM_ SG_ 2566852862 BATT_tempModuleUnderWar_8 "0 - Battery temperature okay (default)
1 - Battery under temperature warning";
CM_ SG_ 2566852862 BATT_tempModuleUnderSev_8 "0 - Battery temperature okay (default)
1 - Battery under temperature severe";
CM_ SG_ 2566852862 BATT_tempModuleUnderMod_8 "0 - Battery temperature okay (default)
1 - Battery under temperature moderate";
CM_ SG_ 2566852862 BATT_tempModuleOverWar_8 "0 - Battery temperature okay (default)
1 - Battery over temperature warning";
CM_ SG_ 2566852862 BATT_tempModuleOverSev_8 "0 - Battery temperature okay (default)
1 - Battery over temperature severe";
CM_ SG_ 2566852862 BATT_tempModuleOverMod_8 "0 - Battery temperature okay (default)
1 - Battery over temperature moderate";
CM_ SG_ 2566852862 BATT_tempBrickImbalance_8 "0 - Brick temperatures are balanced (default)
1 - Brick temperatures are imbalanced";
CM_ SG_ 2566852862 BATT_taskLockupError_8 "0 - Tasks okay (default)
1 - Task lockup error";
CM_ SG_ 2566852862 BATT_tempBoardOverWar_8 "0 - Ambient temperature okay (default)
1 - Ambient over temperature warning";
CM_ SG_ 2566852862 BATT_tempBoardOverSev_8 "0 - Temperature okay (default)
1 - Ambient over temperature severe";
CM_ SG_ 2566852862 BATT_tempBoardOverMod_8 "0 - Ambient temperature okay (default)
1 - Ambient over temparature moderate";
CM_ SG_ 2566852862 BATT_sensePackVoltError_8 "0 - Sensor okay (default)
1 - Sensor for pack voltage error";
CM_ SG_ 2566852862 BATT_senseLoadVoltError_8 "0 - Sensor okay (default)
1 - Sensor for load voltage error";
CM_ SG_ 2566852862 BATT_loggerFull_8 "0 - Logger not full (default)
1 - Logger full ";
CM_ SG_ 2566852862 BATT_senseCurrentError_8 "0 - Sensor okay (default)
1 - Sensor for current error";
CM_ SG_ 2566852862 BATT_senseBrickTempError_8 "0 - Sensor okay (default)
1 - Brick temperature sensor error";
CM_ SG_ 2566852862 BATT_resPackHigh_8 "0 - Battery pack resistance okay (default)
1 - Battery pack resistance high (High SOH-R)";
CM_ SG_ 2566852862 BATT_ramOverUtilError_8 "0 - RAM okay (default)
1 - RAM over utilization";
CM_ SG_ 2566852862 BATT_powerPackInsufficient_8 "0 - Battery pack power okay (default)
1 - Battery pack power insufficient";
CM_ SG_ 2566852862 BATT_packCellSoftShort_8 "0 - Battery back cells are okay (default)
1 - Battery pack cell soft short";
CM_ SG_ 2566852862 BATT_iOverHardware_8 "0 - Hardware current okay (default)
1 - Overcurrent in hardware";
CM_ SG_ 2566852862 BATT_fetOverTemp_8 "0 - FET temperature okay (default)
1 - Overtemp at FETs";
CM_ SG_ 2566852862 BATT_iOverDischarge_8 "0 - Discharge okay (default)
1 - Overcurrent during discharge";
CM_ SG_ 2566852862 BATT_iOverCharge_8 "0 - Charging okay (default)
1 - Overcurrent during charging";
CM_ SG_ 2566852862 BATT_inverterDriveMIA_8 "0 - Inverter drive present (default)
1 - Inverter drive MIA";
CM_ SG_ 2566852862 BATT_iUnderCharge_8 "0 - Normal charging (default)
1 -  Charging undercurrent (discharging)";
CM_ SG_ 2566852862 BATT_hostMIA_8 "0 - host communication open (default)
1 - host MIA";
CM_ SG_ 2566852862 BATT_fetDsgShorted_8 "0 - FETs are operational (default)
1 - FET is shorted";
CM_ SG_ 2566852862 BATT_fetDsgFailToClose_8 "0 - FETs are operational (default)
1 -  FET fail to close";
CM_ SG_ 2566852862 BATT_capLow_8 "0 - Battery capacity normal (SOH-C) (default)
1 - Low battery capacity (Low SOH-C)";
CM_ SG_ 2566852862 BATT_brickOverDischarge_8 "0 - Battery brick charge is normal (default)
1 - Battery brick is overdischarged";
CM_ SG_ 2566852862 BATT_brickOverCharge_8 "0 - Battery brick charge is normal (default)
1 - Battery brick is overcharged";
CM_ SG_ 2566852862 BATT_bmsProcessorError_8 "0 - No BMS processor failure (default)
1 - BMS processor failure";
CM_ SG_ 2566852862 BATT_bmsMemoryError_8 "0 - No BMS memory error
1 - BMS memory error";
CM_ SG_ 2566852862 BATT_afeError_8 "0 - No BMS AFE error (default)
1 - BMS AFE error";
BA_DEF_ SG_  "SigType" ENUM "Default","Range","RangeSigned","ASCII","Discrete","Control","ReferencePGN","DTC","StringDelimiter","StringLength","StringLengthControl","MessageCounter","MessageChecksum";
BA_DEF_ SG_  "GenSigSendType" ENUM "Cyclic","OnWrite","OnWriteWithRepetition","OnChange","OnChangeWithRepetition","IfActive","IfActiveWithRepetition","NoSigSendType";
BA_DEF_ BO_  "GenMsgDiag" ENUM "No","Yes";
BA_DEF_ BO_  "GenMsgInstanced" STRING ;
BA_DEF_ SG_  "GenSigType" ENUM "Extended","Diagnostic","Standard","Modified";
BA_DEF_ BO_  "GenMsgCycleTime" INT 0 0;
BA_DEF_ SG_  "GenSigSNA" INT 0 65535;
BA_DEF_ SG_  "Access" ENUM "r","rw";
BA_DEF_ BO_  "VFrameFormat" ENUM "StandardCAN","ExtendedCAN","reserved","J1939PG";
BA_DEF_DEF_  "SigType" "Default";
BA_DEF_DEF_  "GenSigSendType" "Cyclic";
BA_DEF_DEF_  "GenMsgDiag" "No";
BA_DEF_DEF_  "GenMsgInstanced" "No";
BA_DEF_DEF_  "GenSigType" "Standard";
BA_DEF_DEF_  "GenMsgCycleTime" 0;
BA_DEF_DEF_  "GenSigSNA" 0;
BA_DEF_DEF_  "Access" "r";
BA_DEF_DEF_  "VFrameFormat" "J1939PG";
BA_ "GenMsgDiag" BO_ 2566852598 1;
BA_ "GenMsgInstanced" BO_ 2566851837 "False";
BA_ "GenMsgInstanced" BO_ 2566851838 "False";
BA_ "GenMsgInstanced" BO_ 2566851839 "False";
BA_ "GenMsgInstanced" BO_ 2566852342 "False";
BA_ "GenMsgInstanced" BO_ 2566852343 "False";
BA_ "GenMsgInstanced" BO_ 2566852344 "False";
BA_ "GenMsgInstanced" BO_ 2566852345 "False";
BA_ "GenMsgInstanced" BO_ 2566852346 "False";
BA_ "GenMsgInstanced" BO_ 2566852347 "False";
BA_ "GenMsgInstanced" BO_ 2566852348 "False";
BA_ "GenMsgInstanced" BO_ 2566852349 "False";
BA_ "GenMsgInstanced" BO_ 2566852350 "False";
BA_ "GenMsgInstanced" BO_ 2566852351 "False";
BA_ "GenMsgInstanced" BO_ 2566852598 "False";
BA_ "GenMsgInstanced" BO_ 2566852854 "False";
BA_ "GenMsgInstanced" BO_ 2566852855 "False";
BA_ "GenMsgInstanced" BO_ 2566852856 "False";
BA_ "GenMsgInstanced" BO_ 2566852857 "False";
BA_ "GenMsgInstanced" BO_ 2566852858 "False";
BA_ "GenMsgInstanced" BO_ 2566852859 "False";
BA_ "GenMsgInstanced" BO_ 2566852860 "False";
BA_ "GenMsgInstanced" BO_ 2566852861 "False";
BA_ "GenMsgInstanced" BO_ 2566852862 "False";
BA_ "GenMsgCycleTime" BO_ 2566851837 100;
BA_ "GenMsgCycleTime" BO_ 2566851838 100;
BA_ "GenMsgCycleTime" BO_ 2566851839 100;
BA_ "GenMsgCycleTime" BO_ 2566852342 100;
BA_ "GenMsgCycleTime" BO_ 2566852343 100;
BA_ "GenMsgCycleTime" BO_ 2566852344 100;
BA_ "GenMsgCycleTime" BO_ 2566852345 100;
BA_ "GenMsgCycleTime" BO_ 2566852346 100;
BA_ "GenMsgCycleTime" BO_ 2566852347 100;
BA_ "GenMsgCycleTime" BO_ 2566852348 100;
BA_ "GenMsgCycleTime" BO_ 2566852349 100;
BA_ "GenMsgCycleTime" BO_ 2566852350 100;
BA_ "GenMsgCycleTime" BO_ 2566852351 100;
BA_ "GenSigType" SG_ 2566851837 BATT_vMod_7 0;
BA_ "GenSigType" SG_ 2566851837 BATT_vModSumOfCells_7 0;
BA_ "GenSigType" SG_ 2566851837 BATT_iMod_7 0;
BA_ "GenSigType" SG_ 2566851837 BATT_iModFiltered_7 0;
BA_ "GenSigType" SG_ 2566851838 BATT_vMod_8 0;
BA_ "GenSigType" SG_ 2566851838 BATT_vModSumOfCells_8 0;
BA_ "GenSigType" SG_ 2566851838 BATT_iMod_8 0;
BA_ "GenSigType" SG_ 2566851838 BATT_iModFiltered_8 0;
BA_ "GenSigType" SG_ 2566851839 BATT_vMod_9 0;
BA_ "GenSigType" SG_ 2566851839 BATT_vModSumOfCells_9 0;
BA_ "GenSigType" SG_ 2566851839 BATT_iMod_9 0;
BA_ "GenSigType" SG_ 2566851839 BATT_iModFiltered_9 0;
BA_ "GenSigType" SG_ 2566852854 BATT_vBrickImbalance_0 1;
BA_ "GenSigType" SG_ 2566852854 BATT_vBrickUnderSev_0 1;
BA_ "GenSigType" SG_ 2566852854 BATT_vBrickOverSev_0 1;
BA_ "GenSigType" SG_ 2566852854 BATT_iOverHardware_0 1;
BA_ "GenSigType" SG_ 2566852854 BATT_capLow_0 1;
BA_ "GenSigType" SG_ 2566852854 BATT_tempModuleOverSev_0 1;
BA_ "GenSigType" SG_ 2566852854 BATT_fetDsgFailToClose_0 1;
BA_ "GenSigType" SG_ 2566852854 BATT_fetDsgShorted_0 1;
BA_ "GenSigType" SG_ 2566852854 BATT_afeFault_0 1;
BA_ "GenSigType" SG_ 2566852854 BATT_tempModuleOverWar_0 1;
BA_ "GenSigType" SG_ 2566852854 BATT_iOverDischarge_0 1;
BA_ "GenSigType" SG_ 2566852854 BATT_brickOverDischarge_0 1;
BA_ "GenSigType" SG_ 2566852854 BATT_packModMIA_0 1;
BA_ "GenSigType" SG_ 2566852854 BATT_afeError_0 1;
BA_ "GenSigType" SG_ 2566852854 BATT_bmsMemoryError_0 1;
BA_ "GenSigType" SG_ 2566852854 BATT_ramOverUtilError_0 1;
BA_ "GenSigType" SG_ 2566852854 BATT_loggerFull_0 1;
BA_ "GenSigType" SG_ 2566852854 BATT_tempBoardOverMod_0 1;
BA_ "GenSigType" SG_ 2566852854 BATT_sensePackVoltError_0 1;
BA_ "GenSigType" SG_ 2566852854 BATT_prechargeFetFail_0 1;
BA_ "GenSigType" SG_ 2566852854 BATT_fetChgShortedAux_0 1;
BA_ "GenSigType" SG_ 2566852854 BATT_fetOverTemp_0 1;
BA_ "GenSigType" SG_ 2566852854 BATT_packModExitedFromBus_0 1;
BA_ "GenSigType" SG_ 2566852854 BATT_packModSelectFault_0 1;
BA_ "GenSigType" SG_ 2566852854 BATT_packModConnectFault_0 1;
BA_ "GenSigType" SG_ 2566852854 BATT_fetChgFailToClose_0 1;
BA_ "GenSigType" SG_ 2566852854 BATT_resPackHigh_0 1;
BA_ "GenSigType" SG_ 2566852854 BATT_tempBrickImbalance_0 1;
BA_ "GenSigType" SG_ 2566852854 BATT_vBrickOverMod_0 1;
BA_ "GenSigType" SG_ 2566852854 BATT_chargerMIA_0 1;
BA_ "GenSigType" SG_ 2566852854 BATT_senseCurrentError_0 1;
BA_ "GenSigType" SG_ 2566852854 BATT_tempBoardOverWar_0 1;
BA_ "GenSigType" SG_ 2566852854 BATT_vBrickUnderWar_0 1;
BA_ "GenSigType" SG_ 2566852854 BATT_iUnderCharge_0 1;
BA_ "GenSigType" SG_ 2566852854 BATT_abnormalResetReason_0 1;
BA_ "GenSigType" SG_ 2566852854 BATT_tempModuleUnderSev_0 1;
BA_ "GenSigType" SG_ 2566852854 BATT_vBrickOverWar_0 1;
BA_ "GenSigType" SG_ 2566852854 BATT_hostMIA_0 1;
BA_ "GenSigType" SG_ 2566852854 BATT_inverterDriveMIA_0 1;
BA_ "GenSigType" SG_ 2566852854 BATT_tempModuleUnderMod_0 1;
BA_ "GenSigType" SG_ 2566852854 BATT_prechargeTooSlow_0 1;
BA_ "GenSigType" SG_ 2566852854 BATT_prechargeTimeout_0 1;
BA_ "GenSigType" SG_ 2566852854 BATT_loggerAlmostFull_0 1;
BA_ "GenSigType" SG_ 2566852854 BATT_bmsProcessorError_0 1;
BA_ "GenSigType" SG_ 2566852854 BATT_packCellSoftShort_0 1;
BA_ "GenSigType" SG_ 2566852854 BATT_brickOverCharge_0 1;
BA_ "GenSigType" SG_ 2566852854 BATT_senseLoadVoltError_0 1;
BA_ "GenSigType" SG_ 2566852854 BATT_tempModuleOverMod_0 1;
BA_ "GenSigType" SG_ 2566852854 BATT_packModImbalance_0 1;
BA_ "GenSigType" SG_ 2566852854 BATT_packModIdFault_0 1;
BA_ "GenSigType" SG_ 2566852854 BATT_packFetChgWelded_0 1;
BA_ "GenSigType" SG_ 2566852854 BATT_packFetDsgWelded_0 1;
BA_ "GenSigType" SG_ 2566852854 BATT_vBrickUnderMod_0 1;
BA_ "GenSigType" SG_ 2566852854 BATT_fetDsgShortedAux_0 1;
BA_ "GenSigType" SG_ 2566852854 BATT_prechargeTooFast_0 1;
BA_ "GenSigType" SG_ 2566852854 BATT_fetChgShorted_0 1;
BA_ "GenSigType" SG_ 2566852854 BATT_powerPackInsufficient_0 1;
BA_ "GenSigType" SG_ 2566852854 BATT_senseBrickTempError_0 1;
BA_ "GenSigType" SG_ 2566852854 BATT_chargerError_0 1;
BA_ "GenSigType" SG_ 2566852854 BATT_tempModuleUnderWar_0 1;
BA_ "GenSigType" SG_ 2566852854 BATT_taskLockupError_0 1;
BA_ "GenSigType" SG_ 2566852854 BATT_iOverCharge_0 1;
BA_ "GenSigType" SG_ 2566852854 BATT_tempBoardOverSev_0 1;
BA_ "GenSigType" SG_ 2566852855 BATT_fetChgShorted_1 1;
BA_ "GenSigType" SG_ 2566852855 BATT_chargerMIA_1 1;
BA_ "GenSigType" SG_ 2566852855 BATT_chargerError_1 1;
BA_ "GenSigType" SG_ 2566852855 BATT_vBrickOverWar_1 1;
BA_ "GenSigType" SG_ 2566852855 BATT_packFetChgWelded_1 1;
BA_ "GenSigType" SG_ 2566852855 BATT_packFetDsgWelded_1 1;
BA_ "GenSigType" SG_ 2566852855 BATT_packModExitedFromBus_1 1;
BA_ "GenSigType" SG_ 2566852855 BATT_vBrickImbalance_1 1;
BA_ "GenSigType" SG_ 2566852855 BATT_prechargeTooSlow_1 1;
BA_ "GenSigType" SG_ 2566852855 BATT_afeFault_1 1;
BA_ "GenSigType" SG_ 2566852855 BATT_packModSelectFault_1 1;
BA_ "GenSigType" SG_ 2566852855 BATT_packModConnectFault_1 1;
BA_ "GenSigType" SG_ 2566852855 BATT_packModIdFault_1 1;
BA_ "GenSigType" SG_ 2566852855 BATT_fetChgFailToClose_1 1;
BA_ "GenSigType" SG_ 2566852855 BATT_packModMIA_1 1;
BA_ "GenSigType" SG_ 2566852855 BATT_vBrickOverMod_1 1;
BA_ "GenSigType" SG_ 2566852855 BATT_packModImbalance_1 1;
BA_ "GenSigType" SG_ 2566852855 BATT_vBrickOverSev_1 1;
BA_ "GenSigType" SG_ 2566852855 BATT_vBrickUnderSev_1 1;
BA_ "GenSigType" SG_ 2566852855 BATT_fetChgShortedAux_1 1;
BA_ "GenSigType" SG_ 2566852855 BATT_prechargeTimeout_1 1;
BA_ "GenSigType" SG_ 2566852855 BATT_abnormalResetReason_1 1;
BA_ "GenSigType" SG_ 2566852855 BATT_fetDsgShortedAux_1 1;
BA_ "GenSigType" SG_ 2566852855 BATT_prechargeTooFast_1 1;
BA_ "GenSigType" SG_ 2566852855 BATT_prechargeFetFail_1 1;
BA_ "GenSigType" SG_ 2566852855 BATT_vBrickUnderWar_1 1;
BA_ "GenSigType" SG_ 2566852855 BATT_vBrickUnderMod_1 1;
BA_ "GenSigType" SG_ 2566852855 BATT_loggerAlmostFull_1 1;
BA_ "GenSigType" SG_ 2566852855 BATT_taskLockupError_1 1;
BA_ "GenSigType" SG_ 2566852855 BATT_tempModuleUnderWar_1 1;
BA_ "GenSigType" SG_ 2566852855 BATT_tempModuleUnderSev_1 1;
BA_ "GenSigType" SG_ 2566852855 BATT_tempModuleUnderMod_1 1;
BA_ "GenSigType" SG_ 2566852855 BATT_tempModuleOverWar_1 1;
BA_ "GenSigType" SG_ 2566852855 BATT_iOverHardware_1 1;
BA_ "GenSigType" SG_ 2566852855 BATT_tempModuleOverSev_1 1;
BA_ "GenSigType" SG_ 2566852855 BATT_tempModuleOverMod_1 1;
BA_ "GenSigType" SG_ 2566852855 BATT_bmsMemoryError_1 1;
BA_ "GenSigType" SG_ 2566852855 BATT_afeError_1 1;
BA_ "GenSigType" SG_ 2566852855 BATT_tempBrickImbalance_1 1;
BA_ "GenSigType" SG_ 2566852855 BATT_packCellSoftShort_1 1;
BA_ "GenSigType" SG_ 2566852855 BATT_fetOverTemp_1 1;
BA_ "GenSigType" SG_ 2566852855 BATT_brickOverCharge_1 1;
BA_ "GenSigType" SG_ 2566852855 BATT_fetDsgShorted_1 1;
BA_ "GenSigType" SG_ 2566852855 BATT_bmsProcessorError_1 1;
BA_ "GenSigType" SG_ 2566852855 BATT_tempBoardOverMod_1 1;
BA_ "GenSigType" SG_ 2566852855 BATT_iOverDischarge_1 1;
BA_ "GenSigType" SG_ 2566852855 BATT_loggerFull_1 1;
BA_ "GenSigType" SG_ 2566852855 BATT_tempBoardOverSev_1 1;
BA_ "GenSigType" SG_ 2566852855 BATT_tempBoardOverWar_1 1;
BA_ "GenSigType" SG_ 2566852855 BATT_ramOverUtilError_1 1;
BA_ "GenSigType" SG_ 2566852855 BATT_senseCurrentError_1 1;
BA_ "GenSigType" SG_ 2566852855 BATT_fetDsgFailToClose_1 1;
BA_ "GenSigType" SG_ 2566852855 BATT_capLow_1 1;
BA_ "GenSigType" SG_ 2566852855 BATT_brickOverDischarge_1 1;
BA_ "GenSigType" SG_ 2566852855 BATT_iUnderCharge_1 1;
BA_ "GenSigType" SG_ 2566852855 BATT_hostMIA_1 1;
BA_ "GenSigType" SG_ 2566852855 BATT_iOverCharge_1 1;
BA_ "GenSigType" SG_ 2566852855 BATT_inverterDriveMIA_1 1;
BA_ "GenSigType" SG_ 2566852855 BATT_powerPackInsufficient_1 1;
BA_ "GenSigType" SG_ 2566852855 BATT_senseLoadVoltError_1 1;
BA_ "GenSigType" SG_ 2566852855 BATT_sensePackVoltError_1 1;
BA_ "GenSigType" SG_ 2566852855 BATT_senseBrickTempError_1 1;
BA_ "GenSigType" SG_ 2566852855 BATT_resPackHigh_1 1;
BA_ "GenSigType" SG_ 2566852856 BATT_packModMIA_2 1;
BA_ "GenSigType" SG_ 2566852856 BATT_prechargeTimeout_2 1;
BA_ "GenSigType" SG_ 2566852856 BATT_packModConnectFault_2 1;
BA_ "GenSigType" SG_ 2566852856 BATT_packModExitedFromBus_2 1;
BA_ "GenSigType" SG_ 2566852856 BATT_prechargeTooSlow_2 1;
BA_ "GenSigType" SG_ 2566852856 BATT_fetChgFailToClose_2 1;
BA_ "GenSigType" SG_ 2566852856 BATT_fetChgShorted_2 1;
BA_ "GenSigType" SG_ 2566852856 BATT_packModSelectFault_2 1;
BA_ "GenSigType" SG_ 2566852856 BATT_prechargeTooFast_2 1;
BA_ "GenSigType" SG_ 2566852856 BATT_packModIdFault_2 1;
BA_ "GenSigType" SG_ 2566852856 BATT_prechargeFetFail_2 1;
BA_ "GenSigType" SG_ 2566852856 BATT_abnormalResetReason_2 1;
BA_ "GenSigType" SG_ 2566852856 BATT_fetChgShortedAux_2 1;
BA_ "GenSigType" SG_ 2566852856 BATT_fetDsgShortedAux_2 1;
BA_ "GenSigType" SG_ 2566852856 BATT_packFetChgWelded_2 1;
BA_ "GenSigType" SG_ 2566852856 BATT_packFetDsgWelded_2 1;
BA_ "GenSigType" SG_ 2566852856 BATT_senseCurrentError_2 1;
BA_ "GenSigType" SG_ 2566852856 BATT_senseBrickTempError_2 1;
BA_ "GenSigType" SG_ 2566852856 BATT_resPackHigh_2 1;
BA_ "GenSigType" SG_ 2566852856 BATT_ramOverUtilError_2 1;
BA_ "GenSigType" SG_ 2566852856 BATT_powerPackInsufficient_2 1;
BA_ "GenSigType" SG_ 2566852856 BATT_packCellSoftShort_2 1;
BA_ "GenSigType" SG_ 2566852856 BATT_iOverHardware_2 1;
BA_ "GenSigType" SG_ 2566852856 BATT_fetOverTemp_2 1;
BA_ "GenSigType" SG_ 2566852856 BATT_iOverDischarge_2 1;
BA_ "GenSigType" SG_ 2566852856 BATT_iOverCharge_2 1;
BA_ "GenSigType" SG_ 2566852856 BATT_inverterDriveMIA_2 1;
BA_ "GenSigType" SG_ 2566852856 BATT_iUnderCharge_2 1;
BA_ "GenSigType" SG_ 2566852856 BATT_hostMIA_2 1;
BA_ "GenSigType" SG_ 2566852856 BATT_fetDsgShorted_2 1;
BA_ "GenSigType" SG_ 2566852856 BATT_fetDsgFailToClose_2 1;
BA_ "GenSigType" SG_ 2566852856 BATT_capLow_2 1;
BA_ "GenSigType" SG_ 2566852856 BATT_brickOverDischarge_2 1;
BA_ "GenSigType" SG_ 2566852856 BATT_brickOverCharge_2 1;
BA_ "GenSigType" SG_ 2566852856 BATT_bmsProcessorError_2 1;
BA_ "GenSigType" SG_ 2566852856 BATT_bmsMemoryError_2 1;
BA_ "GenSigType" SG_ 2566852856 BATT_afeError_2 1;
BA_ "GenSigType" SG_ 2566852856 BATT_packModImbalance_2 1;
BA_ "GenSigType" SG_ 2566852856 BATT_afeFault_2 1;
BA_ "GenSigType" SG_ 2566852856 BATT_chargerMIA_2 1;
BA_ "GenSigType" SG_ 2566852856 BATT_chargerError_2 1;
BA_ "GenSigType" SG_ 2566852856 BATT_vBrickUnderWar_2 1;
BA_ "GenSigType" SG_ 2566852856 BATT_vBrickUnderSev_2 1;
BA_ "GenSigType" SG_ 2566852856 BATT_vBrickUnderMod_2 1;
BA_ "GenSigType" SG_ 2566852856 BATT_vBrickOverWar_2 1;
BA_ "GenSigType" SG_ 2566852856 BATT_vBrickOverSev_2 1;
BA_ "GenSigType" SG_ 2566852856 BATT_vBrickOverMod_2 1;
BA_ "GenSigType" SG_ 2566852856 BATT_vBrickImbalance_2 1;
BA_ "GenSigType" SG_ 2566852856 BATT_loggerAlmostFull_2 1;
BA_ "GenSigType" SG_ 2566852856 BATT_tempModuleUnderWar_2 1;
BA_ "GenSigType" SG_ 2566852856 BATT_tempModuleUnderSev_2 1;
BA_ "GenSigType" SG_ 2566852856 BATT_tempModuleUnderMod_2 1;
BA_ "GenSigType" SG_ 2566852856 BATT_tempModuleOverWar_2 1;
BA_ "GenSigType" SG_ 2566852856 BATT_tempModuleOverSev_2 1;
BA_ "GenSigType" SG_ 2566852856 BATT_tempModuleOverMod_2 1;
BA_ "GenSigType" SG_ 2566852856 BATT_tempBrickImbalance_2 1;
BA_ "GenSigType" SG_ 2566852856 BATT_taskLockupError_2 1;
BA_ "GenSigType" SG_ 2566852856 BATT_tempBoardOverWar_2 1;
BA_ "GenSigType" SG_ 2566852856 BATT_tempBoardOverSev_2 1;
BA_ "GenSigType" SG_ 2566852856 BATT_tempBoardOverMod_2 1;
BA_ "GenSigType" SG_ 2566852856 BATT_sensePackVoltError_2 1;
BA_ "GenSigType" SG_ 2566852856 BATT_senseLoadVoltError_2 1;
BA_ "GenSigType" SG_ 2566852856 BATT_loggerFull_2 1;
BA_ "GenSigType" SG_ 2566852857 BATT_sensePackVoltError_3 1;
BA_ "GenSigType" SG_ 2566852857 BATT_senseLoadVoltError_3 1;
BA_ "GenSigType" SG_ 2566852857 BATT_tempModuleOverWar_3 1;
BA_ "GenSigType" SG_ 2566852857 BATT_tempModuleUnderSev_3 1;
BA_ "GenSigType" SG_ 2566852857 BATT_loggerFull_3 1;
BA_ "GenSigType" SG_ 2566852857 BATT_resPackHigh_3 1;
BA_ "GenSigType" SG_ 2566852857 BATT_senseBrickTempError_3 1;
BA_ "GenSigType" SG_ 2566852857 BATT_senseCurrentError_3 1;
BA_ "GenSigType" SG_ 2566852857 BATT_tempBoardOverSev_3 1;
BA_ "GenSigType" SG_ 2566852857 BATT_tempBoardOverMod_3 1;
BA_ "GenSigType" SG_ 2566852857 BATT_taskLockupError_3 1;
BA_ "GenSigType" SG_ 2566852857 BATT_tempBoardOverWar_3 1;
BA_ "GenSigType" SG_ 2566852857 BATT_tempModuleOverSev_3 1;
BA_ "GenSigType" SG_ 2566852857 BATT_tempBrickImbalance_3 1;
BA_ "GenSigType" SG_ 2566852857 BATT_packModIdFault_3 1;
BA_ "GenSigType" SG_ 2566852857 BATT_packModExitedFromBus_3 1;
BA_ "GenSigType" SG_ 2566852857 BATT_packFetChgWelded_3 1;
BA_ "GenSigType" SG_ 2566852857 BATT_tempModuleUnderMod_3 1;
BA_ "GenSigType" SG_ 2566852857 BATT_packModImbalance_3 1;
BA_ "GenSigType" SG_ 2566852857 BATT_afeFault_3 1;
BA_ "GenSigType" SG_ 2566852857 BATT_packModConnectFault_3 1;
BA_ "GenSigType" SG_ 2566852857 BATT_packModMIA_3 1;
BA_ "GenSigType" SG_ 2566852857 BATT_fetChgFailToClose_3 1;
BA_ "GenSigType" SG_ 2566852857 BATT_packModSelectFault_3 1;
BA_ "GenSigType" SG_ 2566852857 BATT_prechargeTimeout_3 1;
BA_ "GenSigType" SG_ 2566852857 BATT_fetChgShorted_3 1;
BA_ "GenSigType" SG_ 2566852857 BATT_loggerAlmostFull_3 1;
BA_ "GenSigType" SG_ 2566852857 BATT_tempModuleUnderWar_3 1;
BA_ "GenSigType" SG_ 2566852857 BATT_vBrickOverMod_3 1;
BA_ "GenSigType" SG_ 2566852857 BATT_vBrickImbalance_3 1;
BA_ "GenSigType" SG_ 2566852857 BATT_prechargeTooSlow_3 1;
BA_ "GenSigType" SG_ 2566852857 BATT_prechargeTooFast_3 1;
BA_ "GenSigType" SG_ 2566852857 BATT_packFetDsgWelded_3 1;
BA_ "GenSigType" SG_ 2566852857 BATT_fetDsgShortedAux_3 1;
BA_ "GenSigType" SG_ 2566852857 BATT_fetChgShortedAux_3 1;
BA_ "GenSigType" SG_ 2566852857 BATT_prechargeFetFail_3 1;
BA_ "GenSigType" SG_ 2566852857 BATT_abnormalResetReason_3 1;
BA_ "GenSigType" SG_ 2566852857 BATT_chargerMIA_3 1;
BA_ "GenSigType" SG_ 2566852857 BATT_vBrickOverWar_3 1;
BA_ "GenSigType" SG_ 2566852857 BATT_vBrickOverSev_3 1;
BA_ "GenSigType" SG_ 2566852857 BATT_chargerError_3 1;
BA_ "GenSigType" SG_ 2566852857 BATT_vBrickUnderSev_3 1;
BA_ "GenSigType" SG_ 2566852857 BATT_vBrickUnderWar_3 1;
BA_ "GenSigType" SG_ 2566852857 BATT_vBrickUnderMod_3 1;
BA_ "GenSigType" SG_ 2566852857 BATT_tempModuleOverMod_3 1;
BA_ "GenSigType" SG_ 2566852857 BATT_iOverCharge_3 1;
BA_ "GenSigType" SG_ 2566852857 BATT_capLow_3 1;
BA_ "GenSigType" SG_ 2566852857 BATT_hostMIA_3 1;
BA_ "GenSigType" SG_ 2566852857 BATT_brickOverCharge_3 1;
BA_ "GenSigType" SG_ 2566852857 BATT_iUnderCharge_3 1;
BA_ "GenSigType" SG_ 2566852857 BATT_brickOverDischarge_3 1;
BA_ "GenSigType" SG_ 2566852857 BATT_iOverDischarge_3 1;
BA_ "GenSigType" SG_ 2566852857 BATT_bmsProcessorError_3 1;
BA_ "GenSigType" SG_ 2566852857 BATT_ramOverUtilError_3 1;
BA_ "GenSigType" SG_ 2566852857 BATT_powerPackInsufficient_3 1;
BA_ "GenSigType" SG_ 2566852857 BATT_packCellSoftShort_3 1;
BA_ "GenSigType" SG_ 2566852857 BATT_iOverHardware_3 1;
BA_ "GenSigType" SG_ 2566852857 BATT_fetOverTemp_3 1;
BA_ "GenSigType" SG_ 2566852857 BATT_inverterDriveMIA_3 1;
BA_ "GenSigType" SG_ 2566852857 BATT_fetDsgShorted_3 1;
BA_ "GenSigType" SG_ 2566852857 BATT_fetDsgFailToClose_3 1;
BA_ "GenSigType" SG_ 2566852857 BATT_bmsMemoryError_3 1;
BA_ "GenSigType" SG_ 2566852857 BATT_afeError_3 1;
BA_ "GenSigType" SG_ 2566852858 BATT_tempModuleUnderSev_4 1;
BA_ "GenSigType" SG_ 2566852858 BATT_tempModuleUnderMod_4 1;
BA_ "GenSigType" SG_ 2566852858 BATT_tempBoardOverMod_4 1;
BA_ "GenSigType" SG_ 2566852858 BATT_sensePackVoltError_4 1;
BA_ "GenSigType" SG_ 2566852858 BATT_senseLoadVoltError_4 1;
BA_ "GenSigType" SG_ 2566852858 BATT_loggerFull_4 1;
BA_ "GenSigType" SG_ 2566852858 BATT_packCellSoftShort_4 1;
BA_ "GenSigType" SG_ 2566852858 BATT_iOverHardware_4 1;
BA_ "GenSigType" SG_ 2566852858 BATT_capLow_4 1;
BA_ "GenSigType" SG_ 2566852858 BATT_brickOverDischarge_4 1;
BA_ "GenSigType" SG_ 2566852858 BATT_vBrickOverMod_4 1;
BA_ "GenSigType" SG_ 2566852858 BATT_vBrickImbalance_4 1;
BA_ "GenSigType" SG_ 2566852858 BATT_loggerAlmostFull_4 1;
BA_ "GenSigType" SG_ 2566852858 BATT_tempModuleUnderWar_4 1;
BA_ "GenSigType" SG_ 2566852858 BATT_resPackHigh_4 1;
BA_ "GenSigType" SG_ 2566852858 BATT_tempBoardOverWar_4 1;
BA_ "GenSigType" SG_ 2566852858 BATT_tempBoardOverSev_4 1;
BA_ "GenSigType" SG_ 2566852858 BATT_ramOverUtilError_4 1;
BA_ "GenSigType" SG_ 2566852858 BATT_powerPackInsufficient_4 1;
BA_ "GenSigType" SG_ 2566852858 BATT_tempModuleOverMod_4 1;
BA_ "GenSigType" SG_ 2566852858 BATT_fetDsgShorted_4 1;
BA_ "GenSigType" SG_ 2566852858 BATT_fetDsgFailToClose_4 1;
BA_ "GenSigType" SG_ 2566852858 BATT_vBrickOverWar_4 1;
BA_ "GenSigType" SG_ 2566852858 BATT_vBrickOverSev_4 1;
BA_ "GenSigType" SG_ 2566852858 BATT_tempBrickImbalance_4 1;
BA_ "GenSigType" SG_ 2566852858 BATT_taskLockupError_4 1;
BA_ "GenSigType" SG_ 2566852858 BATT_senseCurrentError_4 1;
BA_ "GenSigType" SG_ 2566852858 BATT_senseBrickTempError_4 1;
BA_ "GenSigType" SG_ 2566852858 BATT_iUnderCharge_4 1;
BA_ "GenSigType" SG_ 2566852858 BATT_hostMIA_4 1;
BA_ "GenSigType" SG_ 2566852858 BATT_vBrickUnderSev_4 1;
BA_ "GenSigType" SG_ 2566852858 BATT_vBrickUnderMod_4 1;
BA_ "GenSigType" SG_ 2566852858 BATT_tempModuleOverWar_4 1;
BA_ "GenSigType" SG_ 2566852858 BATT_tempModuleOverSev_4 1;
BA_ "GenSigType" SG_ 2566852858 BATT_iOverCharge_4 1;
BA_ "GenSigType" SG_ 2566852858 BATT_inverterDriveMIA_4 1;
BA_ "GenSigType" SG_ 2566852858 BATT_chargerMIA_4 1;
BA_ "GenSigType" SG_ 2566852858 BATT_chargerError_4 1;
BA_ "GenSigType" SG_ 2566852858 BATT_vBrickUnderWar_4 1;
BA_ "GenSigType" SG_ 2566852858 BATT_fetOverTemp_4 1;
BA_ "GenSigType" SG_ 2566852858 BATT_iOverDischarge_4 1;
BA_ "GenSigType" SG_ 2566852858 BATT_brickOverCharge_4 1;
BA_ "GenSigType" SG_ 2566852858 BATT_bmsProcessorError_4 1;
BA_ "GenSigType" SG_ 2566852858 BATT_bmsMemoryError_4 1;
BA_ "GenSigType" SG_ 2566852858 BATT_afeError_4 1;
BA_ "GenSigType" SG_ 2566852858 BATT_fetChgShortedAux_4 1;
BA_ "GenSigType" SG_ 2566852858 BATT_prechargeFetFail_4 1;
BA_ "GenSigType" SG_ 2566852858 BATT_fetDsgShortedAux_4 1;
BA_ "GenSigType" SG_ 2566852858 BATT_packFetDsgWelded_4 1;
BA_ "GenSigType" SG_ 2566852858 BATT_fetChgShorted_4 1;
BA_ "GenSigType" SG_ 2566852858 BATT_prechargeTooSlow_4 1;
BA_ "GenSigType" SG_ 2566852858 BATT_packFetChgWelded_4 1;
BA_ "GenSigType" SG_ 2566852858 BATT_afeFault_4 1;
BA_ "GenSigType" SG_ 2566852858 BATT_abnormalResetReason_4 1;
BA_ "GenSigType" SG_ 2566852858 BATT_fetChgFailToClose_4 1;
BA_ "GenSigType" SG_ 2566852858 BATT_prechargeTimeout_4 1;
BA_ "GenSigType" SG_ 2566852858 BATT_packModSelectFault_4 1;
BA_ "GenSigType" SG_ 2566852858 BATT_prechargeTooFast_4 1;
BA_ "GenSigType" SG_ 2566852858 BATT_packModImbalance_4 1;
BA_ "GenSigType" SG_ 2566852858 BATT_packModIdFault_4 1;
BA_ "GenSigType" SG_ 2566852858 BATT_packModMIA_4 1;
BA_ "GenSigType" SG_ 2566852858 BATT_packModConnectFault_4 1;
BA_ "GenSigType" SG_ 2566852858 BATT_packModExitedFromBus_4 1;
BA_ "GenSigType" SG_ 2566852859 BATT_loggerFull_5 1;
BA_ "GenSigType" SG_ 2566852859 BATT_senseCurrentError_5 1;
BA_ "GenSigType" SG_ 2566852859 BATT_senseBrickTempError_5 1;
BA_ "GenSigType" SG_ 2566852859 BATT_resPackHigh_5 1;
BA_ "GenSigType" SG_ 2566852859 BATT_fetOverTemp_5 1;
BA_ "GenSigType" SG_ 2566852859 BATT_iOverDischarge_5 1;
BA_ "GenSigType" SG_ 2566852859 BATT_iUnderCharge_5 1;
BA_ "GenSigType" SG_ 2566852859 BATT_hostMIA_5 1;
BA_ "GenSigType" SG_ 2566852859 BATT_sensePackVoltError_5 1;
BA_ "GenSigType" SG_ 2566852859 BATT_senseLoadVoltError_5 1;
BA_ "GenSigType" SG_ 2566852859 BATT_packCellSoftShort_5 1;
BA_ "GenSigType" SG_ 2566852859 BATT_iOverHardware_5 1;
BA_ "GenSigType" SG_ 2566852859 BATT_iOverCharge_5 1;
BA_ "GenSigType" SG_ 2566852859 BATT_inverterDriveMIA_5 1;
BA_ "GenSigType" SG_ 2566852859 BATT_tempBoardOverWar_5 1;
BA_ "GenSigType" SG_ 2566852859 BATT_tempBoardOverSev_5 1;
BA_ "GenSigType" SG_ 2566852859 BATT_tempBoardOverMod_5 1;
BA_ "GenSigType" SG_ 2566852859 BATT_ramOverUtilError_5 1;
BA_ "GenSigType" SG_ 2566852859 BATT_powerPackInsufficient_5 1;
BA_ "GenSigType" SG_ 2566852859 BATT_tempBrickImbalance_5 1;
BA_ "GenSigType" SG_ 2566852859 BATT_taskLockupError_5 1;
BA_ "GenSigType" SG_ 2566852859 BATT_bmsMemoryError_5 1;
BA_ "GenSigType" SG_ 2566852859 BATT_afeError_5 1;
BA_ "GenSigType" SG_ 2566852859 BATT_tempModuleOverSev_5 1;
BA_ "GenSigType" SG_ 2566852859 BATT_tempModuleOverMod_5 1;
BA_ "GenSigType" SG_ 2566852859 BATT_brickOverCharge_5 1;
BA_ "GenSigType" SG_ 2566852859 BATT_bmsProcessorError_5 1;
BA_ "GenSigType" SG_ 2566852859 BATT_tempModuleUnderMod_5 1;
BA_ "GenSigType" SG_ 2566852859 BATT_tempModuleOverWar_5 1;
BA_ "GenSigType" SG_ 2566852859 BATT_capLow_5 1;
BA_ "GenSigType" SG_ 2566852859 BATT_brickOverDischarge_5 1;
BA_ "GenSigType" SG_ 2566852859 BATT_tempModuleUnderWar_5 1;
BA_ "GenSigType" SG_ 2566852859 BATT_tempModuleUnderSev_5 1;
BA_ "GenSigType" SG_ 2566852859 BATT_fetDsgShorted_5 1;
BA_ "GenSigType" SG_ 2566852859 BATT_fetDsgFailToClose_5 1;
BA_ "GenSigType" SG_ 2566852859 BATT_packModIdFault_5 1;
BA_ "GenSigType" SG_ 2566852859 BATT_packModExitedFromBus_5 1;
BA_ "GenSigType" SG_ 2566852859 BATT_packFetChgWelded_5 1;
BA_ "GenSigType" SG_ 2566852859 BATT_packFetDsgWelded_5 1;
BA_ "GenSigType" SG_ 2566852859 BATT_fetDsgShortedAux_5 1;
BA_ "GenSigType" SG_ 2566852859 BATT_fetChgShortedAux_5 1;
BA_ "GenSigType" SG_ 2566852859 BATT_prechargeFetFail_5 1;
BA_ "GenSigType" SG_ 2566852859 BATT_abnormalResetReason_5 1;
BA_ "GenSigType" SG_ 2566852859 BATT_prechargeTooSlow_5 1;
BA_ "GenSigType" SG_ 2566852859 BATT_prechargeTooFast_5 1;
BA_ "GenSigType" SG_ 2566852859 BATT_prechargeTimeout_5 1;
BA_ "GenSigType" SG_ 2566852859 BATT_fetChgShorted_5 1;
BA_ "GenSigType" SG_ 2566852859 BATT_fetChgFailToClose_5 1;
BA_ "GenSigType" SG_ 2566852859 BATT_packModSelectFault_5 1;
BA_ "GenSigType" SG_ 2566852859 BATT_packModConnectFault_5 1;
BA_ "GenSigType" SG_ 2566852859 BATT_packModMIA_5 1;
BA_ "GenSigType" SG_ 2566852859 BATT_packModImbalance_5 1;
BA_ "GenSigType" SG_ 2566852859 BATT_afeFault_5 1;
BA_ "GenSigType" SG_ 2566852859 BATT_chargerMIA_5 1;
BA_ "GenSigType" SG_ 2566852859 BATT_vBrickOverWar_5 1;
BA_ "GenSigType" SG_ 2566852859 BATT_chargerError_5 1;
BA_ "GenSigType" SG_ 2566852859 BATT_vBrickUnderWar_5 1;
BA_ "GenSigType" SG_ 2566852859 BATT_vBrickUnderSev_5 1;
BA_ "GenSigType" SG_ 2566852859 BATT_vBrickUnderMod_5 1;
BA_ "GenSigType" SG_ 2566852859 BATT_vBrickOverSev_5 1;
BA_ "GenSigType" SG_ 2566852859 BATT_vBrickOverMod_5 1;
BA_ "GenSigType" SG_ 2566852859 BATT_vBrickImbalance_5 1;
BA_ "GenSigType" SG_ 2566852859 BATT_loggerAlmostFull_5 1;
BA_ "GenSigType" SG_ 2566852860 BATT_packFetDsgWelded_6 1;
BA_ "GenSigType" SG_ 2566852860 BATT_fetDsgShortedAux_6 1;
BA_ "GenSigType" SG_ 2566852860 BATT_packModIdFault_6 1;
BA_ "GenSigType" SG_ 2566852860 BATT_packModExitedFromBus_6 1;
BA_ "GenSigType" SG_ 2566852860 BATT_packFetChgWelded_6 1;
BA_ "GenSigType" SG_ 2566852860 BATT_fetChgShortedAux_6 1;
BA_ "GenSigType" SG_ 2566852860 BATT_prechargeFetFail_6 1;
BA_ "GenSigType" SG_ 2566852860 BATT_abnormalResetReason_6 1;
BA_ "GenSigType" SG_ 2566852860 BATT_sensePackVoltError_6 1;
BA_ "GenSigType" SG_ 2566852860 BATT_vBrickOverSev_6 1;
BA_ "GenSigType" SG_ 2566852860 BATT_packModSelectFault_6 1;
BA_ "GenSigType" SG_ 2566852860 BATT_packModConnectFault_6 1;
BA_ "GenSigType" SG_ 2566852860 BATT_vBrickUnderSev_6 1;
BA_ "GenSigType" SG_ 2566852860 BATT_tempModuleUnderSev_6 1;
BA_ "GenSigType" SG_ 2566852860 BATT_vBrickUnderWar_6 1;
BA_ "GenSigType" SG_ 2566852860 BATT_tempBoardOverWar_6 1;
BA_ "GenSigType" SG_ 2566852860 BATT_taskLockupError_6 1;
BA_ "GenSigType" SG_ 2566852860 BATT_ramOverUtilError_6 1;
BA_ "GenSigType" SG_ 2566852860 BATT_fetOverTemp_6 1;
BA_ "GenSigType" SG_ 2566852860 BATT_resPackHigh_6 1;
BA_ "GenSigType" SG_ 2566852860 BATT_iOverCharge_6 1;
BA_ "GenSigType" SG_ 2566852860 BATT_powerPackInsufficient_6 1;
BA_ "GenSigType" SG_ 2566852860 BATT_fetDsgFailToClose_6 1;
BA_ "GenSigType" SG_ 2566852860 BATT_senseBrickTempError_6 1;
BA_ "GenSigType" SG_ 2566852860 BATT_tempModuleOverMod_6 1;
BA_ "GenSigType" SG_ 2566852860 BATT_bmsMemoryError_6 1;
BA_ "GenSigType" SG_ 2566852860 BATT_senseCurrentError_6 1;
BA_ "GenSigType" SG_ 2566852860 BATT_tempBrickImbalance_6 1;
BA_ "GenSigType" SG_ 2566852860 BATT_tempModuleOverSev_6 1;
BA_ "GenSigType" SG_ 2566852860 BATT_iOverHardware_6 1;
BA_ "GenSigType" SG_ 2566852860 BATT_bmsProcessorError_6 1;
BA_ "GenSigType" SG_ 2566852860 BATT_capLow_6 1;
BA_ "GenSigType" SG_ 2566852860 BATT_hostMIA_6 1;
BA_ "GenSigType" SG_ 2566852860 BATT_inverterDriveMIA_6 1;
BA_ "GenSigType" SG_ 2566852860 BATT_prechargeTimeout_6 1;
BA_ "GenSigType" SG_ 2566852860 BATT_fetDsgShorted_6 1;
BA_ "GenSigType" SG_ 2566852860 BATT_iOverDischarge_6 1;
BA_ "GenSigType" SG_ 2566852860 BATT_brickOverCharge_6 1;
BA_ "GenSigType" SG_ 2566852860 BATT_afeFault_6 1;
BA_ "GenSigType" SG_ 2566852860 BATT_prechargeTooSlow_6 1;
BA_ "GenSigType" SG_ 2566852860 BATT_prechargeTooFast_6 1;
BA_ "GenSigType" SG_ 2566852860 BATT_vBrickUnderMod_6 1;
BA_ "GenSigType" SG_ 2566852860 BATT_chargerError_6 1;
BA_ "GenSigType" SG_ 2566852860 BATT_packModImbalance_6 1;
BA_ "GenSigType" SG_ 2566852860 BATT_chargerMIA_6 1;
BA_ "GenSigType" SG_ 2566852860 BATT_packModMIA_6 1;
BA_ "GenSigType" SG_ 2566852860 BATT_iUnderCharge_6 1;
BA_ "GenSigType" SG_ 2566852860 BATT_fetChgShorted_6 1;
BA_ "GenSigType" SG_ 2566852860 BATT_tempBoardOverSev_6 1;
BA_ "GenSigType" SG_ 2566852860 BATT_fetChgFailToClose_6 1;
BA_ "GenSigType" SG_ 2566852860 BATT_afeError_6 1;
BA_ "GenSigType" SG_ 2566852860 BATT_tempModuleOverWar_6 1;
BA_ "GenSigType" SG_ 2566852860 BATT_vBrickImbalance_6 1;
BA_ "GenSigType" SG_ 2566852860 BATT_vBrickOverWar_6 1;
BA_ "GenSigType" SG_ 2566852860 BATT_tempBoardOverMod_6 1;
BA_ "GenSigType" SG_ 2566852860 BATT_loggerFull_6 1;
BA_ "GenSigType" SG_ 2566852860 BATT_senseLoadVoltError_6 1;
BA_ "GenSigType" SG_ 2566852860 BATT_vBrickOverMod_6 1;
BA_ "GenSigType" SG_ 2566852860 BATT_packCellSoftShort_6 1;
BA_ "GenSigType" SG_ 2566852860 BATT_loggerAlmostFull_6 1;
BA_ "GenSigType" SG_ 2566852860 BATT_brickOverDischarge_6 1;
BA_ "GenSigType" SG_ 2566852860 BATT_tempModuleUnderMod_6 1;
BA_ "GenSigType" SG_ 2566852860 BATT_tempModuleUnderWar_6 1;
BA_ "GenSigType" SG_ 2566852861 BATT_fetChgFailToClose_7 1;
BA_ "GenSigType" SG_ 2566852861 BATT_packModSelectFault_7 1;
BA_ "GenSigType" SG_ 2566852861 BATT_packModConnectFault_7 1;
BA_ "GenSigType" SG_ 2566852861 BATT_bmsMemoryError_7 1;
BA_ "GenSigType" SG_ 2566852861 BATT_resPackHigh_7 1;
BA_ "GenSigType" SG_ 2566852861 BATT_tempModuleUnderWar_7 1;
BA_ "GenSigType" SG_ 2566852861 BATT_vBrickOverSev_7 1;
BA_ "GenSigType" SG_ 2566852861 BATT_sensePackVoltError_7 1;
BA_ "GenSigType" SG_ 2566852861 BATT_vBrickOverMod_7 1;
BA_ "GenSigType" SG_ 2566852861 BATT_tempModuleUnderSev_7 1;
BA_ "GenSigType" SG_ 2566852861 BATT_tempBoardOverSev_7 1;
BA_ "GenSigType" SG_ 2566852861 BATT_fetDsgFailToClose_7 1;
BA_ "GenSigType" SG_ 2566852861 BATT_tempBoardOverWar_7 1;
BA_ "GenSigType" SG_ 2566852861 BATT_vBrickOverWar_7 1;
BA_ "GenSigType" SG_ 2566852861 BATT_loggerAlmostFull_7 1;
BA_ "GenSigType" SG_ 2566852861 BATT_bmsProcessorError_7 1;
BA_ "GenSigType" SG_ 2566852861 BATT_vBrickUnderMod_7 1;
BA_ "GenSigType" SG_ 2566852861 BATT_senseCurrentError_7 1;
BA_ "GenSigType" SG_ 2566852861 BATT_senseBrickTempError_7 1;
BA_ "GenSigType" SG_ 2566852861 BATT_fetDsgShorted_7 1;
BA_ "GenSigType" SG_ 2566852861 BATT_loggerFull_7 1;
BA_ "GenSigType" SG_ 2566852861 BATT_iOverCharge_7 1;
BA_ "GenSigType" SG_ 2566852861 BATT_hostMIA_7 1;
BA_ "GenSigType" SG_ 2566852861 BATT_tempBrickImbalance_7 1;
BA_ "GenSigType" SG_ 2566852861 BATT_taskLockupError_7 1;
BA_ "GenSigType" SG_ 2566852861 BATT_iUnderCharge_7 1;
BA_ "GenSigType" SG_ 2566852861 BATT_powerPackInsufficient_7 1;
BA_ "GenSigType" SG_ 2566852861 BATT_brickOverDischarge_7 1;
BA_ "GenSigType" SG_ 2566852861 BATT_capLow_7 1;
BA_ "GenSigType" SG_ 2566852861 BATT_iOverDischarge_7 1;
BA_ "GenSigType" SG_ 2566852861 BATT_fetOverTemp_7 1;
BA_ "GenSigType" SG_ 2566852861 BATT_ramOverUtilError_7 1;
BA_ "GenSigType" SG_ 2566852861 BATT_packCellSoftShort_7 1;
BA_ "GenSigType" SG_ 2566852861 BATT_inverterDriveMIA_7 1;
BA_ "GenSigType" SG_ 2566852861 BATT_iOverHardware_7 1;
BA_ "GenSigType" SG_ 2566852861 BATT_brickOverCharge_7 1;
BA_ "GenSigType" SG_ 2566852861 BATT_packModMIA_7 1;
BA_ "GenSigType" SG_ 2566852861 BATT_afeError_7 1;
BA_ "GenSigType" SG_ 2566852861 BATT_tempModuleOverSev_7 1;
BA_ "GenSigType" SG_ 2566852861 BATT_tempBoardOverMod_7 1;
BA_ "GenSigType" SG_ 2566852861 BATT_tempModuleUnderMod_7 1;
BA_ "GenSigType" SG_ 2566852861 BATT_tempModuleOverMod_7 1;
BA_ "GenSigType" SG_ 2566852861 BATT_afeFault_7 1;
BA_ "GenSigType" SG_ 2566852861 BATT_tempModuleOverWar_7 1;
BA_ "GenSigType" SG_ 2566852861 BATT_packModImbalance_7 1;
BA_ "GenSigType" SG_ 2566852861 BATT_senseLoadVoltError_7 1;
BA_ "GenSigType" SG_ 2566852861 BATT_vBrickUnderWar_7 1;
BA_ "GenSigType" SG_ 2566852861 BATT_chargerMIA_7 1;
BA_ "GenSigType" SG_ 2566852861 BATT_vBrickImbalance_7 1;
BA_ "GenSigType" SG_ 2566852861 BATT_vBrickUnderSev_7 1;
BA_ "GenSigType" SG_ 2566852861 BATT_chargerError_7 1;
BA_ "GenSigType" SG_ 2566852861 BATT_prechargeTooFast_7 1;
BA_ "GenSigType" SG_ 2566852861 BATT_prechargeFetFail_7 1;
BA_ "GenSigType" SG_ 2566852861 BATT_abnormalResetReason_7 1;
BA_ "GenSigType" SG_ 2566852861 BATT_packFetChgWelded_7 1;
BA_ "GenSigType" SG_ 2566852861 BATT_packModIdFault_7 1;
BA_ "GenSigType" SG_ 2566852861 BATT_prechargeTimeout_7 1;
BA_ "GenSigType" SG_ 2566852861 BATT_fetChgShorted_7 1;
BA_ "GenSigType" SG_ 2566852861 BATT_packFetDsgWelded_7 1;
BA_ "GenSigType" SG_ 2566852861 BATT_packModExitedFromBus_7 1;
BA_ "GenSigType" SG_ 2566852861 BATT_prechargeTooSlow_7 1;
BA_ "GenSigType" SG_ 2566852861 BATT_fetDsgShortedAux_7 1;
BA_ "GenSigType" SG_ 2566852861 BATT_fetChgShortedAux_7 1;
BA_ "GenSigType" SG_ 2566852862 BATT_tempModuleOverMod_8 1;
BA_ "GenSigType" SG_ 2566852862 BATT_iUnderCharge_8 1;
BA_ "GenSigType" SG_ 2566852862 BATT_fetDsgFailToClose_8 1;
BA_ "GenSigType" SG_ 2566852862 BATT_capLow_8 1;
BA_ "GenSigType" SG_ 2566852862 BATT_fetDsgShorted_8 1;
BA_ "GenSigType" SG_ 2566852862 BATT_brickOverDischarge_8 1;
BA_ "GenSigType" SG_ 2566852862 BATT_bmsProcessorError_8 1;
BA_ "GenSigType" SG_ 2566852862 BATT_senseLoadVoltError_8 1;
BA_ "GenSigType" SG_ 2566852862 BATT_tempModuleOverWar_8 1;
BA_ "GenSigType" SG_ 2566852862 BATT_tempModuleOverSev_8 1;
BA_ "GenSigType" SG_ 2566852862 BATT_tempBoardOverMod_8 1;
BA_ "GenSigType" SG_ 2566852862 BATT_sensePackVoltError_8 1;
BA_ "GenSigType" SG_ 2566852862 BATT_inverterDriveMIA_8 1;
BA_ "GenSigType" SG_ 2566852862 BATT_hostMIA_8 1;
BA_ "GenSigType" SG_ 2566852862 BATT_tempBrickImbalance_8 1;
BA_ "GenSigType" SG_ 2566852862 BATT_taskLockupError_8 1;
BA_ "GenSigType" SG_ 2566852862 BATT_tempBoardOverWar_8 1;
BA_ "GenSigType" SG_ 2566852862 BATT_tempBoardOverSev_8 1;
BA_ "GenSigType" SG_ 2566852862 BATT_resPackHigh_8 1;
BA_ "GenSigType" SG_ 2566852862 BATT_ramOverUtilError_8 1;
BA_ "GenSigType" SG_ 2566852862 BATT_senseBrickTempError_8 1;
BA_ "GenSigType" SG_ 2566852862 BATT_senseCurrentError_8 1;
BA_ "GenSigType" SG_ 2566852862 BATT_loggerFull_8 1;
BA_ "GenSigType" SG_ 2566852862 BATT_bmsMemoryError_8 1;
BA_ "GenSigType" SG_ 2566852862 BATT_brickOverCharge_8 1;
BA_ "GenSigType" SG_ 2566852862 BATT_fetOverTemp_8 1;
BA_ "GenSigType" SG_ 2566852862 BATT_powerPackInsufficient_8 1;
BA_ "GenSigType" SG_ 2566852862 BATT_packCellSoftShort_8 1;
BA_ "GenSigType" SG_ 2566852862 BATT_iOverHardware_8 1;
BA_ "GenSigType" SG_ 2566852862 BATT_iOverDischarge_8 1;
BA_ "GenSigType" SG_ 2566852862 BATT_iOverCharge_8 1;
BA_ "GenSigType" SG_ 2566852862 BATT_afeError_8 1;
BA_ "GenSigType" SG_ 2566852862 BATT_vBrickUnderMod_8 1;
BA_ "GenSigType" SG_ 2566852862 BATT_packModImbalance_8 1;
BA_ "GenSigType" SG_ 2566852862 BATT_vBrickOverMod_8 1;
BA_ "GenSigType" SG_ 2566852862 BATT_packModMIA_8 1;
BA_ "GenSigType" SG_ 2566852862 BATT_packModExitedFromBus_8 1;
BA_ "GenSigType" SG_ 2566852862 BATT_loggerAlmostFull_8 1;
BA_ "GenSigType" SG_ 2566852862 BATT_prechargeTimeout_8 1;
BA_ "GenSigType" SG_ 2566852862 BATT_tempModuleUnderWar_8 1;
BA_ "GenSigType" SG_ 2566852862 BATT_prechargeTooFast_8 1;
BA_ "GenSigType" SG_ 2566852862 BATT_abnormalResetReason_8 1;
BA_ "GenSigType" SG_ 2566852862 BATT_fetChgShortedAux_8 1;
BA_ "GenSigType" SG_ 2566852862 BATT_vBrickUnderSev_8 1;
BA_ "GenSigType" SG_ 2566852862 BATT_packFetDsgWelded_8 1;
BA_ "GenSigType" SG_ 2566852862 BATT_tempModuleUnderSev_8 1;
BA_ "GenSigType" SG_ 2566852862 BATT_packFetChgWelded_8 1;
BA_ "GenSigType" SG_ 2566852862 BATT_vBrickUnderWar_8 1;
BA_ "GenSigType" SG_ 2566852862 BATT_prechargeFetFail_8 1;
BA_ "GenSigType" SG_ 2566852862 BATT_vBrickImbalance_8 1;
BA_ "GenSigType" SG_ 2566852862 BATT_chargerError_8 1;
BA_ "GenSigType" SG_ 2566852862 BATT_vBrickOverWar_8 1;
BA_ "GenSigType" SG_ 2566852862 BATT_chargerMIA_8 1;
BA_ "GenSigType" SG_ 2566852862 BATT_packModSelectFault_8 1;
BA_ "GenSigType" SG_ 2566852862 BATT_packModConnectFault_8 1;
BA_ "GenSigType" SG_ 2566852862 BATT_afeFault_8 1;
BA_ "GenSigType" SG_ 2566852862 BATT_fetDsgShortedAux_8 1;
BA_ "GenSigType" SG_ 2566852862 BATT_tempModuleUnderMod_8 1;
BA_ "GenSigType" SG_ 2566852862 BATT_vBrickOverSev_8 1;
BA_ "GenSigType" SG_ 2566852862 BATT_prechargeTooSlow_8 1;
BA_ "GenSigType" SG_ 2566852862 BATT_packModIdFault_8 1;
BA_ "GenSigType" SG_ 2566852862 BATT_fetChgFailToClose_8 1;
BA_ "GenSigType" SG_ 2566852862 BATT_fetChgShorted_8 1;
BA_ "GenSigSNA" SG_ 2566851837 BATT_vMod_7 65535;
BA_ "GenSigSNA" SG_ 2566851837 BATT_vModSumOfCells_7 65535;
BA_ "GenSigSNA" SG_ 2566851837 BATT_iMod_7 32767;
BA_ "GenSigSNA" SG_ 2566851837 BATT_iModFiltered_7 32767;
BA_ "GenSigSNA" SG_ 2566851838 BATT_vMod_8 65535;
BA_ "GenSigSNA" SG_ 2566851838 BATT_vModSumOfCells_8 65535;
BA_ "GenSigSNA" SG_ 2566851838 BATT_iMod_8 32767;
BA_ "GenSigSNA" SG_ 2566851838 BATT_iModFiltered_8 32767;
BA_ "GenSigSNA" SG_ 2566851839 BATT_vMod_9 65535;
BA_ "GenSigSNA" SG_ 2566851839 BATT_vModSumOfCells_9 65535;
BA_ "GenSigSNA" SG_ 2566851839 BATT_iMod_9 32767;
BA_ "GenSigSNA" SG_ 2566851839 BATT_iModFiltered_9 32767;
VAL_ 2566851837 BATT_vMod_7  65535 "SNA"  ;
VAL_ 2566851837 BATT_vModSumOfCells_7  65535 "SNA"  ;
VAL_ 2566851837 BATT_iMod_7  32767 "SNA"  ;
VAL_ 2566851837 BATT_iModFiltered_7  32767 "SNA"  ;
VAL_ 2566851838 BATT_vMod_8  65535 "SNA"  ;
VAL_ 2566851838 BATT_vModSumOfCells_8  65535 "SNA"  ;
VAL_ 2566851838 BATT_iMod_8  32767 "SNA"  ;
VAL_ 2566851838 BATT_iModFiltered_8  32767 "SNA"  ;
VAL_ 2566851839 BATT_vMod_9  65535 "SNA"  ;
VAL_ 2566851839 BATT_vModSumOfCells_9  65535 "SNA"  ;
VAL_ 2566851839 BATT_iMod_9  32767 "SNA"  ;
VAL_ 2566851839 BATT_iModFiltered_9  32767 "SNA"  ;
